VERSION ""

NS_ :

BS_:

BU_: Vector__XXX

BO_ 398 TxPDO_DeviceActual_14: 8 Vector__XXX
SG_ Device_dc_link_vol_14 : 0|16@1- (0.0625,0) [-2048|2047.9375] "V" Vector__XXX
SG_ Device_ambient_temp_14 : 16|16@1- (0.0625,0) [-2048|2047.9375] "°C" Vector__XXX
SG_ Device_dc_link_power_14 : 32|16@1- (0.016,0) [-524.288|524.272] "kW" Vector__XXX

BO_ 385 TxPDO_DeviceActual_1: 8 Vector__XXX
SG_ Device_dc_link_vol_1 : 0|16@1- (0.0625,0) [-2048|2047.9375] "V" Vector__XXX
SG_ Device_ambient_temp_1 : 16|16@1- (0.0625,0) [-2048|2047.9375] "°C" Vector__XXX
SG_ Device_dc_link_power_1 : 32|16@1- (0.016,0) [-524.288|524.272] "kW" Vector__XXX

BO_ 386 TxPDO_DeviceActual_2: 8 Vector__XXX
SG_ Device_dc_link_vol_2 : 0|16@1- (0.0625,0) [-2048|2047.9375] "V" Vector__XXX
SG_ Device_ambient_temp_2 : 16|16@1- (0.0625,0) [-2048|2047.9375] "°C" Vector__XXX
SG_ Device_dc_link_power_2 : 32|16@1- (0.016,0) [-524.288|524.272] "kW" Vector__XXX

BO_ 387 TxPDO_DeviceActual_3: 8 Vector__XXX
SG_ Device_dc_link_vol_3 : 0|16@1- (0.0625,0) [-2048|2047.9375] "V" Vector__XXX
SG_ Device_ambient_temp_3 : 16|16@1- (0.0625,0) [-2048|2047.9375] "°C" Vector__XXX
SG_ Device_dc_link_power_3 : 32|16@1- (0.016,0) [-524.288|524.272] "kW" Vector__XXX

BO_ 388 TxPDO_DeviceActual_4: 8 Vector__XXX
SG_ Device_dc_link_vol_4 : 0|16@1- (0.0625,0) [-2048|2047.9375] "V" Vector__XXX
SG_ Device_ambient_temp_4 : 16|16@1- (0.0625,0) [-2048|2047.9375] "°C" Vector__XXX
SG_ Device_dc_link_power_4 : 32|16@1- (0.016,0) [-524.288|524.272] "kW" Vector__XXX

BO_ 389 TxPDO_DeviceActual_5: 8 Vector__XXX
SG_ Device_dc_link_vol_5 : 0|16@1- (0.0625,0) [-2048|2047.9375] "V" Vector__XXX
SG_ Device_ambient_temp_5 : 16|16@1- (0.0625,0) [-2048|2047.9375] "°C" Vector__XXX
SG_ Device_dc_link_power_5 : 32|16@1- (0.016,0) [-524.288|524.272] "kW" Vector__XXX

BO_ 390 TxPDO_DeviceActual_6: 8 Vector__XXX
SG_ Device_dc_link_vol_6 : 0|16@1- (0.0625,0) [-2048|2047.9375] "V" Vector__XXX
SG_ Device_ambient_temp_6 : 16|16@1- (0.0625,0) [-2048|2047.9375] "°C" Vector__XXX
SG_ Device_dc_link_power_6 : 32|16@1- (0.016,0) [-524.288|524.272] "kW" Vector__XXX

BO_ 391 TxPDO_DeviceActual_7: 8 Vector__XXX
SG_ Device_dc_link_vol_7 : 0|16@1- (0.0625,0) [-2048|2047.9375] "V" Vector__XXX
SG_ Device_ambient_temp_7 : 16|16@1- (0.0625,0) [-2048|2047.9375] "°C" Vector__XXX
SG_ Device_dc_link_power_7 : 32|16@1- (0.016,0) [-524.288|524.272] "kW" Vector__XXX

BO_ 392 TxPDO_DeviceActual_8: 8 Vector__XXX
SG_ Device_dc_link_vol_8 : 0|16@1- (0.0625,0) [-2048|2047.9375] "V" Vector__XXX
SG_ Device_ambient_temp_8 : 16|16@1- (0.0625,0) [-2048|2047.9375] "°C" Vector__XXX
SG_ Device_dc_link_power_8 : 32|16@1- (0.016,0) [-524.288|524.272] "kW" Vector__XXX

BO_ 393 TxPDO_DeviceActual_9: 8 Vector__XXX
SG_ Device_dc_link_vol_9 : 0|16@1- (0.0625,0) [-2048|2047.9375] "V" Vector__XXX
SG_ Device_ambient_temp_9 : 16|16@1- (0.0625,0) [-2048|2047.9375] "°C" Vector__XXX
SG_ Device_dc_link_power_9 : 32|16@1- (0.016,0) [-524.288|524.272] "kW" Vector__XXX

BO_ 394 TxPDO_DeviceActual_10: 8 Vector__XXX
SG_ Device_dc_link_vol_10 : 0|16@1- (0.0625,0) [-2048|2047.9375] "V" Vector__XXX
SG_ Device_ambient_temp_10 : 16|16@1- (0.0625,0) [-2048|2047.9375] "°C" Vector__XXX
SG_ Device_dc_link_power_10 : 32|16@1- (0.016,0) [-524.288|524.272] "kW" Vector__XXX

BO_ 395 TxPDO_DeviceActual_11: 8 Vector__XXX
SG_ Device_dc_link_vol_11 : 0|16@1- (0.0625,0) [-2048|2047.9375] "V" Vector__XXX
SG_ Device_ambient_temp_11 : 16|16@1- (0.0625,0) [-2048|2047.9375] "°C" Vector__XXX
SG_ Device_dc_link_power_11 : 32|16@1- (0.016,0) [-524.288|524.272] "kW" Vector__XXX

BO_ 396 TxPDO_DeviceActual_12: 8 Vector__XXX
SG_ Device_dc_link_vol_12 : 0|16@1- (0.0625,0) [-2048|2047.9375] "V" Vector__XXX
SG_ Device_ambient_temp_12 : 16|16@1- (0.0625,0) [-2048|2047.9375] "°C" Vector__XXX
SG_ Device_dc_link_power_12 : 32|16@1- (0.016,0) [-524.288|524.272] "kW" Vector__XXX

BO_ 397 TxPDO_DeviceActual_13: 8 Vector__XXX
SG_ Device_dc_link_vol_13 : 0|16@1- (0.0625,0) [-2048|2047.9375] "V" Vector__XXX
SG_ Device_ambient_temp_13 : 16|16@1- (0.0625,0) [-2048|2047.9375] "°C" Vector__XXX
SG_ Device_dc_link_power_13 : 32|16@1- (0.016,0) [-524.288|524.272] "kW" Vector__XXX

BO_ 462 TxPDO_InverterAStatus_14: 8 Vector__XXX
SG_ Inverter_A_Statusword_14 : 0|7@1+ (1,0) [0|127] "" Vector__XXX
SG_ EVENTBUFFER_NEW_EVENT : 16|1@1+ (1,0) [0|1] "" Vector__XXX
SG_ EVENTBUFFER_OVERFLOW : 17|1@1+ (1,0) [0|1] "" Vector__XXX
SG_ POWERMODULE_TRIPZONE_OVERCURRE : 18|1@1+ (1,0) [0|1] "" Vector__XXX
SG_ POWERMODULE_CURRENT_OFFSET_INI : 19|1@1+ (1,0) [0|1] "" Vector__XXX
SG_ POWERMODULE_TEMPSENSOR_ERROR : 20|1@1+ (1,0) [0|1] "" Vector__XXX
SG_ POWERMODULE_TEMPERATURE_WARNIN : 21|1@1+ (1,0) [0|1] "" Vector__XXX
SG_ POWERMODULE_OVERTEMPERATURE : 22|1@1+ (1,0) [0|1] "" Vector__XXX
SG_ POWERMODULE_IXT_FAULT : 23|1@1+ (1,0) [0|1] "" Vector__XXX
SG_ POWERMODULE_SW_OVERCURRENT : 24|1@1+ (1,0) [0|1] "" Vector__XXX
SG_ POWERMODULE_PATTERNDATA_INCONS : 25|1@1+ (1,0) [0|1] "" Vector__XXX
SG_ DCBUS_TRIPZONE_OVERVOLTAGE : 26|1@1+ (1,0) [0|1] "" Vector__XXX
SG_ DCBUS_SW_OVERVOLTAGE : 27|1@1+ (1,0) [0|1] "" Vector__XXX
SG_ DCBUS_SW_UNDERVOLTAGE : 28|1@1+ (1,0) [0|1] "" Vector__XXX
SG_ NEIGHBOUR_FAULT : 29|1@1+ (1,0) [0|1] "" Vector__XXX
SG_ MOTOR_TEMPSENSOR_ERROR : 30|1@1+ (1,0) [0|1] "" Vector__XXX
SG_ MOTOR_TEMPERATURE_WARNING : 31|1@1+ (1,0) [0|1] "" Vector__XXX
SG_ MOTOR_OVERTEMPERATURE : 32|1@1+ (1,0) [0|1] "" Vector__XXX
SG_ MOTOR_STATOR_FREQ_TO_HIGH : 33|1@1+ (1,0) [0|1] "" Vector__XXX
SG_ SUPPLYVOLTAGE_ERROR : 34|1@1+ (1,0) [0|1] "" Vector__XXX
SG_ RPDO_TIMEOUT : 35|1@1+ (1,0) [0|1] "" Vector__XXX
SG_ NMT_NOT_OPERATIONAL : 36|1@1+ (1,0) [0|1] "" Vector__XXX
SG_ TASKOVERRUN : 37|1@1+ (1,0) [0|1] "" Vector__XXX
SG_ NETSYNC_ERROR : 38|1@1+ (1,0) [0|1] "" Vector__XXX
SG_ POSDEVICE_SIGNAL_TO_LOW : 39|1@1+ (1,0) [0|1] "" Vector__XXX
SG_ POSDEVICE_SIGNAL_TO_HIGH : 40|1@1+ (1,0) [0|1] "" Vector__XXX
SG_ RESOLVER_CALIBRATION_FAILED : 41|1@1+ (1,0) [0|1] "" Vector__XXX
SG_ SYSTEM_FAULT : 42|1@1+ (1,0) [0|1] "" Vector__XXX
SG_ INTERLOCK_OPEN : 43|1@1+ (1,0) [0|1] "" Vector__XXX
SG_ APPC_HAS_GATE_DRIVER_DISABLED : 44|1@1+ (1,0) [0|1] "" Vector__XXX
SG_ MOTOR_STALL_ERROR : 45|1@1+ (1,0) [0|1] "" Vector__XXX
SG_ AMBIENT_TEMPERATURE_WARNING : 46|1@1+ (1,0) [0|1] "" Vector__XXX
SG_ AMBIENT_OVERTEMPERATURE : 47|1@1+ (1,0) [0|1] "" Vector__XXX
SG_ AMBIENT_TEMPSENSOR_ERROR : 48|1@1+ (1,0) [0|1] "" Vector__XXX
SG_ POWERMODULE_CLAMPING_TIMEOUT : 49|1@1+ (1,0) [0|1] "" Vector__XXX
SG_ DCBUS_RIPPLE_TO_HIGH : 50|1@1+ (1,0) [0|1] "" Vector__XXX
SG_ MOTOR_I2XT_WARNING : 51|1@1+ (1,0) [0|1] "" Vector__XXX
SG_ MOTOR_I2XT_ERROR : 52|1@1+ (1,0) [0|1] "" Vector__XXX
SG_ MOTOR_FIELDWEAKENING_ERROR : 53|1@1+ (1,0) [0|1] "" Vector__XXX
SG_ INVALID_PARAMETER_COMBINATION : 54|1@1+ (1,0) [0|1] "" Vector__XXX
SG_ PLUG_COVER_SENSOR_SIGNAL_LOW : 55|1@1+ (1,0) [0|1] "" Vector__XXX
SG_ MOTOR_CONNECTION_TEST_FAILED : 56|1@1+ (1,0) [0|1] "" Vector__XXX
SG_ POWERMODULE_IXT_WARNING : 57|1@1+ (1,0) [0|1] "" Vector__XXX
SG_ ISOLATION_FAULT : 58|1@1+ (1,0) [0|1] "" Vector__XXX

BO_ 449 TxPDO_InverterAStatus_1: 8 Vector__XXX
SG_ Inverter_A_Statusword_1 : 0|7@1+ (1,0) [0|127] "" Vector__XXX
SG_ EVENTBUFFER_NEW_EVENT : 16|1@1+ (1,0) [0|1] "" Vector__XXX
SG_ EVENTBUFFER_OVERFLOW : 17|1@1+ (1,0) [0|1] "" Vector__XXX
SG_ POWERMODULE_TRIPZONE_OVERCURRE : 18|1@1+ (1,0) [0|1] "" Vector__XXX
SG_ POWERMODULE_CURRENT_OFFSET_INI : 19|1@1+ (1,0) [0|1] "" Vector__XXX
SG_ POWERMODULE_TEMPSENSOR_ERROR : 20|1@1+ (1,0) [0|1] "" Vector__XXX
SG_ POWERMODULE_TEMPERATURE_WARNIN : 21|1@1+ (1,0) [0|1] "" Vector__XXX
SG_ POWERMODULE_OVERTEMPERATURE : 22|1@1+ (1,0) [0|1] "" Vector__XXX
SG_ POWERMODULE_IXT_FAULT : 23|1@1+ (1,0) [0|1] "" Vector__XXX
SG_ POWERMODULE_SW_OVERCURRENT : 24|1@1+ (1,0) [0|1] "" Vector__XXX
SG_ POWERMODULE_PATTERNDATA_INCONS : 25|1@1+ (1,0) [0|1] "" Vector__XXX
SG_ DCBUS_TRIPZONE_OVERVOLTAGE : 26|1@1+ (1,0) [0|1] "" Vector__XXX
SG_ DCBUS_SW_OVERVOLTAGE : 27|1@1+ (1,0) [0|1] "" Vector__XXX
SG_ DCBUS_SW_UNDERVOLTAGE : 28|1@1+ (1,0) [0|1] "" Vector__XXX
SG_ NEIGHBOUR_FAULT : 29|1@1+ (1,0) [0|1] "" Vector__XXX
SG_ MOTOR_TEMPSENSOR_ERROR : 30|1@1+ (1,0) [0|1] "" Vector__XXX
SG_ MOTOR_TEMPERATURE_WARNING : 31|1@1+ (1,0) [0|1] "" Vector__XXX
SG_ MOTOR_OVERTEMPERATURE : 32|1@1+ (1,0) [0|1] "" Vector__XXX
SG_ MOTOR_STATOR_FREQ_TO_HIGH : 33|1@1+ (1,0) [0|1] "" Vector__XXX
SG_ SUPPLYVOLTAGE_ERROR : 34|1@1+ (1,0) [0|1] "" Vector__XXX
SG_ RPDO_TIMEOUT : 35|1@1+ (1,0) [0|1] "" Vector__XXX
SG_ NMT_NOT_OPERATIONAL : 36|1@1+ (1,0) [0|1] "" Vector__XXX
SG_ TASKOVERRUN : 37|1@1+ (1,0) [0|1] "" Vector__XXX
SG_ NETSYNC_ERROR : 38|1@1+ (1,0) [0|1] "" Vector__XXX
SG_ POSDEVICE_SIGNAL_TO_LOW : 39|1@1+ (1,0) [0|1] "" Vector__XXX
SG_ POSDEVICE_SIGNAL_TO_HIGH : 40|1@1+ (1,0) [0|1] "" Vector__XXX
SG_ RESOLVER_CALIBRATION_FAILED : 41|1@1+ (1,0) [0|1] "" Vector__XXX
SG_ SYSTEM_FAULT : 42|1@1+ (1,0) [0|1] "" Vector__XXX
SG_ INTERLOCK_OPEN : 43|1@1+ (1,0) [0|1] "" Vector__XXX
SG_ APPC_HAS_GATE_DRIVER_DISABLED : 44|1@1+ (1,0) [0|1] "" Vector__XXX
SG_ MOTOR_STALL_ERROR : 45|1@1+ (1,0) [0|1] "" Vector__XXX
SG_ AMBIENT_TEMPERATURE_WARNING : 46|1@1+ (1,0) [0|1] "" Vector__XXX
SG_ AMBIENT_OVERTEMPERATURE : 47|1@1+ (1,0) [0|1] "" Vector__XXX
SG_ AMBIENT_TEMPSENSOR_ERROR : 48|1@1+ (1,0) [0|1] "" Vector__XXX
SG_ POWERMODULE_CLAMPING_TIMEOUT : 49|1@1+ (1,0) [0|1] "" Vector__XXX
SG_ DCBUS_RIPPLE_TO_HIGH : 50|1@1+ (1,0) [0|1] "" Vector__XXX
SG_ MOTOR_I2XT_WARNING : 51|1@1+ (1,0) [0|1] "" Vector__XXX
SG_ MOTOR_I2XT_ERROR : 52|1@1+ (1,0) [0|1] "" Vector__XXX
SG_ MOTOR_FIELDWEAKENING_ERROR : 53|1@1+ (1,0) [0|1] "" Vector__XXX
SG_ INVALID_PARAMETER_COMBINATION : 54|1@1+ (1,0) [0|1] "" Vector__XXX
SG_ PLUG_COVER_SENSOR_SIGNAL_LOW : 55|1@1+ (1,0) [0|1] "" Vector__XXX
SG_ MOTOR_CONNECTION_TEST_FAILED : 56|1@1+ (1,0) [0|1] "" Vector__XXX
SG_ POWERMODULE_IXT_WARNING : 57|1@1+ (1,0) [0|1] "" Vector__XXX
SG_ ISOLATION_FAULT : 58|1@1+ (1,0) [0|1] "" Vector__XXX

BO_ 450 TxPDO_InverterAStatus_2: 8 Vector__XXX
SG_ Inverter_A_Statusword_2 : 0|7@1+ (1,0) [0|127] "" Vector__XXX
SG_ EVENTBUFFER_NEW_EVENT : 16|1@1+ (1,0) [0|1] "" Vector__XXX
SG_ EVENTBUFFER_OVERFLOW : 17|1@1+ (1,0) [0|1] "" Vector__XXX
SG_ POWERMODULE_TRIPZONE_OVERCURRE : 18|1@1+ (1,0) [0|1] "" Vector__XXX
SG_ POWERMODULE_CURRENT_OFFSET_INI : 19|1@1+ (1,0) [0|1] "" Vector__XXX
SG_ POWERMODULE_TEMPSENSOR_ERROR : 20|1@1+ (1,0) [0|1] "" Vector__XXX
SG_ POWERMODULE_TEMPERATURE_WARNIN : 21|1@1+ (1,0) [0|1] "" Vector__XXX
SG_ POWERMODULE_OVERTEMPERATURE : 22|1@1+ (1,0) [0|1] "" Vector__XXX
SG_ POWERMODULE_IXT_FAULT : 23|1@1+ (1,0) [0|1] "" Vector__XXX
SG_ POWERMODULE_SW_OVERCURRENT : 24|1@1+ (1,0) [0|1] "" Vector__XXX
SG_ POWERMODULE_PATTERNDATA_INCONS : 25|1@1+ (1,0) [0|1] "" Vector__XXX
SG_ DCBUS_TRIPZONE_OVERVOLTAGE : 26|1@1+ (1,0) [0|1] "" Vector__XXX
SG_ DCBUS_SW_OVERVOLTAGE : 27|1@1+ (1,0) [0|1] "" Vector__XXX
SG_ DCBUS_SW_UNDERVOLTAGE : 28|1@1+ (1,0) [0|1] "" Vector__XXX
SG_ NEIGHBOUR_FAULT : 29|1@1+ (1,0) [0|1] "" Vector__XXX
SG_ MOTOR_TEMPSENSOR_ERROR : 30|1@1+ (1,0) [0|1] "" Vector__XXX
SG_ MOTOR_TEMPERATURE_WARNING : 31|1@1+ (1,0) [0|1] "" Vector__XXX
SG_ MOTOR_OVERTEMPERATURE : 32|1@1+ (1,0) [0|1] "" Vector__XXX
SG_ MOTOR_STATOR_FREQ_TO_HIGH : 33|1@1+ (1,0) [0|1] "" Vector__XXX
SG_ SUPPLYVOLTAGE_ERROR : 34|1@1+ (1,0) [0|1] "" Vector__XXX
SG_ RPDO_TIMEOUT : 35|1@1+ (1,0) [0|1] "" Vector__XXX
SG_ NMT_NOT_OPERATIONAL : 36|1@1+ (1,0) [0|1] "" Vector__XXX
SG_ TASKOVERRUN : 37|1@1+ (1,0) [0|1] "" Vector__XXX
SG_ NETSYNC_ERROR : 38|1@1+ (1,0) [0|1] "" Vector__XXX
SG_ POSDEVICE_SIGNAL_TO_LOW : 39|1@1+ (1,0) [0|1] "" Vector__XXX
SG_ POSDEVICE_SIGNAL_TO_HIGH : 40|1@1+ (1,0) [0|1] "" Vector__XXX
SG_ RESOLVER_CALIBRATION_FAILED : 41|1@1+ (1,0) [0|1] "" Vector__XXX
SG_ SYSTEM_FAULT : 42|1@1+ (1,0) [0|1] "" Vector__XXX
SG_ INTERLOCK_OPEN : 43|1@1+ (1,0) [0|1] "" Vector__XXX
SG_ APPC_HAS_GATE_DRIVER_DISABLED : 44|1@1+ (1,0) [0|1] "" Vector__XXX
SG_ MOTOR_STALL_ERROR : 45|1@1+ (1,0) [0|1] "" Vector__XXX
SG_ AMBIENT_TEMPERATURE_WARNING : 46|1@1+ (1,0) [0|1] "" Vector__XXX
SG_ AMBIENT_OVERTEMPERATURE : 47|1@1+ (1,0) [0|1] "" Vector__XXX
SG_ AMBIENT_TEMPSENSOR_ERROR : 48|1@1+ (1,0) [0|1] "" Vector__XXX
SG_ POWERMODULE_CLAMPING_TIMEOUT : 49|1@1+ (1,0) [0|1] "" Vector__XXX
SG_ DCBUS_RIPPLE_TO_HIGH : 50|1@1+ (1,0) [0|1] "" Vector__XXX
SG_ MOTOR_I2XT_WARNING : 51|1@1+ (1,0) [0|1] "" Vector__XXX
SG_ MOTOR_I2XT_ERROR : 52|1@1+ (1,0) [0|1] "" Vector__XXX
SG_ MOTOR_FIELDWEAKENING_ERROR : 53|1@1+ (1,0) [0|1] "" Vector__XXX
SG_ INVALID_PARAMETER_COMBINATION : 54|1@1+ (1,0) [0|1] "" Vector__XXX
SG_ PLUG_COVER_SENSOR_SIGNAL_LOW : 55|1@1+ (1,0) [0|1] "" Vector__XXX
SG_ MOTOR_CONNECTION_TEST_FAILED : 56|1@1+ (1,0) [0|1] "" Vector__XXX
SG_ POWERMODULE_IXT_WARNING : 57|1@1+ (1,0) [0|1] "" Vector__XXX
SG_ ISOLATION_FAULT : 58|1@1+ (1,0) [0|1] "" Vector__XXX

BO_ 451 TxPDO_InverterAStatus_3: 8 Vector__XXX
SG_ Inverter_A_Statusword_3 : 0|7@1+ (1,0) [0|127] "" Vector__XXX
SG_ EVENTBUFFER_NEW_EVENT : 16|1@1+ (1,0) [0|1] "" Vector__XXX
SG_ EVENTBUFFER_OVERFLOW : 17|1@1+ (1,0) [0|1] "" Vector__XXX
SG_ POWERMODULE_TRIPZONE_OVERCURRE : 18|1@1+ (1,0) [0|1] "" Vector__XXX
SG_ POWERMODULE_CURRENT_OFFSET_INI : 19|1@1+ (1,0) [0|1] "" Vector__XXX
SG_ POWERMODULE_TEMPSENSOR_ERROR : 20|1@1+ (1,0) [0|1] "" Vector__XXX
SG_ POWERMODULE_TEMPERATURE_WARNIN : 21|1@1+ (1,0) [0|1] "" Vector__XXX
SG_ POWERMODULE_OVERTEMPERATURE : 22|1@1+ (1,0) [0|1] "" Vector__XXX
SG_ POWERMODULE_IXT_FAULT : 23|1@1+ (1,0) [0|1] "" Vector__XXX
SG_ POWERMODULE_SW_OVERCURRENT : 24|1@1+ (1,0) [0|1] "" Vector__XXX
SG_ POWERMODULE_PATTERNDATA_INCONS : 25|1@1+ (1,0) [0|1] "" Vector__XXX
SG_ DCBUS_TRIPZONE_OVERVOLTAGE : 26|1@1+ (1,0) [0|1] "" Vector__XXX
SG_ DCBUS_SW_OVERVOLTAGE : 27|1@1+ (1,0) [0|1] "" Vector__XXX
SG_ DCBUS_SW_UNDERVOLTAGE : 28|1@1+ (1,0) [0|1] "" Vector__XXX
SG_ NEIGHBOUR_FAULT : 29|1@1+ (1,0) [0|1] "" Vector__XXX
SG_ MOTOR_TEMPSENSOR_ERROR : 30|1@1+ (1,0) [0|1] "" Vector__XXX
SG_ MOTOR_TEMPERATURE_WARNING : 31|1@1+ (1,0) [0|1] "" Vector__XXX
SG_ MOTOR_OVERTEMPERATURE : 32|1@1+ (1,0) [0|1] "" Vector__XXX
SG_ MOTOR_STATOR_FREQ_TO_HIGH : 33|1@1+ (1,0) [0|1] "" Vector__XXX
SG_ SUPPLYVOLTAGE_ERROR : 34|1@1+ (1,0) [0|1] "" Vector__XXX
SG_ RPDO_TIMEOUT : 35|1@1+ (1,0) [0|1] "" Vector__XXX
SG_ NMT_NOT_OPERATIONAL : 36|1@1+ (1,0) [0|1] "" Vector__XXX
SG_ TASKOVERRUN : 37|1@1+ (1,0) [0|1] "" Vector__XXX
SG_ NETSYNC_ERROR : 38|1@1+ (1,0) [0|1] "" Vector__XXX
SG_ POSDEVICE_SIGNAL_TO_LOW : 39|1@1+ (1,0) [0|1] "" Vector__XXX
SG_ POSDEVICE_SIGNAL_TO_HIGH : 40|1@1+ (1,0) [0|1] "" Vector__XXX
SG_ RESOLVER_CALIBRATION_FAILED : 41|1@1+ (1,0) [0|1] "" Vector__XXX
SG_ SYSTEM_FAULT : 42|1@1+ (1,0) [0|1] "" Vector__XXX
SG_ INTERLOCK_OPEN : 43|1@1+ (1,0) [0|1] "" Vector__XXX
SG_ APPC_HAS_GATE_DRIVER_DISABLED : 44|1@1+ (1,0) [0|1] "" Vector__XXX
SG_ MOTOR_STALL_ERROR : 45|1@1+ (1,0) [0|1] "" Vector__XXX
SG_ AMBIENT_TEMPERATURE_WARNING : 46|1@1+ (1,0) [0|1] "" Vector__XXX
SG_ AMBIENT_OVERTEMPERATURE : 47|1@1+ (1,0) [0|1] "" Vector__XXX
SG_ AMBIENT_TEMPSENSOR_ERROR : 48|1@1+ (1,0) [0|1] "" Vector__XXX
SG_ POWERMODULE_CLAMPING_TIMEOUT : 49|1@1+ (1,0) [0|1] "" Vector__XXX
SG_ DCBUS_RIPPLE_TO_HIGH : 50|1@1+ (1,0) [0|1] "" Vector__XXX
SG_ MOTOR_I2XT_WARNING : 51|1@1+ (1,0) [0|1] "" Vector__XXX
SG_ MOTOR_I2XT_ERROR : 52|1@1+ (1,0) [0|1] "" Vector__XXX
SG_ MOTOR_FIELDWEAKENING_ERROR : 53|1@1+ (1,0) [0|1] "" Vector__XXX
SG_ INVALID_PARAMETER_COMBINATION : 54|1@1+ (1,0) [0|1] "" Vector__XXX
SG_ PLUG_COVER_SENSOR_SIGNAL_LOW : 55|1@1+ (1,0) [0|1] "" Vector__XXX
SG_ MOTOR_CONNECTION_TEST_FAILED : 56|1@1+ (1,0) [0|1] "" Vector__XXX
SG_ POWERMODULE_IXT_WARNING : 57|1@1+ (1,0) [0|1] "" Vector__XXX
SG_ ISOLATION_FAULT : 58|1@1+ (1,0) [0|1] "" Vector__XXX

BO_ 452 TxPDO_InverterAStatus_4: 8 Vector__XXX
SG_ Inverter_A_Statusword_4 : 0|7@1+ (1,0) [0|127] "" Vector__XXX
SG_ EVENTBUFFER_NEW_EVENT : 16|1@1+ (1,0) [0|1] "" Vector__XXX
SG_ EVENTBUFFER_OVERFLOW : 17|1@1+ (1,0) [0|1] "" Vector__XXX
SG_ POWERMODULE_TRIPZONE_OVERCURRE : 18|1@1+ (1,0) [0|1] "" Vector__XXX
SG_ POWERMODULE_CURRENT_OFFSET_INI : 19|1@1+ (1,0) [0|1] "" Vector__XXX
SG_ POWERMODULE_TEMPSENSOR_ERROR : 20|1@1+ (1,0) [0|1] "" Vector__XXX
SG_ POWERMODULE_TEMPERATURE_WARNIN : 21|1@1+ (1,0) [0|1] "" Vector__XXX
SG_ POWERMODULE_OVERTEMPERATURE : 22|1@1+ (1,0) [0|1] "" Vector__XXX
SG_ POWERMODULE_IXT_FAULT : 23|1@1+ (1,0) [0|1] "" Vector__XXX
SG_ POWERMODULE_SW_OVERCURRENT : 24|1@1+ (1,0) [0|1] "" Vector__XXX
SG_ POWERMODULE_PATTERNDATA_INCONS : 25|1@1+ (1,0) [0|1] "" Vector__XXX
SG_ DCBUS_TRIPZONE_OVERVOLTAGE : 26|1@1+ (1,0) [0|1] "" Vector__XXX
SG_ DCBUS_SW_OVERVOLTAGE : 27|1@1+ (1,0) [0|1] "" Vector__XXX
SG_ DCBUS_SW_UNDERVOLTAGE : 28|1@1+ (1,0) [0|1] "" Vector__XXX
SG_ NEIGHBOUR_FAULT : 29|1@1+ (1,0) [0|1] "" Vector__XXX
SG_ MOTOR_TEMPSENSOR_ERROR : 30|1@1+ (1,0) [0|1] "" Vector__XXX
SG_ MOTOR_TEMPERATURE_WARNING : 31|1@1+ (1,0) [0|1] "" Vector__XXX
SG_ MOTOR_OVERTEMPERATURE : 32|1@1+ (1,0) [0|1] "" Vector__XXX
SG_ MOTOR_STATOR_FREQ_TO_HIGH : 33|1@1+ (1,0) [0|1] "" Vector__XXX
SG_ SUPPLYVOLTAGE_ERROR : 34|1@1+ (1,0) [0|1] "" Vector__XXX
SG_ RPDO_TIMEOUT : 35|1@1+ (1,0) [0|1] "" Vector__XXX
SG_ NMT_NOT_OPERATIONAL : 36|1@1+ (1,0) [0|1] "" Vector__XXX
SG_ TASKOVERRUN : 37|1@1+ (1,0) [0|1] "" Vector__XXX
SG_ NETSYNC_ERROR : 38|1@1+ (1,0) [0|1] "" Vector__XXX
SG_ POSDEVICE_SIGNAL_TO_LOW : 39|1@1+ (1,0) [0|1] "" Vector__XXX
SG_ POSDEVICE_SIGNAL_TO_HIGH : 40|1@1+ (1,0) [0|1] "" Vector__XXX
SG_ RESOLVER_CALIBRATION_FAILED : 41|1@1+ (1,0) [0|1] "" Vector__XXX
SG_ SYSTEM_FAULT : 42|1@1+ (1,0) [0|1] "" Vector__XXX
SG_ INTERLOCK_OPEN : 43|1@1+ (1,0) [0|1] "" Vector__XXX
SG_ APPC_HAS_GATE_DRIVER_DISABLED : 44|1@1+ (1,0) [0|1] "" Vector__XXX
SG_ MOTOR_STALL_ERROR : 45|1@1+ (1,0) [0|1] "" Vector__XXX
SG_ AMBIENT_TEMPERATURE_WARNING : 46|1@1+ (1,0) [0|1] "" Vector__XXX
SG_ AMBIENT_OVERTEMPERATURE : 47|1@1+ (1,0) [0|1] "" Vector__XXX
SG_ AMBIENT_TEMPSENSOR_ERROR : 48|1@1+ (1,0) [0|1] "" Vector__XXX
SG_ POWERMODULE_CLAMPING_TIMEOUT : 49|1@1+ (1,0) [0|1] "" Vector__XXX
SG_ DCBUS_RIPPLE_TO_HIGH : 50|1@1+ (1,0) [0|1] "" Vector__XXX
SG_ MOTOR_I2XT_WARNING : 51|1@1+ (1,0) [0|1] "" Vector__XXX
SG_ MOTOR_I2XT_ERROR : 52|1@1+ (1,0) [0|1] "" Vector__XXX
SG_ MOTOR_FIELDWEAKENING_ERROR : 53|1@1+ (1,0) [0|1] "" Vector__XXX
SG_ INVALID_PARAMETER_COMBINATION : 54|1@1+ (1,0) [0|1] "" Vector__XXX
SG_ PLUG_COVER_SENSOR_SIGNAL_LOW : 55|1@1+ (1,0) [0|1] "" Vector__XXX
SG_ MOTOR_CONNECTION_TEST_FAILED : 56|1@1+ (1,0) [0|1] "" Vector__XXX
SG_ POWERMODULE_IXT_WARNING : 57|1@1+ (1,0) [0|1] "" Vector__XXX
SG_ ISOLATION_FAULT : 58|1@1+ (1,0) [0|1] "" Vector__XXX

BO_ 453 TxPDO_InverterAStatus_5: 8 Vector__XXX
SG_ Inverter_A_Statusword_5 : 0|7@1+ (1,0) [0|127] "" Vector__XXX
SG_ EVENTBUFFER_NEW_EVENT : 16|1@1+ (1,0) [0|1] "" Vector__XXX
SG_ EVENTBUFFER_OVERFLOW : 17|1@1+ (1,0) [0|1] "" Vector__XXX
SG_ POWERMODULE_TRIPZONE_OVERCURRE : 18|1@1+ (1,0) [0|1] "" Vector__XXX
SG_ POWERMODULE_CURRENT_OFFSET_INI : 19|1@1+ (1,0) [0|1] "" Vector__XXX
SG_ POWERMODULE_TEMPSENSOR_ERROR : 20|1@1+ (1,0) [0|1] "" Vector__XXX
SG_ POWERMODULE_TEMPERATURE_WARNIN : 21|1@1+ (1,0) [0|1] "" Vector__XXX
SG_ POWERMODULE_OVERTEMPERATURE : 22|1@1+ (1,0) [0|1] "" Vector__XXX
SG_ POWERMODULE_IXT_FAULT : 23|1@1+ (1,0) [0|1] "" Vector__XXX
SG_ POWERMODULE_SW_OVERCURRENT : 24|1@1+ (1,0) [0|1] "" Vector__XXX
SG_ POWERMODULE_PATTERNDATA_INCONS : 25|1@1+ (1,0) [0|1] "" Vector__XXX
SG_ DCBUS_TRIPZONE_OVERVOLTAGE : 26|1@1+ (1,0) [0|1] "" Vector__XXX
SG_ DCBUS_SW_OVERVOLTAGE : 27|1@1+ (1,0) [0|1] "" Vector__XXX
SG_ DCBUS_SW_UNDERVOLTAGE : 28|1@1+ (1,0) [0|1] "" Vector__XXX
SG_ NEIGHBOUR_FAULT : 29|1@1+ (1,0) [0|1] "" Vector__XXX
SG_ MOTOR_TEMPSENSOR_ERROR : 30|1@1+ (1,0) [0|1] "" Vector__XXX
SG_ MOTOR_TEMPERATURE_WARNING : 31|1@1+ (1,0) [0|1] "" Vector__XXX
SG_ MOTOR_OVERTEMPERATURE : 32|1@1+ (1,0) [0|1] "" Vector__XXX
SG_ MOTOR_STATOR_FREQ_TO_HIGH : 33|1@1+ (1,0) [0|1] "" Vector__XXX
SG_ SUPPLYVOLTAGE_ERROR : 34|1@1+ (1,0) [0|1] "" Vector__XXX
SG_ RPDO_TIMEOUT : 35|1@1+ (1,0) [0|1] "" Vector__XXX
SG_ NMT_NOT_OPERATIONAL : 36|1@1+ (1,0) [0|1] "" Vector__XXX
SG_ TASKOVERRUN : 37|1@1+ (1,0) [0|1] "" Vector__XXX
SG_ NETSYNC_ERROR : 38|1@1+ (1,0) [0|1] "" Vector__XXX
SG_ POSDEVICE_SIGNAL_TO_LOW : 39|1@1+ (1,0) [0|1] "" Vector__XXX
SG_ POSDEVICE_SIGNAL_TO_HIGH : 40|1@1+ (1,0) [0|1] "" Vector__XXX
SG_ RESOLVER_CALIBRATION_FAILED : 41|1@1+ (1,0) [0|1] "" Vector__XXX
SG_ SYSTEM_FAULT : 42|1@1+ (1,0) [0|1] "" Vector__XXX
SG_ INTERLOCK_OPEN : 43|1@1+ (1,0) [0|1] "" Vector__XXX
SG_ APPC_HAS_GATE_DRIVER_DISABLED : 44|1@1+ (1,0) [0|1] "" Vector__XXX
SG_ MOTOR_STALL_ERROR : 45|1@1+ (1,0) [0|1] "" Vector__XXX
SG_ AMBIENT_TEMPERATURE_WARNING : 46|1@1+ (1,0) [0|1] "" Vector__XXX
SG_ AMBIENT_OVERTEMPERATURE : 47|1@1+ (1,0) [0|1] "" Vector__XXX
SG_ AMBIENT_TEMPSENSOR_ERROR : 48|1@1+ (1,0) [0|1] "" Vector__XXX
SG_ POWERMODULE_CLAMPING_TIMEOUT : 49|1@1+ (1,0) [0|1] "" Vector__XXX
SG_ DCBUS_RIPPLE_TO_HIGH : 50|1@1+ (1,0) [0|1] "" Vector__XXX
SG_ MOTOR_I2XT_WARNING : 51|1@1+ (1,0) [0|1] "" Vector__XXX
SG_ MOTOR_I2XT_ERROR : 52|1@1+ (1,0) [0|1] "" Vector__XXX
SG_ MOTOR_FIELDWEAKENING_ERROR : 53|1@1+ (1,0) [0|1] "" Vector__XXX
SG_ INVALID_PARAMETER_COMBINATION : 54|1@1+ (1,0) [0|1] "" Vector__XXX
SG_ PLUG_COVER_SENSOR_SIGNAL_LOW : 55|1@1+ (1,0) [0|1] "" Vector__XXX
SG_ MOTOR_CONNECTION_TEST_FAILED : 56|1@1+ (1,0) [0|1] "" Vector__XXX
SG_ POWERMODULE_IXT_WARNING : 57|1@1+ (1,0) [0|1] "" Vector__XXX
SG_ ISOLATION_FAULT : 58|1@1+ (1,0) [0|1] "" Vector__XXX

BO_ 454 TxPDO_InverterAStatus_6: 8 Vector__XXX
SG_ Inverter_A_Statusword_6 : 0|7@1+ (1,0) [0|127] "" Vector__XXX
SG_ EVENTBUFFER_NEW_EVENT : 16|1@1+ (1,0) [0|1] "" Vector__XXX
SG_ EVENTBUFFER_OVERFLOW : 17|1@1+ (1,0) [0|1] "" Vector__XXX
SG_ POWERMODULE_TRIPZONE_OVERCURRE : 18|1@1+ (1,0) [0|1] "" Vector__XXX
SG_ POWERMODULE_CURRENT_OFFSET_INI : 19|1@1+ (1,0) [0|1] "" Vector__XXX
SG_ POWERMODULE_TEMPSENSOR_ERROR : 20|1@1+ (1,0) [0|1] "" Vector__XXX
SG_ POWERMODULE_TEMPERATURE_WARNIN : 21|1@1+ (1,0) [0|1] "" Vector__XXX
SG_ POWERMODULE_OVERTEMPERATURE : 22|1@1+ (1,0) [0|1] "" Vector__XXX
SG_ POWERMODULE_IXT_FAULT : 23|1@1+ (1,0) [0|1] "" Vector__XXX
SG_ POWERMODULE_SW_OVERCURRENT : 24|1@1+ (1,0) [0|1] "" Vector__XXX
SG_ POWERMODULE_PATTERNDATA_INCONS : 25|1@1+ (1,0) [0|1] "" Vector__XXX
SG_ DCBUS_TRIPZONE_OVERVOLTAGE : 26|1@1+ (1,0) [0|1] "" Vector__XXX
SG_ DCBUS_SW_OVERVOLTAGE : 27|1@1+ (1,0) [0|1] "" Vector__XXX
SG_ DCBUS_SW_UNDERVOLTAGE : 28|1@1+ (1,0) [0|1] "" Vector__XXX
SG_ NEIGHBOUR_FAULT : 29|1@1+ (1,0) [0|1] "" Vector__XXX
SG_ MOTOR_TEMPSENSOR_ERROR : 30|1@1+ (1,0) [0|1] "" Vector__XXX
SG_ MOTOR_TEMPERATURE_WARNING : 31|1@1+ (1,0) [0|1] "" Vector__XXX
SG_ MOTOR_OVERTEMPERATURE : 32|1@1+ (1,0) [0|1] "" Vector__XXX
SG_ MOTOR_STATOR_FREQ_TO_HIGH : 33|1@1+ (1,0) [0|1] "" Vector__XXX
SG_ SUPPLYVOLTAGE_ERROR : 34|1@1+ (1,0) [0|1] "" Vector__XXX
SG_ RPDO_TIMEOUT : 35|1@1+ (1,0) [0|1] "" Vector__XXX
SG_ NMT_NOT_OPERATIONAL : 36|1@1+ (1,0) [0|1] "" Vector__XXX
SG_ TASKOVERRUN : 37|1@1+ (1,0) [0|1] "" Vector__XXX
SG_ NETSYNC_ERROR : 38|1@1+ (1,0) [0|1] "" Vector__XXX
SG_ POSDEVICE_SIGNAL_TO_LOW : 39|1@1+ (1,0) [0|1] "" Vector__XXX
SG_ POSDEVICE_SIGNAL_TO_HIGH : 40|1@1+ (1,0) [0|1] "" Vector__XXX
SG_ RESOLVER_CALIBRATION_FAILED : 41|1@1+ (1,0) [0|1] "" Vector__XXX
SG_ SYSTEM_FAULT : 42|1@1+ (1,0) [0|1] "" Vector__XXX
SG_ INTERLOCK_OPEN : 43|1@1+ (1,0) [0|1] "" Vector__XXX
SG_ APPC_HAS_GATE_DRIVER_DISABLED : 44|1@1+ (1,0) [0|1] "" Vector__XXX
SG_ MOTOR_STALL_ERROR : 45|1@1+ (1,0) [0|1] "" Vector__XXX
SG_ AMBIENT_TEMPERATURE_WARNING : 46|1@1+ (1,0) [0|1] "" Vector__XXX
SG_ AMBIENT_OVERTEMPERATURE : 47|1@1+ (1,0) [0|1] "" Vector__XXX
SG_ AMBIENT_TEMPSENSOR_ERROR : 48|1@1+ (1,0) [0|1] "" Vector__XXX
SG_ POWERMODULE_CLAMPING_TIMEOUT : 49|1@1+ (1,0) [0|1] "" Vector__XXX
SG_ DCBUS_RIPPLE_TO_HIGH : 50|1@1+ (1,0) [0|1] "" Vector__XXX
SG_ MOTOR_I2XT_WARNING : 51|1@1+ (1,0) [0|1] "" Vector__XXX
SG_ MOTOR_I2XT_ERROR : 52|1@1+ (1,0) [0|1] "" Vector__XXX
SG_ MOTOR_FIELDWEAKENING_ERROR : 53|1@1+ (1,0) [0|1] "" Vector__XXX
SG_ INVALID_PARAMETER_COMBINATION : 54|1@1+ (1,0) [0|1] "" Vector__XXX
SG_ PLUG_COVER_SENSOR_SIGNAL_LOW : 55|1@1+ (1,0) [0|1] "" Vector__XXX
SG_ MOTOR_CONNECTION_TEST_FAILED : 56|1@1+ (1,0) [0|1] "" Vector__XXX
SG_ POWERMODULE_IXT_WARNING : 57|1@1+ (1,0) [0|1] "" Vector__XXX
SG_ ISOLATION_FAULT : 58|1@1+ (1,0) [0|1] "" Vector__XXX

BO_ 455 TxPDO_InverterAStatus_7: 8 Vector__XXX
SG_ Inverter_A_Statusword_7 : 0|7@1+ (1,0) [0|127] "" Vector__XXX
SG_ EVENTBUFFER_NEW_EVENT : 16|1@1+ (1,0) [0|1] "" Vector__XXX
SG_ EVENTBUFFER_OVERFLOW : 17|1@1+ (1,0) [0|1] "" Vector__XXX
SG_ POWERMODULE_TRIPZONE_OVERCURRE : 18|1@1+ (1,0) [0|1] "" Vector__XXX
SG_ POWERMODULE_CURRENT_OFFSET_INI : 19|1@1+ (1,0) [0|1] "" Vector__XXX
SG_ POWERMODULE_TEMPSENSOR_ERROR : 20|1@1+ (1,0) [0|1] "" Vector__XXX
SG_ POWERMODULE_TEMPERATURE_WARNIN : 21|1@1+ (1,0) [0|1] "" Vector__XXX
SG_ POWERMODULE_OVERTEMPERATURE : 22|1@1+ (1,0) [0|1] "" Vector__XXX
SG_ POWERMODULE_IXT_FAULT : 23|1@1+ (1,0) [0|1] "" Vector__XXX
SG_ POWERMODULE_SW_OVERCURRENT : 24|1@1+ (1,0) [0|1] "" Vector__XXX
SG_ POWERMODULE_PATTERNDATA_INCONS : 25|1@1+ (1,0) [0|1] "" Vector__XXX
SG_ DCBUS_TRIPZONE_OVERVOLTAGE : 26|1@1+ (1,0) [0|1] "" Vector__XXX
SG_ DCBUS_SW_OVERVOLTAGE : 27|1@1+ (1,0) [0|1] "" Vector__XXX
SG_ DCBUS_SW_UNDERVOLTAGE : 28|1@1+ (1,0) [0|1] "" Vector__XXX
SG_ NEIGHBOUR_FAULT : 29|1@1+ (1,0) [0|1] "" Vector__XXX
SG_ MOTOR_TEMPSENSOR_ERROR : 30|1@1+ (1,0) [0|1] "" Vector__XXX
SG_ MOTOR_TEMPERATURE_WARNING : 31|1@1+ (1,0) [0|1] "" Vector__XXX
SG_ MOTOR_OVERTEMPERATURE : 32|1@1+ (1,0) [0|1] "" Vector__XXX
SG_ MOTOR_STATOR_FREQ_TO_HIGH : 33|1@1+ (1,0) [0|1] "" Vector__XXX
SG_ SUPPLYVOLTAGE_ERROR : 34|1@1+ (1,0) [0|1] "" Vector__XXX
SG_ RPDO_TIMEOUT : 35|1@1+ (1,0) [0|1] "" Vector__XXX
SG_ NMT_NOT_OPERATIONAL : 36|1@1+ (1,0) [0|1] "" Vector__XXX
SG_ TASKOVERRUN : 37|1@1+ (1,0) [0|1] "" Vector__XXX
SG_ NETSYNC_ERROR : 38|1@1+ (1,0) [0|1] "" Vector__XXX
SG_ POSDEVICE_SIGNAL_TO_LOW : 39|1@1+ (1,0) [0|1] "" Vector__XXX
SG_ POSDEVICE_SIGNAL_TO_HIGH : 40|1@1+ (1,0) [0|1] "" Vector__XXX
SG_ RESOLVER_CALIBRATION_FAILED : 41|1@1+ (1,0) [0|1] "" Vector__XXX
SG_ SYSTEM_FAULT : 42|1@1+ (1,0) [0|1] "" Vector__XXX
SG_ INTERLOCK_OPEN : 43|1@1+ (1,0) [0|1] "" Vector__XXX
SG_ APPC_HAS_GATE_DRIVER_DISABLED : 44|1@1+ (1,0) [0|1] "" Vector__XXX
SG_ MOTOR_STALL_ERROR : 45|1@1+ (1,0) [0|1] "" Vector__XXX
SG_ AMBIENT_TEMPERATURE_WARNING : 46|1@1+ (1,0) [0|1] "" Vector__XXX
SG_ AMBIENT_OVERTEMPERATURE : 47|1@1+ (1,0) [0|1] "" Vector__XXX
SG_ AMBIENT_TEMPSENSOR_ERROR : 48|1@1+ (1,0) [0|1] "" Vector__XXX
SG_ POWERMODULE_CLAMPING_TIMEOUT : 49|1@1+ (1,0) [0|1] "" Vector__XXX
SG_ DCBUS_RIPPLE_TO_HIGH : 50|1@1+ (1,0) [0|1] "" Vector__XXX
SG_ MOTOR_I2XT_WARNING : 51|1@1+ (1,0) [0|1] "" Vector__XXX
SG_ MOTOR_I2XT_ERROR : 52|1@1+ (1,0) [0|1] "" Vector__XXX
SG_ MOTOR_FIELDWEAKENING_ERROR : 53|1@1+ (1,0) [0|1] "" Vector__XXX
SG_ INVALID_PARAMETER_COMBINATION : 54|1@1+ (1,0) [0|1] "" Vector__XXX
SG_ PLUG_COVER_SENSOR_SIGNAL_LOW : 55|1@1+ (1,0) [0|1] "" Vector__XXX
SG_ MOTOR_CONNECTION_TEST_FAILED : 56|1@1+ (1,0) [0|1] "" Vector__XXX
SG_ POWERMODULE_IXT_WARNING : 57|1@1+ (1,0) [0|1] "" Vector__XXX
SG_ ISOLATION_FAULT : 58|1@1+ (1,0) [0|1] "" Vector__XXX

BO_ 456 TxPDO_InverterAStatus_8: 8 Vector__XXX
SG_ Inverter_A_Statusword_8 : 0|7@1+ (1,0) [0|127] "" Vector__XXX
SG_ EVENTBUFFER_NEW_EVENT : 16|1@1+ (1,0) [0|1] "" Vector__XXX
SG_ EVENTBUFFER_OVERFLOW : 17|1@1+ (1,0) [0|1] "" Vector__XXX
SG_ POWERMODULE_TRIPZONE_OVERCURRE : 18|1@1+ (1,0) [0|1] "" Vector__XXX
SG_ POWERMODULE_CURRENT_OFFSET_INI : 19|1@1+ (1,0) [0|1] "" Vector__XXX
SG_ POWERMODULE_TEMPSENSOR_ERROR : 20|1@1+ (1,0) [0|1] "" Vector__XXX
SG_ POWERMODULE_TEMPERATURE_WARNIN : 21|1@1+ (1,0) [0|1] "" Vector__XXX
SG_ POWERMODULE_OVERTEMPERATURE : 22|1@1+ (1,0) [0|1] "" Vector__XXX
SG_ POWERMODULE_IXT_FAULT : 23|1@1+ (1,0) [0|1] "" Vector__XXX
SG_ POWERMODULE_SW_OVERCURRENT : 24|1@1+ (1,0) [0|1] "" Vector__XXX
SG_ POWERMODULE_PATTERNDATA_INCONS : 25|1@1+ (1,0) [0|1] "" Vector__XXX
SG_ DCBUS_TRIPZONE_OVERVOLTAGE : 26|1@1+ (1,0) [0|1] "" Vector__XXX
SG_ DCBUS_SW_OVERVOLTAGE : 27|1@1+ (1,0) [0|1] "" Vector__XXX
SG_ DCBUS_SW_UNDERVOLTAGE : 28|1@1+ (1,0) [0|1] "" Vector__XXX
SG_ NEIGHBOUR_FAULT : 29|1@1+ (1,0) [0|1] "" Vector__XXX
SG_ MOTOR_TEMPSENSOR_ERROR : 30|1@1+ (1,0) [0|1] "" Vector__XXX
SG_ MOTOR_TEMPERATURE_WARNING : 31|1@1+ (1,0) [0|1] "" Vector__XXX
SG_ MOTOR_OVERTEMPERATURE : 32|1@1+ (1,0) [0|1] "" Vector__XXX
SG_ MOTOR_STATOR_FREQ_TO_HIGH : 33|1@1+ (1,0) [0|1] "" Vector__XXX
SG_ SUPPLYVOLTAGE_ERROR : 34|1@1+ (1,0) [0|1] "" Vector__XXX
SG_ RPDO_TIMEOUT : 35|1@1+ (1,0) [0|1] "" Vector__XXX
SG_ NMT_NOT_OPERATIONAL : 36|1@1+ (1,0) [0|1] "" Vector__XXX
SG_ TASKOVERRUN : 37|1@1+ (1,0) [0|1] "" Vector__XXX
SG_ NETSYNC_ERROR : 38|1@1+ (1,0) [0|1] "" Vector__XXX
SG_ POSDEVICE_SIGNAL_TO_LOW : 39|1@1+ (1,0) [0|1] "" Vector__XXX
SG_ POSDEVICE_SIGNAL_TO_HIGH : 40|1@1+ (1,0) [0|1] "" Vector__XXX
SG_ RESOLVER_CALIBRATION_FAILED : 41|1@1+ (1,0) [0|1] "" Vector__XXX
SG_ SYSTEM_FAULT : 42|1@1+ (1,0) [0|1] "" Vector__XXX
SG_ INTERLOCK_OPEN : 43|1@1+ (1,0) [0|1] "" Vector__XXX
SG_ APPC_HAS_GATE_DRIVER_DISABLED : 44|1@1+ (1,0) [0|1] "" Vector__XXX
SG_ MOTOR_STALL_ERROR : 45|1@1+ (1,0) [0|1] "" Vector__XXX
SG_ AMBIENT_TEMPERATURE_WARNING : 46|1@1+ (1,0) [0|1] "" Vector__XXX
SG_ AMBIENT_OVERTEMPERATURE : 47|1@1+ (1,0) [0|1] "" Vector__XXX
SG_ AMBIENT_TEMPSENSOR_ERROR : 48|1@1+ (1,0) [0|1] "" Vector__XXX
SG_ POWERMODULE_CLAMPING_TIMEOUT : 49|1@1+ (1,0) [0|1] "" Vector__XXX
SG_ DCBUS_RIPPLE_TO_HIGH : 50|1@1+ (1,0) [0|1] "" Vector__XXX
SG_ MOTOR_I2XT_WARNING : 51|1@1+ (1,0) [0|1] "" Vector__XXX
SG_ MOTOR_I2XT_ERROR : 52|1@1+ (1,0) [0|1] "" Vector__XXX
SG_ MOTOR_FIELDWEAKENING_ERROR : 53|1@1+ (1,0) [0|1] "" Vector__XXX
SG_ INVALID_PARAMETER_COMBINATION : 54|1@1+ (1,0) [0|1] "" Vector__XXX
SG_ PLUG_COVER_SENSOR_SIGNAL_LOW : 55|1@1+ (1,0) [0|1] "" Vector__XXX
SG_ MOTOR_CONNECTION_TEST_FAILED : 56|1@1+ (1,0) [0|1] "" Vector__XXX
SG_ POWERMODULE_IXT_WARNING : 57|1@1+ (1,0) [0|1] "" Vector__XXX
SG_ ISOLATION_FAULT : 58|1@1+ (1,0) [0|1] "" Vector__XXX

BO_ 457 TxPDO_InverterAStatus_9: 8 Vector__XXX
SG_ Inverter_A_Statusword_9 : 0|7@1+ (1,0) [0|127] "" Vector__XXX
SG_ EVENTBUFFER_NEW_EVENT : 16|1@1+ (1,0) [0|1] "" Vector__XXX
SG_ EVENTBUFFER_OVERFLOW : 17|1@1+ (1,0) [0|1] "" Vector__XXX
SG_ POWERMODULE_TRIPZONE_OVERCURRE : 18|1@1+ (1,0) [0|1] "" Vector__XXX
SG_ POWERMODULE_CURRENT_OFFSET_INI : 19|1@1+ (1,0) [0|1] "" Vector__XXX
SG_ POWERMODULE_TEMPSENSOR_ERROR : 20|1@1+ (1,0) [0|1] "" Vector__XXX
SG_ POWERMODULE_TEMPERATURE_WARNIN : 21|1@1+ (1,0) [0|1] "" Vector__XXX
SG_ POWERMODULE_OVERTEMPERATURE : 22|1@1+ (1,0) [0|1] "" Vector__XXX
SG_ POWERMODULE_IXT_FAULT : 23|1@1+ (1,0) [0|1] "" Vector__XXX
SG_ POWERMODULE_SW_OVERCURRENT : 24|1@1+ (1,0) [0|1] "" Vector__XXX
SG_ POWERMODULE_PATTERNDATA_INCONS : 25|1@1+ (1,0) [0|1] "" Vector__XXX
SG_ DCBUS_TRIPZONE_OVERVOLTAGE : 26|1@1+ (1,0) [0|1] "" Vector__XXX
SG_ DCBUS_SW_OVERVOLTAGE : 27|1@1+ (1,0) [0|1] "" Vector__XXX
SG_ DCBUS_SW_UNDERVOLTAGE : 28|1@1+ (1,0) [0|1] "" Vector__XXX
SG_ NEIGHBOUR_FAULT : 29|1@1+ (1,0) [0|1] "" Vector__XXX
SG_ MOTOR_TEMPSENSOR_ERROR : 30|1@1+ (1,0) [0|1] "" Vector__XXX
SG_ MOTOR_TEMPERATURE_WARNING : 31|1@1+ (1,0) [0|1] "" Vector__XXX
SG_ MOTOR_OVERTEMPERATURE : 32|1@1+ (1,0) [0|1] "" Vector__XXX
SG_ MOTOR_STATOR_FREQ_TO_HIGH : 33|1@1+ (1,0) [0|1] "" Vector__XXX
SG_ SUPPLYVOLTAGE_ERROR : 34|1@1+ (1,0) [0|1] "" Vector__XXX
SG_ RPDO_TIMEOUT : 35|1@1+ (1,0) [0|1] "" Vector__XXX
SG_ NMT_NOT_OPERATIONAL : 36|1@1+ (1,0) [0|1] "" Vector__XXX
SG_ TASKOVERRUN : 37|1@1+ (1,0) [0|1] "" Vector__XXX
SG_ NETSYNC_ERROR : 38|1@1+ (1,0) [0|1] "" Vector__XXX
SG_ POSDEVICE_SIGNAL_TO_LOW : 39|1@1+ (1,0) [0|1] "" Vector__XXX
SG_ POSDEVICE_SIGNAL_TO_HIGH : 40|1@1+ (1,0) [0|1] "" Vector__XXX
SG_ RESOLVER_CALIBRATION_FAILED : 41|1@1+ (1,0) [0|1] "" Vector__XXX
SG_ SYSTEM_FAULT : 42|1@1+ (1,0) [0|1] "" Vector__XXX
SG_ INTERLOCK_OPEN : 43|1@1+ (1,0) [0|1] "" Vector__XXX
SG_ APPC_HAS_GATE_DRIVER_DISABLED : 44|1@1+ (1,0) [0|1] "" Vector__XXX
SG_ MOTOR_STALL_ERROR : 45|1@1+ (1,0) [0|1] "" Vector__XXX
SG_ AMBIENT_TEMPERATURE_WARNING : 46|1@1+ (1,0) [0|1] "" Vector__XXX
SG_ AMBIENT_OVERTEMPERATURE : 47|1@1+ (1,0) [0|1] "" Vector__XXX
SG_ AMBIENT_TEMPSENSOR_ERROR : 48|1@1+ (1,0) [0|1] "" Vector__XXX
SG_ POWERMODULE_CLAMPING_TIMEOUT : 49|1@1+ (1,0) [0|1] "" Vector__XXX
SG_ DCBUS_RIPPLE_TO_HIGH : 50|1@1+ (1,0) [0|1] "" Vector__XXX
SG_ MOTOR_I2XT_WARNING : 51|1@1+ (1,0) [0|1] "" Vector__XXX
SG_ MOTOR_I2XT_ERROR : 52|1@1+ (1,0) [0|1] "" Vector__XXX
SG_ MOTOR_FIELDWEAKENING_ERROR : 53|1@1+ (1,0) [0|1] "" Vector__XXX
SG_ INVALID_PARAMETER_COMBINATION : 54|1@1+ (1,0) [0|1] "" Vector__XXX
SG_ PLUG_COVER_SENSOR_SIGNAL_LOW : 55|1@1+ (1,0) [0|1] "" Vector__XXX
SG_ MOTOR_CONNECTION_TEST_FAILED : 56|1@1+ (1,0) [0|1] "" Vector__XXX
SG_ POWERMODULE_IXT_WARNING : 57|1@1+ (1,0) [0|1] "" Vector__XXX
SG_ ISOLATION_FAULT : 58|1@1+ (1,0) [0|1] "" Vector__XXX

BO_ 458 TxPDO_InverterAStatus_10: 8 Vector__XXX
SG_ Inverter_A_Statusword_10 : 0|7@1+ (1,0) [0|127] "" Vector__XXX
SG_ EVENTBUFFER_NEW_EVENT : 16|1@1+ (1,0) [0|1] "" Vector__XXX
SG_ EVENTBUFFER_OVERFLOW : 17|1@1+ (1,0) [0|1] "" Vector__XXX
SG_ POWERMODULE_TRIPZONE_OVERCURRE : 18|1@1+ (1,0) [0|1] "" Vector__XXX
SG_ POWERMODULE_CURRENT_OFFSET_INI : 19|1@1+ (1,0) [0|1] "" Vector__XXX
SG_ POWERMODULE_TEMPSENSOR_ERROR : 20|1@1+ (1,0) [0|1] "" Vector__XXX
SG_ POWERMODULE_TEMPERATURE_WARNIN : 21|1@1+ (1,0) [0|1] "" Vector__XXX
SG_ POWERMODULE_OVERTEMPERATURE : 22|1@1+ (1,0) [0|1] "" Vector__XXX
SG_ POWERMODULE_IXT_FAULT : 23|1@1+ (1,0) [0|1] "" Vector__XXX
SG_ POWERMODULE_SW_OVERCURRENT : 24|1@1+ (1,0) [0|1] "" Vector__XXX
SG_ POWERMODULE_PATTERNDATA_INCONS : 25|1@1+ (1,0) [0|1] "" Vector__XXX
SG_ DCBUS_TRIPZONE_OVERVOLTAGE : 26|1@1+ (1,0) [0|1] "" Vector__XXX
SG_ DCBUS_SW_OVERVOLTAGE : 27|1@1+ (1,0) [0|1] "" Vector__XXX
SG_ DCBUS_SW_UNDERVOLTAGE : 28|1@1+ (1,0) [0|1] "" Vector__XXX
SG_ NEIGHBOUR_FAULT : 29|1@1+ (1,0) [0|1] "" Vector__XXX
SG_ MOTOR_TEMPSENSOR_ERROR : 30|1@1+ (1,0) [0|1] "" Vector__XXX
SG_ MOTOR_TEMPERATURE_WARNING : 31|1@1+ (1,0) [0|1] "" Vector__XXX
SG_ MOTOR_OVERTEMPERATURE : 32|1@1+ (1,0) [0|1] "" Vector__XXX
SG_ MOTOR_STATOR_FREQ_TO_HIGH : 33|1@1+ (1,0) [0|1] "" Vector__XXX
SG_ SUPPLYVOLTAGE_ERROR : 34|1@1+ (1,0) [0|1] "" Vector__XXX
SG_ RPDO_TIMEOUT : 35|1@1+ (1,0) [0|1] "" Vector__XXX
SG_ NMT_NOT_OPERATIONAL : 36|1@1+ (1,0) [0|1] "" Vector__XXX
SG_ TASKOVERRUN : 37|1@1+ (1,0) [0|1] "" Vector__XXX
SG_ NETSYNC_ERROR : 38|1@1+ (1,0) [0|1] "" Vector__XXX
SG_ POSDEVICE_SIGNAL_TO_LOW : 39|1@1+ (1,0) [0|1] "" Vector__XXX
SG_ POSDEVICE_SIGNAL_TO_HIGH : 40|1@1+ (1,0) [0|1] "" Vector__XXX
SG_ RESOLVER_CALIBRATION_FAILED : 41|1@1+ (1,0) [0|1] "" Vector__XXX
SG_ SYSTEM_FAULT : 42|1@1+ (1,0) [0|1] "" Vector__XXX
SG_ INTERLOCK_OPEN : 43|1@1+ (1,0) [0|1] "" Vector__XXX
SG_ APPC_HAS_GATE_DRIVER_DISABLED : 44|1@1+ (1,0) [0|1] "" Vector__XXX
SG_ MOTOR_STALL_ERROR : 45|1@1+ (1,0) [0|1] "" Vector__XXX
SG_ AMBIENT_TEMPERATURE_WARNING : 46|1@1+ (1,0) [0|1] "" Vector__XXX
SG_ AMBIENT_OVERTEMPERATURE : 47|1@1+ (1,0) [0|1] "" Vector__XXX
SG_ AMBIENT_TEMPSENSOR_ERROR : 48|1@1+ (1,0) [0|1] "" Vector__XXX
SG_ POWERMODULE_CLAMPING_TIMEOUT : 49|1@1+ (1,0) [0|1] "" Vector__XXX
SG_ DCBUS_RIPPLE_TO_HIGH : 50|1@1+ (1,0) [0|1] "" Vector__XXX
SG_ MOTOR_I2XT_WARNING : 51|1@1+ (1,0) [0|1] "" Vector__XXX
SG_ MOTOR_I2XT_ERROR : 52|1@1+ (1,0) [0|1] "" Vector__XXX
SG_ MOTOR_FIELDWEAKENING_ERROR : 53|1@1+ (1,0) [0|1] "" Vector__XXX
SG_ INVALID_PARAMETER_COMBINATION : 54|1@1+ (1,0) [0|1] "" Vector__XXX
SG_ PLUG_COVER_SENSOR_SIGNAL_LOW : 55|1@1+ (1,0) [0|1] "" Vector__XXX
SG_ MOTOR_CONNECTION_TEST_FAILED : 56|1@1+ (1,0) [0|1] "" Vector__XXX
SG_ POWERMODULE_IXT_WARNING : 57|1@1+ (1,0) [0|1] "" Vector__XXX
SG_ ISOLATION_FAULT : 58|1@1+ (1,0) [0|1] "" Vector__XXX

BO_ 459 TxPDO_InverterAStatus_11: 8 Vector__XXX
SG_ Inverter_A_Statusword_11 : 0|7@1+ (1,0) [0|127] "" Vector__XXX
SG_ EVENTBUFFER_NEW_EVENT : 16|1@1+ (1,0) [0|1] "" Vector__XXX
SG_ EVENTBUFFER_OVERFLOW : 17|1@1+ (1,0) [0|1] "" Vector__XXX
SG_ POWERMODULE_TRIPZONE_OVERCURRE : 18|1@1+ (1,0) [0|1] "" Vector__XXX
SG_ POWERMODULE_CURRENT_OFFSET_INI : 19|1@1+ (1,0) [0|1] "" Vector__XXX
SG_ POWERMODULE_TEMPSENSOR_ERROR : 20|1@1+ (1,0) [0|1] "" Vector__XXX
SG_ POWERMODULE_TEMPERATURE_WARNIN : 21|1@1+ (1,0) [0|1] "" Vector__XXX
SG_ POWERMODULE_OVERTEMPERATURE : 22|1@1+ (1,0) [0|1] "" Vector__XXX
SG_ POWERMODULE_IXT_FAULT : 23|1@1+ (1,0) [0|1] "" Vector__XXX
SG_ POWERMODULE_SW_OVERCURRENT : 24|1@1+ (1,0) [0|1] "" Vector__XXX
SG_ POWERMODULE_PATTERNDATA_INCONS : 25|1@1+ (1,0) [0|1] "" Vector__XXX
SG_ DCBUS_TRIPZONE_OVERVOLTAGE : 26|1@1+ (1,0) [0|1] "" Vector__XXX
SG_ DCBUS_SW_OVERVOLTAGE : 27|1@1+ (1,0) [0|1] "" Vector__XXX
SG_ DCBUS_SW_UNDERVOLTAGE : 28|1@1+ (1,0) [0|1] "" Vector__XXX
SG_ NEIGHBOUR_FAULT : 29|1@1+ (1,0) [0|1] "" Vector__XXX
SG_ MOTOR_TEMPSENSOR_ERROR : 30|1@1+ (1,0) [0|1] "" Vector__XXX
SG_ MOTOR_TEMPERATURE_WARNING : 31|1@1+ (1,0) [0|1] "" Vector__XXX
SG_ MOTOR_OVERTEMPERATURE : 32|1@1+ (1,0) [0|1] "" Vector__XXX
SG_ MOTOR_STATOR_FREQ_TO_HIGH : 33|1@1+ (1,0) [0|1] "" Vector__XXX
SG_ SUPPLYVOLTAGE_ERROR : 34|1@1+ (1,0) [0|1] "" Vector__XXX
SG_ RPDO_TIMEOUT : 35|1@1+ (1,0) [0|1] "" Vector__XXX
SG_ NMT_NOT_OPERATIONAL : 36|1@1+ (1,0) [0|1] "" Vector__XXX
SG_ TASKOVERRUN : 37|1@1+ (1,0) [0|1] "" Vector__XXX
SG_ NETSYNC_ERROR : 38|1@1+ (1,0) [0|1] "" Vector__XXX
SG_ POSDEVICE_SIGNAL_TO_LOW : 39|1@1+ (1,0) [0|1] "" Vector__XXX
SG_ POSDEVICE_SIGNAL_TO_HIGH : 40|1@1+ (1,0) [0|1] "" Vector__XXX
SG_ RESOLVER_CALIBRATION_FAILED : 41|1@1+ (1,0) [0|1] "" Vector__XXX
SG_ SYSTEM_FAULT : 42|1@1+ (1,0) [0|1] "" Vector__XXX
SG_ INTERLOCK_OPEN : 43|1@1+ (1,0) [0|1] "" Vector__XXX
SG_ APPC_HAS_GATE_DRIVER_DISABLED : 44|1@1+ (1,0) [0|1] "" Vector__XXX
SG_ MOTOR_STALL_ERROR : 45|1@1+ (1,0) [0|1] "" Vector__XXX
SG_ AMBIENT_TEMPERATURE_WARNING : 46|1@1+ (1,0) [0|1] "" Vector__XXX
SG_ AMBIENT_OVERTEMPERATURE : 47|1@1+ (1,0) [0|1] "" Vector__XXX
SG_ AMBIENT_TEMPSENSOR_ERROR : 48|1@1+ (1,0) [0|1] "" Vector__XXX
SG_ POWERMODULE_CLAMPING_TIMEOUT : 49|1@1+ (1,0) [0|1] "" Vector__XXX
SG_ DCBUS_RIPPLE_TO_HIGH : 50|1@1+ (1,0) [0|1] "" Vector__XXX
SG_ MOTOR_I2XT_WARNING : 51|1@1+ (1,0) [0|1] "" Vector__XXX
SG_ MOTOR_I2XT_ERROR : 52|1@1+ (1,0) [0|1] "" Vector__XXX
SG_ MOTOR_FIELDWEAKENING_ERROR : 53|1@1+ (1,0) [0|1] "" Vector__XXX
SG_ INVALID_PARAMETER_COMBINATION : 54|1@1+ (1,0) [0|1] "" Vector__XXX
SG_ PLUG_COVER_SENSOR_SIGNAL_LOW : 55|1@1+ (1,0) [0|1] "" Vector__XXX
SG_ MOTOR_CONNECTION_TEST_FAILED : 56|1@1+ (1,0) [0|1] "" Vector__XXX
SG_ POWERMODULE_IXT_WARNING : 57|1@1+ (1,0) [0|1] "" Vector__XXX
SG_ ISOLATION_FAULT : 58|1@1+ (1,0) [0|1] "" Vector__XXX

BO_ 460 TxPDO_InverterAStatus_12: 8 Vector__XXX
SG_ Inverter_A_Statusword_12 : 0|7@1+ (1,0) [0|127] "" Vector__XXX
SG_ EVENTBUFFER_NEW_EVENT : 16|1@1+ (1,0) [0|1] "" Vector__XXX
SG_ EVENTBUFFER_OVERFLOW : 17|1@1+ (1,0) [0|1] "" Vector__XXX
SG_ POWERMODULE_TRIPZONE_OVERCURRE : 18|1@1+ (1,0) [0|1] "" Vector__XXX
SG_ POWERMODULE_CURRENT_OFFSET_INI : 19|1@1+ (1,0) [0|1] "" Vector__XXX
SG_ POWERMODULE_TEMPSENSOR_ERROR : 20|1@1+ (1,0) [0|1] "" Vector__XXX
SG_ POWERMODULE_TEMPERATURE_WARNIN : 21|1@1+ (1,0) [0|1] "" Vector__XXX
SG_ POWERMODULE_OVERTEMPERATURE : 22|1@1+ (1,0) [0|1] "" Vector__XXX
SG_ POWERMODULE_IXT_FAULT : 23|1@1+ (1,0) [0|1] "" Vector__XXX
SG_ POWERMODULE_SW_OVERCURRENT : 24|1@1+ (1,0) [0|1] "" Vector__XXX
SG_ POWERMODULE_PATTERNDATA_INCONS : 25|1@1+ (1,0) [0|1] "" Vector__XXX
SG_ DCBUS_TRIPZONE_OVERVOLTAGE : 26|1@1+ (1,0) [0|1] "" Vector__XXX
SG_ DCBUS_SW_OVERVOLTAGE : 27|1@1+ (1,0) [0|1] "" Vector__XXX
SG_ DCBUS_SW_UNDERVOLTAGE : 28|1@1+ (1,0) [0|1] "" Vector__XXX
SG_ NEIGHBOUR_FAULT : 29|1@1+ (1,0) [0|1] "" Vector__XXX
SG_ MOTOR_TEMPSENSOR_ERROR : 30|1@1+ (1,0) [0|1] "" Vector__XXX
SG_ MOTOR_TEMPERATURE_WARNING : 31|1@1+ (1,0) [0|1] "" Vector__XXX
SG_ MOTOR_OVERTEMPERATURE : 32|1@1+ (1,0) [0|1] "" Vector__XXX
SG_ MOTOR_STATOR_FREQ_TO_HIGH : 33|1@1+ (1,0) [0|1] "" Vector__XXX
SG_ SUPPLYVOLTAGE_ERROR : 34|1@1+ (1,0) [0|1] "" Vector__XXX
SG_ RPDO_TIMEOUT : 35|1@1+ (1,0) [0|1] "" Vector__XXX
SG_ NMT_NOT_OPERATIONAL : 36|1@1+ (1,0) [0|1] "" Vector__XXX
SG_ TASKOVERRUN : 37|1@1+ (1,0) [0|1] "" Vector__XXX
SG_ NETSYNC_ERROR : 38|1@1+ (1,0) [0|1] "" Vector__XXX
SG_ POSDEVICE_SIGNAL_TO_LOW : 39|1@1+ (1,0) [0|1] "" Vector__XXX
SG_ POSDEVICE_SIGNAL_TO_HIGH : 40|1@1+ (1,0) [0|1] "" Vector__XXX
SG_ RESOLVER_CALIBRATION_FAILED : 41|1@1+ (1,0) [0|1] "" Vector__XXX
SG_ SYSTEM_FAULT : 42|1@1+ (1,0) [0|1] "" Vector__XXX
SG_ INTERLOCK_OPEN : 43|1@1+ (1,0) [0|1] "" Vector__XXX
SG_ APPC_HAS_GATE_DRIVER_DISABLED : 44|1@1+ (1,0) [0|1] "" Vector__XXX
SG_ MOTOR_STALL_ERROR : 45|1@1+ (1,0) [0|1] "" Vector__XXX
SG_ AMBIENT_TEMPERATURE_WARNING : 46|1@1+ (1,0) [0|1] "" Vector__XXX
SG_ AMBIENT_OVERTEMPERATURE : 47|1@1+ (1,0) [0|1] "" Vector__XXX
SG_ AMBIENT_TEMPSENSOR_ERROR : 48|1@1+ (1,0) [0|1] "" Vector__XXX
SG_ POWERMODULE_CLAMPING_TIMEOUT : 49|1@1+ (1,0) [0|1] "" Vector__XXX
SG_ DCBUS_RIPPLE_TO_HIGH : 50|1@1+ (1,0) [0|1] "" Vector__XXX
SG_ MOTOR_I2XT_WARNING : 51|1@1+ (1,0) [0|1] "" Vector__XXX
SG_ MOTOR_I2XT_ERROR : 52|1@1+ (1,0) [0|1] "" Vector__XXX
SG_ MOTOR_FIELDWEAKENING_ERROR : 53|1@1+ (1,0) [0|1] "" Vector__XXX
SG_ INVALID_PARAMETER_COMBINATION : 54|1@1+ (1,0) [0|1] "" Vector__XXX
SG_ PLUG_COVER_SENSOR_SIGNAL_LOW : 55|1@1+ (1,0) [0|1] "" Vector__XXX
SG_ MOTOR_CONNECTION_TEST_FAILED : 56|1@1+ (1,0) [0|1] "" Vector__XXX
SG_ POWERMODULE_IXT_WARNING : 57|1@1+ (1,0) [0|1] "" Vector__XXX
SG_ ISOLATION_FAULT : 58|1@1+ (1,0) [0|1] "" Vector__XXX

BO_ 461 TxPDO_InverterAStatus_13: 8 Vector__XXX
SG_ Inverter_A_Statusword_13 : 0|7@1+ (1,0) [0|127] "" Vector__XXX
SG_ EVENTBUFFER_NEW_EVENT : 16|1@1+ (1,0) [0|1] "" Vector__XXX
SG_ EVENTBUFFER_OVERFLOW : 17|1@1+ (1,0) [0|1] "" Vector__XXX
SG_ POWERMODULE_TRIPZONE_OVERCURRE : 18|1@1+ (1,0) [0|1] "" Vector__XXX
SG_ POWERMODULE_CURRENT_OFFSET_INI : 19|1@1+ (1,0) [0|1] "" Vector__XXX
SG_ POWERMODULE_TEMPSENSOR_ERROR : 20|1@1+ (1,0) [0|1] "" Vector__XXX
SG_ POWERMODULE_TEMPERATURE_WARNIN : 21|1@1+ (1,0) [0|1] "" Vector__XXX
SG_ POWERMODULE_OVERTEMPERATURE : 22|1@1+ (1,0) [0|1] "" Vector__XXX
SG_ POWERMODULE_IXT_FAULT : 23|1@1+ (1,0) [0|1] "" Vector__XXX
SG_ POWERMODULE_SW_OVERCURRENT : 24|1@1+ (1,0) [0|1] "" Vector__XXX
SG_ POWERMODULE_PATTERNDATA_INCONS : 25|1@1+ (1,0) [0|1] "" Vector__XXX
SG_ DCBUS_TRIPZONE_OVERVOLTAGE : 26|1@1+ (1,0) [0|1] "" Vector__XXX
SG_ DCBUS_SW_OVERVOLTAGE : 27|1@1+ (1,0) [0|1] "" Vector__XXX
SG_ DCBUS_SW_UNDERVOLTAGE : 28|1@1+ (1,0) [0|1] "" Vector__XXX
SG_ NEIGHBOUR_FAULT : 29|1@1+ (1,0) [0|1] "" Vector__XXX
SG_ MOTOR_TEMPSENSOR_ERROR : 30|1@1+ (1,0) [0|1] "" Vector__XXX
SG_ MOTOR_TEMPERATURE_WARNING : 31|1@1+ (1,0) [0|1] "" Vector__XXX
SG_ MOTOR_OVERTEMPERATURE : 32|1@1+ (1,0) [0|1] "" Vector__XXX
SG_ MOTOR_STATOR_FREQ_TO_HIGH : 33|1@1+ (1,0) [0|1] "" Vector__XXX
SG_ SUPPLYVOLTAGE_ERROR : 34|1@1+ (1,0) [0|1] "" Vector__XXX
SG_ RPDO_TIMEOUT : 35|1@1+ (1,0) [0|1] "" Vector__XXX
SG_ NMT_NOT_OPERATIONAL : 36|1@1+ (1,0) [0|1] "" Vector__XXX
SG_ TASKOVERRUN : 37|1@1+ (1,0) [0|1] "" Vector__XXX
SG_ NETSYNC_ERROR : 38|1@1+ (1,0) [0|1] "" Vector__XXX
SG_ POSDEVICE_SIGNAL_TO_LOW : 39|1@1+ (1,0) [0|1] "" Vector__XXX
SG_ POSDEVICE_SIGNAL_TO_HIGH : 40|1@1+ (1,0) [0|1] "" Vector__XXX
SG_ RESOLVER_CALIBRATION_FAILED : 41|1@1+ (1,0) [0|1] "" Vector__XXX
SG_ SYSTEM_FAULT : 42|1@1+ (1,0) [0|1] "" Vector__XXX
SG_ INTERLOCK_OPEN : 43|1@1+ (1,0) [0|1] "" Vector__XXX
SG_ APPC_HAS_GATE_DRIVER_DISABLED : 44|1@1+ (1,0) [0|1] "" Vector__XXX
SG_ MOTOR_STALL_ERROR : 45|1@1+ (1,0) [0|1] "" Vector__XXX
SG_ AMBIENT_TEMPERATURE_WARNING : 46|1@1+ (1,0) [0|1] "" Vector__XXX
SG_ AMBIENT_OVERTEMPERATURE : 47|1@1+ (1,0) [0|1] "" Vector__XXX
SG_ AMBIENT_TEMPSENSOR_ERROR : 48|1@1+ (1,0) [0|1] "" Vector__XXX
SG_ POWERMODULE_CLAMPING_TIMEOUT : 49|1@1+ (1,0) [0|1] "" Vector__XXX
SG_ DCBUS_RIPPLE_TO_HIGH : 50|1@1+ (1,0) [0|1] "" Vector__XXX
SG_ MOTOR_I2XT_WARNING : 51|1@1+ (1,0) [0|1] "" Vector__XXX
SG_ MOTOR_I2XT_ERROR : 52|1@1+ (1,0) [0|1] "" Vector__XXX
SG_ MOTOR_FIELDWEAKENING_ERROR : 53|1@1+ (1,0) [0|1] "" Vector__XXX
SG_ INVALID_PARAMETER_COMBINATION : 54|1@1+ (1,0) [0|1] "" Vector__XXX
SG_ PLUG_COVER_SENSOR_SIGNAL_LOW : 55|1@1+ (1,0) [0|1] "" Vector__XXX
SG_ MOTOR_CONNECTION_TEST_FAILED : 56|1@1+ (1,0) [0|1] "" Vector__XXX
SG_ POWERMODULE_IXT_WARNING : 57|1@1+ (1,0) [0|1] "" Vector__XXX
SG_ ISOLATION_FAULT : 58|1@1+ (1,0) [0|1] "" Vector__XXX

BO_ 590 TxPDO_MotorAActual1_14: 8 Vector__XXX
SG_ Motor_A_act_velocity_14 : 0|32@1- (6.103515625E-005,0) [-131072|131071.999938965] "rpm" Vector__XXX
SG_ Motor_A_act_torque_14 : 32|16@1- (0.1,0) [-3276.8|3276.7] "%" Vector__XXX
SG_ Motor_A_act_current_14 : 48|16@1- (0.015625,0) [-512|511.984375] "A" Vector__XXX

BO_ 577 TxPDO_MotorAActual1_1: 8 Vector__XXX
SG_ Motor_A_act_velocity_1 : 0|32@1- (6.103515625E-005,0) [-131072|131071.999938965] "rpm" Vector__XXX
SG_ Motor_A_act_torque_1 : 32|16@1- (0.1,0) [-3276.8|3276.7] "%" Vector__XXX
SG_ Motor_A_act_current_1 : 48|16@1- (0.015625,0) [-512|511.984375] "A" Vector__XXX

BO_ 578 TxPDO_MotorAActual1_2: 8 Vector__XXX
SG_ Motor_A_act_velocity_2 : 0|32@1- (6.103515625E-005,0) [-131072|131071.999938965] "rpm" Vector__XXX
SG_ Motor_A_act_torque_2 : 32|16@1- (0.1,0) [-3276.8|3276.7] "%" Vector__XXX
SG_ Motor_A_act_current_2 : 48|16@1- (0.015625,0) [-512|511.984375] "A" Vector__XXX

BO_ 579 TxPDO_MotorAActual1_3: 8 Vector__XXX
SG_ Motor_A_act_velocity_3 : 0|32@1- (6.103515625E-005,0) [-131072|131071.999938965] "rpm" Vector__XXX
SG_ Motor_A_act_torque_3 : 32|16@1- (0.1,0) [-3276.8|3276.7] "%" Vector__XXX
SG_ Motor_A_act_current_3 : 48|16@1- (0.015625,0) [-512|511.984375] "A" Vector__XXX

BO_ 580 TxPDO_MotorAActual1_4: 8 Vector__XXX
SG_ Motor_A_act_velocity_4 : 0|32@1- (6.103515625E-005,0) [-131072|131071.999938965] "rpm" Vector__XXX
SG_ Motor_A_act_torque_4 : 32|16@1- (0.1,0) [-3276.8|3276.7] "%" Vector__XXX
SG_ Motor_A_act_current_4 : 48|16@1- (0.015625,0) [-512|511.984375] "A" Vector__XXX

BO_ 581 TxPDO_MotorAActual1_5: 8 Vector__XXX
SG_ Motor_A_act_velocity_5 : 0|32@1- (6.103515625E-005,0) [-131072|131071.999938965] "rpm" Vector__XXX
SG_ Motor_A_act_torque_5 : 32|16@1- (0.1,0) [-3276.8|3276.7] "%" Vector__XXX
SG_ Motor_A_act_current_5 : 48|16@1- (0.015625,0) [-512|511.984375] "A" Vector__XXX

BO_ 582 TxPDO_MotorAActual1_6: 8 Vector__XXX
SG_ Motor_A_act_velocity_6 : 0|32@1- (6.103515625E-005,0) [-131072|131071.999938965] "rpm" Vector__XXX
SG_ Motor_A_act_torque_6 : 32|16@1- (0.1,0) [-3276.8|3276.7] "%" Vector__XXX
SG_ Motor_A_act_current_6 : 48|16@1- (0.015625,0) [-512|511.984375] "A" Vector__XXX

BO_ 583 TxPDO_MotorAActual1_7: 8 Vector__XXX
SG_ Motor_A_act_velocity_7 : 0|32@1- (6.103515625E-005,0) [-131072|131071.999938965] "rpm" Vector__XXX
SG_ Motor_A_act_torque_7 : 32|16@1- (0.1,0) [-3276.8|3276.7] "%" Vector__XXX
SG_ Motor_A_act_current_7 : 48|16@1- (0.015625,0) [-512|511.984375] "A" Vector__XXX

BO_ 584 TxPDO_MotorAActual1_8: 8 Vector__XXX
SG_ Motor_A_act_velocity_8 : 0|32@1- (6.103515625E-005,0) [-131072|131071.999938965] "rpm" Vector__XXX
SG_ Motor_A_act_torque_8 : 32|16@1- (0.1,0) [-3276.8|3276.7] "%" Vector__XXX
SG_ Motor_A_act_current_8 : 48|16@1- (0.015625,0) [-512|511.984375] "A" Vector__XXX

BO_ 585 TxPDO_MotorAActual1_9: 8 Vector__XXX
SG_ Motor_A_act_velocity_9 : 0|32@1- (6.103515625E-005,0) [-131072|131071.999938965] "rpm" Vector__XXX
SG_ Motor_A_act_torque_9 : 32|16@1- (0.1,0) [-3276.8|3276.7] "%" Vector__XXX
SG_ Motor_A_act_current_9 : 48|16@1- (0.015625,0) [-512|511.984375] "A" Vector__XXX

BO_ 586 TxPDO_MotorAActual1_10: 8 Vector__XXX
SG_ Motor_A_act_velocity_10 : 0|32@1- (6.103515625E-005,0) [-131072|131071.999938965] "rpm" Vector__XXX
SG_ Motor_A_act_torque_10 : 32|16@1- (0.1,0) [-3276.8|3276.7] "%" Vector__XXX
SG_ Motor_A_act_current_10 : 48|16@1- (0.015625,0) [-512|511.984375] "A" Vector__XXX

BO_ 587 TxPDO_MotorAActual1_11: 8 Vector__XXX
SG_ Motor_A_act_velocity_11 : 0|32@1- (6.103515625E-005,0) [-131072|131071.999938965] "rpm" Vector__XXX
SG_ Motor_A_act_torque_11 : 32|16@1- (0.1,0) [-3276.8|3276.7] "%" Vector__XXX
SG_ Motor_A_act_current_11 : 48|16@1- (0.015625,0) [-512|511.984375] "A" Vector__XXX

BO_ 588 TxPDO_MotorAActual1_12: 8 Vector__XXX
SG_ Motor_A_act_velocity_12 : 0|32@1- (6.103515625E-005,0) [-131072|131071.999938965] "rpm" Vector__XXX
SG_ Motor_A_act_torque_12 : 32|16@1- (0.1,0) [-3276.8|3276.7] "%" Vector__XXX
SG_ Motor_A_act_current_12 : 48|16@1- (0.015625,0) [-512|511.984375] "A" Vector__XXX

BO_ 589 TxPDO_MotorAActual1_13: 8 Vector__XXX
SG_ Motor_A_act_velocity_13 : 0|32@1- (6.103515625E-005,0) [-131072|131071.999938965] "rpm" Vector__XXX
SG_ Motor_A_act_torque_13 : 32|16@1- (0.1,0) [-3276.8|3276.7] "%" Vector__XXX
SG_ Motor_A_act_current_13 : 48|16@1- (0.015625,0) [-512|511.984375] "A" Vector__XXX

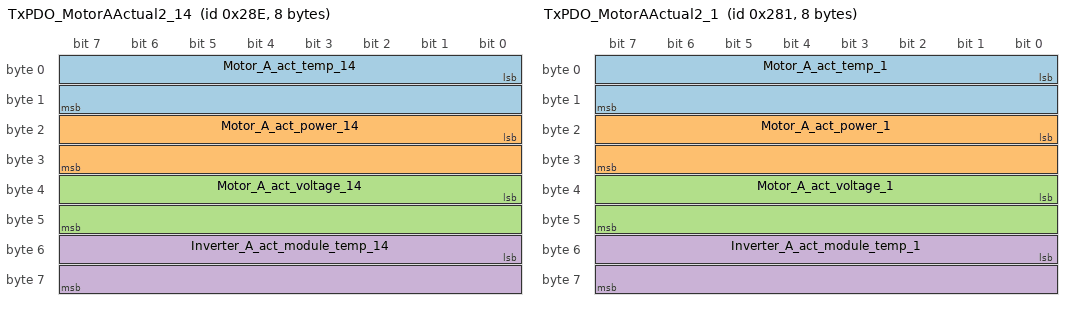
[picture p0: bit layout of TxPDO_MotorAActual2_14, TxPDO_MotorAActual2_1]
BO_ 654 TxPDO_MotorAActual2_14: 8 Vector__XXX
SG_ Motor_A_act_temp_14 : 0|16@1- (0.0625,0) [-2048|2047.9375] "°C" Vector__XXX
SG_ Motor_A_act_power_14 : 16|16@1- (0.016,0) [-524.288|524.272] "kW" Vector__XXX
SG_ Motor_A_act_voltage_14 : 32|16@1- (0.0625,0) [-2048|2047.9375] "V" Vector__XXX
SG_ Inverter_A_act_module_temp_14 : 48|16@1- (0.0625,0) [-2048|2047.9375] "°C" Vector__XXX

BO_ 641 TxPDO_MotorAActual2_1: 8 Vector__XXX
SG_ Motor_A_act_temp_1 : 0|16@1- (0.0625,0) [-2048|2047.9375] "°C" Vector__XXX
SG_ Motor_A_act_power_1 : 16|16@1- (0.016,0) [-524.288|524.272] "kW" Vector__XXX
SG_ Motor_A_act_voltage_1 : 32|16@1- (0.0625,0) [-2048|2047.9375] "V" Vector__XXX
SG_ Inverter_A_act_module_temp_1 : 48|16@1- (0.0625,0) [-2048|2047.9375] "°C" Vector__XXX

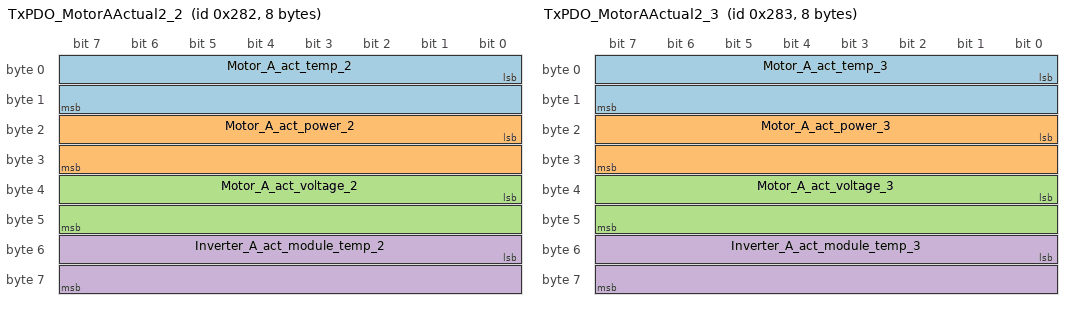
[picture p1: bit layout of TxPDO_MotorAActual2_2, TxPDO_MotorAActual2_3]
BO_ 642 TxPDO_MotorAActual2_2: 8 Vector__XXX
SG_ Motor_A_act_temp_2 : 0|16@1- (0.0625,0) [-2048|2047.9375] "°C" Vector__XXX
SG_ Motor_A_act_power_2 : 16|16@1- (0.016,0) [-524.288|524.272] "kW" Vector__XXX
SG_ Motor_A_act_voltage_2 : 32|16@1- (0.0625,0) [-2048|2047.9375] "V" Vector__XXX
SG_ Inverter_A_act_module_temp_2 : 48|16@1- (0.0625,0) [-2048|2047.9375] "°C" Vector__XXX

BO_ 643 TxPDO_MotorAActual2_3: 8 Vector__XXX
SG_ Motor_A_act_temp_3 : 0|16@1- (0.0625,0) [-2048|2047.9375] "°C" Vector__XXX
SG_ Motor_A_act_power_3 : 16|16@1- (0.016,0) [-524.288|524.272] "kW" Vector__XXX
SG_ Motor_A_act_voltage_3 : 32|16@1- (0.0625,0) [-2048|2047.9375] "V" Vector__XXX
SG_ Inverter_A_act_module_temp_3 : 48|16@1- (0.0625,0) [-2048|2047.9375] "°C" Vector__XXX

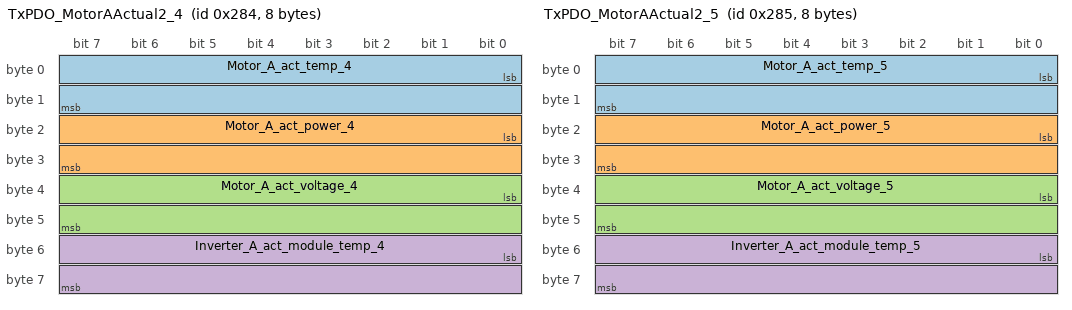
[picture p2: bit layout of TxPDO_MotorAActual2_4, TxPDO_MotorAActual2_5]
BO_ 644 TxPDO_MotorAActual2_4: 8 Vector__XXX
SG_ Motor_A_act_temp_4 : 0|16@1- (0.0625,0) [-2048|2047.9375] "°C" Vector__XXX
SG_ Motor_A_act_power_4 : 16|16@1- (0.016,0) [-524.288|524.272] "kW" Vector__XXX
SG_ Motor_A_act_voltage_4 : 32|16@1- (0.0625,0) [-2048|2047.9375] "V" Vector__XXX
SG_ Inverter_A_act_module_temp_4 : 48|16@1- (0.0625,0) [-2048|2047.9375] "°C" Vector__XXX

BO_ 645 TxPDO_MotorAActual2_5: 8 Vector__XXX
SG_ Motor_A_act_temp_5 : 0|16@1- (0.0625,0) [-2048|2047.9375] "°C" Vector__XXX
SG_ Motor_A_act_power_5 : 16|16@1- (0.016,0) [-524.288|524.272] "kW" Vector__XXX
SG_ Motor_A_act_voltage_5 : 32|16@1- (0.0625,0) [-2048|2047.9375] "V" Vector__XXX
SG_ Inverter_A_act_module_temp_5 : 48|16@1- (0.0625,0) [-2048|2047.9375] "°C" Vector__XXX

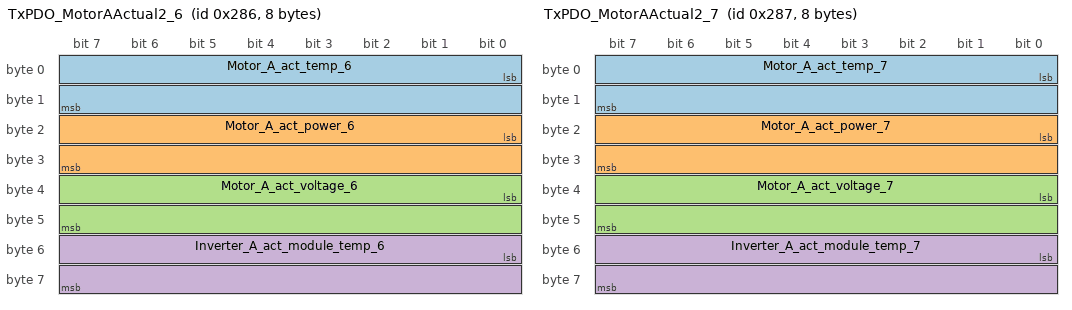
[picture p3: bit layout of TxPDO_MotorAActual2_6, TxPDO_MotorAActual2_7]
BO_ 646 TxPDO_MotorAActual2_6: 8 Vector__XXX
SG_ Motor_A_act_temp_6 : 0|16@1- (0.0625,0) [-2048|2047.9375] "°C" Vector__XXX
SG_ Motor_A_act_power_6 : 16|16@1- (0.016,0) [-524.288|524.272] "kW" Vector__XXX
SG_ Motor_A_act_voltage_6 : 32|16@1- (0.0625,0) [-2048|2047.9375] "V" Vector__XXX
SG_ Inverter_A_act_module_temp_6 : 48|16@1- (0.0625,0) [-2048|2047.9375] "°C" Vector__XXX

BO_ 647 TxPDO_MotorAActual2_7: 8 Vector__XXX
SG_ Motor_A_act_temp_7 : 0|16@1- (0.0625,0) [-2048|2047.9375] "°C" Vector__XXX
SG_ Motor_A_act_power_7 : 16|16@1- (0.016,0) [-524.288|524.272] "kW" Vector__XXX
SG_ Motor_A_act_voltage_7 : 32|16@1- (0.0625,0) [-2048|2047.9375] "V" Vector__XXX
SG_ Inverter_A_act_module_temp_7 : 48|16@1- (0.0625,0) [-2048|2047.9375] "°C" Vector__XXX

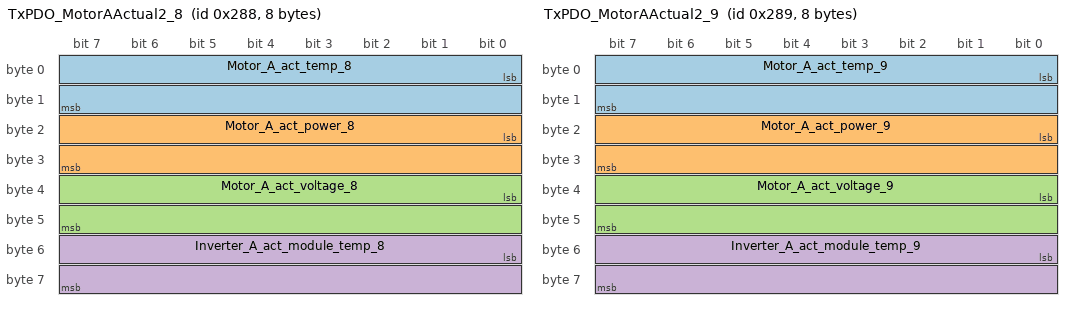
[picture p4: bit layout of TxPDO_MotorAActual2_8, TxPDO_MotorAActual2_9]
BO_ 648 TxPDO_MotorAActual2_8: 8 Vector__XXX
SG_ Motor_A_act_temp_8 : 0|16@1- (0.0625,0) [-2048|2047.9375] "°C" Vector__XXX
SG_ Motor_A_act_power_8 : 16|16@1- (0.016,0) [-524.288|524.272] "kW" Vector__XXX
SG_ Motor_A_act_voltage_8 : 32|16@1- (0.0625,0) [-2048|2047.9375] "V" Vector__XXX
SG_ Inverter_A_act_module_temp_8 : 48|16@1- (0.0625,0) [-2048|2047.9375] "°C" Vector__XXX

BO_ 649 TxPDO_MotorAActual2_9: 8 Vector__XXX
SG_ Motor_A_act_temp_9 : 0|16@1- (0.0625,0) [-2048|2047.9375] "°C" Vector__XXX
SG_ Motor_A_act_power_9 : 16|16@1- (0.016,0) [-524.288|524.272] "kW" Vector__XXX
SG_ Motor_A_act_voltage_9 : 32|16@1- (0.0625,0) [-2048|2047.9375] "V" Vector__XXX
SG_ Inverter_A_act_module_temp_9 : 48|16@1- (0.0625,0) [-2048|2047.9375] "°C" Vector__XXX

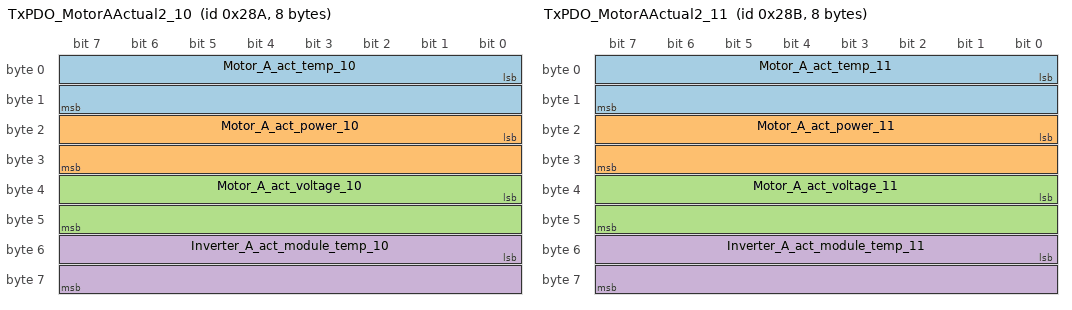
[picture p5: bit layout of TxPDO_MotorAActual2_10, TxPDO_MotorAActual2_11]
BO_ 650 TxPDO_MotorAActual2_10: 8 Vector__XXX
SG_ Motor_A_act_temp_10 : 0|16@1- (0.0625,0) [-2048|2047.9375] "°C" Vector__XXX
SG_ Motor_A_act_power_10 : 16|16@1- (0.016,0) [-524.288|524.272] "kW" Vector__XXX
SG_ Motor_A_act_voltage_10 : 32|16@1- (0.0625,0) [-2048|2047.9375] "V" Vector__XXX
SG_ Inverter_A_act_module_temp_10 : 48|16@1- (0.0625,0) [-2048|2047.9375] "°C" Vector__XXX

BO_ 651 TxPDO_MotorAActual2_11: 8 Vector__XXX
SG_ Motor_A_act_temp_11 : 0|16@1- (0.0625,0) [-2048|2047.9375] "°C" Vector__XXX
SG_ Motor_A_act_power_11 : 16|16@1- (0.016,0) [-524.288|524.272] "kW" Vector__XXX
SG_ Motor_A_act_voltage_11 : 32|16@1- (0.0625,0) [-2048|2047.9375] "V" Vector__XXX
SG_ Inverter_A_act_module_temp_11 : 48|16@1- (0.0625,0) [-2048|2047.9375] "°C" Vector__XXX

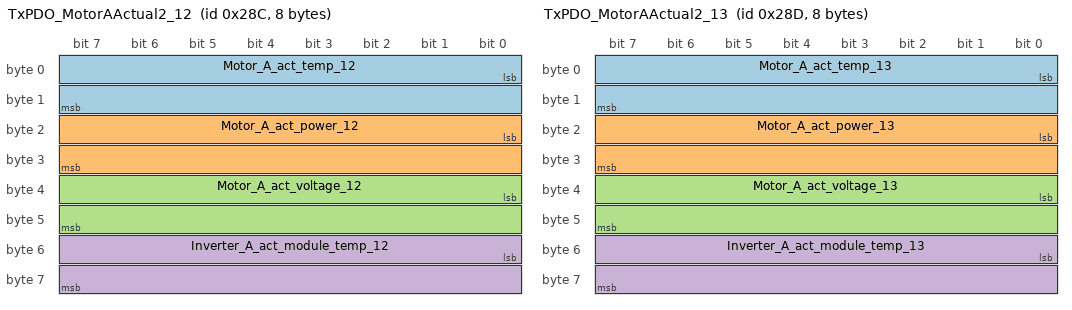
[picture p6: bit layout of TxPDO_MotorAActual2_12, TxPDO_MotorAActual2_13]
BO_ 652 TxPDO_MotorAActual2_12: 8 Vector__XXX
SG_ Motor_A_act_temp_12 : 0|16@1- (0.0625,0) [-2048|2047.9375] "°C" Vector__XXX
SG_ Motor_A_act_power_12 : 16|16@1- (0.016,0) [-524.288|524.272] "kW" Vector__XXX
SG_ Motor_A_act_voltage_12 : 32|16@1- (0.0625,0) [-2048|2047.9375] "V" Vector__XXX
SG_ Inverter_A_act_module_temp_12 : 48|16@1- (0.0625,0) [-2048|2047.9375] "°C" Vector__XXX

BO_ 653 TxPDO_MotorAActual2_13: 8 Vector__XXX
SG_ Motor_A_act_temp_13 : 0|16@1- (0.0625,0) [-2048|2047.9375] "°C" Vector__XXX
SG_ Motor_A_act_power_13 : 16|16@1- (0.016,0) [-524.288|524.272] "kW" Vector__XXX
SG_ Motor_A_act_voltage_13 : 32|16@1- (0.0625,0) [-2048|2047.9375] "V" Vector__XXX
SG_ Inverter_A_act_module_temp_13 : 48|16@1- (0.0625,0) [-2048|2047.9375] "°C" Vector__XXX

BO_ 718 TxPDO_InverterBStatus_14: 8 Vector__XXX
SG_ Inverter_B_Statusword_14 : 0|7@1+ (1,0) [0|127] "" Vector__XXX
SG_ EVENTBUFFER_NEW_EVENT : 16|1@1+ (1,0) [0|1] "" Vector__XXX
SG_ EVENTBUFFER_OVERFLOW : 17|1@1+ (1,0) [0|1] "" Vector__XXX
SG_ POWERMODULE_TRIPZONE_OVERCURRE : 18|1@1+ (1,0) [0|1] "" Vector__XXX
SG_ POWERMODULE_CURRENT_OFFSET_INI : 19|1@1+ (1,0) [0|1] "" Vector__XXX
SG_ POWERMODULE_TEMPSENSOR_ERROR : 20|1@1+ (1,0) [0|1] "" Vector__XXX
SG_ POWERMODULE_TEMPERATURE_WARNIN : 21|1@1+ (1,0) [0|1] "" Vector__XXX
SG_ POWERMODULE_OVERTEMPERATURE : 22|1@1+ (1,0) [0|1] "" Vector__XXX
SG_ POWERMODULE_IXT_FAULT : 23|1@1+ (1,0) [0|1] "" Vector__XXX
SG_ POWERMODULE_SW_OVERCURRENT : 24|1@1+ (1,0) [0|1] "" Vector__XXX
SG_ POWERMODULE_PATTERNDATA_INCONS : 25|1@1+ (1,0) [0|1] "" Vector__XXX
SG_ DCBUS_TRIPZONE_OVERVOLTAGE : 26|1@1+ (1,0) [0|1] "" Vector__XXX
SG_ DCBUS_SW_OVERVOLTAGE : 27|1@1+ (1,0) [0|1] "" Vector__XXX
SG_ DCBUS_SW_UNDERVOLTAGE : 28|1@1+ (1,0) [0|1] "" Vector__XXX
SG_ NEIGHBOUR_FAULT : 29|1@1+ (1,0) [0|1] "" Vector__XXX
SG_ MOTOR_TEMPSENSOR_ERROR : 30|1@1+ (1,0) [0|1] "" Vector__XXX
SG_ MOTOR_TEMPERATURE_WARNING : 31|1@1+ (1,0) [0|1] "" Vector__XXX
SG_ MOTOR_OVERTEMPERATURE : 32|1@1+ (1,0) [0|1] "" Vector__XXX
SG_ MOTOR_STATOR_FREQ_TO_HIGH : 33|1@1+ (1,0) [0|1] "" Vector__XXX
SG_ SUPPLYVOLTAGE_ERROR : 34|1@1+ (1,0) [0|1] "" Vector__XXX
SG_ RPDO_TIMEOUT : 35|1@1+ (1,0) [0|1] "" Vector__XXX
SG_ NMT_NOT_OPERATIONAL : 36|1@1+ (1,0) [0|1] "" Vector__XXX
SG_ TASKOVERRUN : 37|1@1+ (1,0) [0|1] "" Vector__XXX
SG_ NETSYNC_ERROR : 38|1@1+ (1,0) [0|1] "" Vector__XXX
SG_ POSDEVICE_SIGNAL_TO_LOW : 39|1@1+ (1,0) [0|1] "" Vector__XXX
SG_ POSDEVICE_SIGNAL_TO_HIGH : 40|1@1+ (1,0) [0|1] "" Vector__XXX
SG_ RESOLVER_CALIBRATION_FAILED : 41|1@1+ (1,0) [0|1] "" Vector__XXX
SG_ SYSTEM_FAULT : 42|1@1+ (1,0) [0|1] "" Vector__XXX
SG_ INTERLOCK_OPEN : 43|1@1+ (1,0) [0|1] "" Vector__XXX
SG_ APPC_HAS_GATE_DRIVER_DISABLED : 44|1@1+ (1,0) [0|1] "" Vector__XXX
SG_ MOTOR_STALL_ERROR : 45|1@1+ (1,0) [0|1] "" Vector__XXX
SG_ AMBIENT_TEMPERATURE_WARNING : 46|1@1+ (1,0) [0|1] "" Vector__XXX
SG_ AMBIENT_OVERTEMPERATURE : 47|1@1+ (1,0) [0|1] "" Vector__XXX
SG_ AMBIENT_TEMPSENSOR_ERROR : 48|1@1+ (1,0) [0|1] "" Vector__XXX
SG_ POWERMODULE_CLAMPING_TIMEOUT : 49|1@1+ (1,0) [0|1] "" Vector__XXX
SG_ DCBUS_RIPPLE_TO_HIGH : 50|1@1+ (1,0) [0|1] "" Vector__XXX
SG_ MOTOR_I2XT_WARNING : 51|1@1+ (1,0) [0|1] "" Vector__XXX
SG_ MOTOR_I2XT_ERROR : 52|1@1+ (1,0) [0|1] "" Vector__XXX
SG_ MOTOR_FIELDWEAKENING_ERROR : 53|1@1+ (1,0) [0|1] "" Vector__XXX
SG_ INVALID_PARAMETER_COMBINATION : 54|1@1+ (1,0) [0|1] "" Vector__XXX
SG_ PLUG_COVER_SENSOR_SIGNAL_LOW : 55|1@1+ (1,0) [0|1] "" Vector__XXX
SG_ MOTOR_CONNECTION_TEST_FAILED : 56|1@1+ (1,0) [0|1] "" Vector__XXX
SG_ POWERMODULE_IXT_WARNING : 57|1@1+ (1,0) [0|1] "" Vector__XXX
SG_ ISOLATION_FAULT : 58|1@1+ (1,0) [0|1] "" Vector__XXX

BO_ 705 TxPDO_InverterBStatus_1: 8 Vector__XXX
SG_ Inverter_B_Statusword_1 : 0|7@1+ (1,0) [0|127] "" Vector__XXX
SG_ EVENTBUFFER_NEW_EVENT : 16|1@1+ (1,0) [0|1] "" Vector__XXX
SG_ EVENTBUFFER_OVERFLOW : 17|1@1+ (1,0) [0|1] "" Vector__XXX
SG_ POWERMODULE_TRIPZONE_OVERCURRE : 18|1@1+ (1,0) [0|1] "" Vector__XXX
SG_ POWERMODULE_CURRENT_OFFSET_INI : 19|1@1+ (1,0) [0|1] "" Vector__XXX
SG_ POWERMODULE_TEMPSENSOR_ERROR : 20|1@1+ (1,0) [0|1] "" Vector__XXX
SG_ POWERMODULE_TEMPERATURE_WARNIN : 21|1@1+ (1,0) [0|1] "" Vector__XXX
SG_ POWERMODULE_OVERTEMPERATURE : 22|1@1+ (1,0) [0|1] "" Vector__XXX
SG_ POWERMODULE_IXT_FAULT : 23|1@1+ (1,0) [0|1] "" Vector__XXX
SG_ POWERMODULE_SW_OVERCURRENT : 24|1@1+ (1,0) [0|1] "" Vector__XXX
SG_ POWERMODULE_PATTERNDATA_INCONS : 25|1@1+ (1,0) [0|1] "" Vector__XXX
SG_ DCBUS_TRIPZONE_OVERVOLTAGE : 26|1@1+ (1,0) [0|1] "" Vector__XXX
SG_ DCBUS_SW_OVERVOLTAGE : 27|1@1+ (1,0) [0|1] "" Vector__XXX
SG_ DCBUS_SW_UNDERVOLTAGE : 28|1@1+ (1,0) [0|1] "" Vector__XXX
SG_ NEIGHBOUR_FAULT : 29|1@1+ (1,0) [0|1] "" Vector__XXX
SG_ MOTOR_TEMPSENSOR_ERROR : 30|1@1+ (1,0) [0|1] "" Vector__XXX
SG_ MOTOR_TEMPERATURE_WARNING : 31|1@1+ (1,0) [0|1] "" Vector__XXX
SG_ MOTOR_OVERTEMPERATURE : 32|1@1+ (1,0) [0|1] "" Vector__XXX
SG_ MOTOR_STATOR_FREQ_TO_HIGH : 33|1@1+ (1,0) [0|1] "" Vector__XXX
SG_ SUPPLYVOLTAGE_ERROR : 34|1@1+ (1,0) [0|1] "" Vector__XXX
SG_ RPDO_TIMEOUT : 35|1@1+ (1,0) [0|1] "" Vector__XXX
SG_ NMT_NOT_OPERATIONAL : 36|1@1+ (1,0) [0|1] "" Vector__XXX
SG_ TASKOVERRUN : 37|1@1+ (1,0) [0|1] "" Vector__XXX
SG_ NETSYNC_ERROR : 38|1@1+ (1,0) [0|1] "" Vector__XXX
SG_ POSDEVICE_SIGNAL_TO_LOW : 39|1@1+ (1,0) [0|1] "" Vector__XXX
SG_ POSDEVICE_SIGNAL_TO_HIGH : 40|1@1+ (1,0) [0|1] "" Vector__XXX
SG_ RESOLVER_CALIBRATION_FAILED : 41|1@1+ (1,0) [0|1] "" Vector__XXX
SG_ SYSTEM_FAULT : 42|1@1+ (1,0) [0|1] "" Vector__XXX
SG_ INTERLOCK_OPEN : 43|1@1+ (1,0) [0|1] "" Vector__XXX
SG_ APPC_HAS_GATE_DRIVER_DISABLED : 44|1@1+ (1,0) [0|1] "" Vector__XXX
SG_ MOTOR_STALL_ERROR : 45|1@1+ (1,0) [0|1] "" Vector__XXX
SG_ AMBIENT_TEMPERATURE_WARNING : 46|1@1+ (1,0) [0|1] "" Vector__XXX
SG_ AMBIENT_OVERTEMPERATURE : 47|1@1+ (1,0) [0|1] "" Vector__XXX
SG_ AMBIENT_TEMPSENSOR_ERROR : 48|1@1+ (1,0) [0|1] "" Vector__XXX
SG_ POWERMODULE_CLAMPING_TIMEOUT : 49|1@1+ (1,0) [0|1] "" Vector__XXX
SG_ DCBUS_RIPPLE_TO_HIGH : 50|1@1+ (1,0) [0|1] "" Vector__XXX
SG_ MOTOR_I2XT_WARNING : 51|1@1+ (1,0) [0|1] "" Vector__XXX
SG_ MOTOR_I2XT_ERROR : 52|1@1+ (1,0) [0|1] "" Vector__XXX
SG_ MOTOR_FIELDWEAKENING_ERROR : 53|1@1+ (1,0) [0|1] "" Vector__XXX
SG_ INVALID_PARAMETER_COMBINATION : 54|1@1+ (1,0) [0|1] "" Vector__XXX
SG_ PLUG_COVER_SENSOR_SIGNAL_LOW : 55|1@1+ (1,0) [0|1] "" Vector__XXX
SG_ MOTOR_CONNECTION_TEST_FAILED : 56|1@1+ (1,0) [0|1] "" Vector__XXX
SG_ POWERMODULE_IXT_WARNING : 57|1@1+ (1,0) [0|1] "" Vector__XXX
SG_ ISOLATION_FAULT : 58|1@1+ (1,0) [0|1] "" Vector__XXX

BO_ 706 TxPDO_InverterBStatus_2: 8 Vector__XXX
SG_ Inverter_B_Statusword_2 : 0|7@1+ (1,0) [0|127] "" Vector__XXX
SG_ EVENTBUFFER_NEW_EVENT : 16|1@1+ (1,0) [0|1] "" Vector__XXX
SG_ EVENTBUFFER_OVERFLOW : 17|1@1+ (1,0) [0|1] "" Vector__XXX
SG_ POWERMODULE_TRIPZONE_OVERCURRE : 18|1@1+ (1,0) [0|1] "" Vector__XXX
SG_ POWERMODULE_CURRENT_OFFSET_INI : 19|1@1+ (1,0) [0|1] "" Vector__XXX
SG_ POWERMODULE_TEMPSENSOR_ERROR : 20|1@1+ (1,0) [0|1] "" Vector__XXX
SG_ POWERMODULE_TEMPERATURE_WARNIN : 21|1@1+ (1,0) [0|1] "" Vector__XXX
SG_ POWERMODULE_OVERTEMPERATURE : 22|1@1+ (1,0) [0|1] "" Vector__XXX
SG_ POWERMODULE_IXT_FAULT : 23|1@1+ (1,0) [0|1] "" Vector__XXX
SG_ POWERMODULE_SW_OVERCURRENT : 24|1@1+ (1,0) [0|1] "" Vector__XXX
SG_ POWERMODULE_PATTERNDATA_INCONS : 25|1@1+ (1,0) [0|1] "" Vector__XXX
SG_ DCBUS_TRIPZONE_OVERVOLTAGE : 26|1@1+ (1,0) [0|1] "" Vector__XXX
SG_ DCBUS_SW_OVERVOLTAGE : 27|1@1+ (1,0) [0|1] "" Vector__XXX
SG_ DCBUS_SW_UNDERVOLTAGE : 28|1@1+ (1,0) [0|1] "" Vector__XXX
SG_ NEIGHBOUR_FAULT : 29|1@1+ (1,0) [0|1] "" Vector__XXX
SG_ MOTOR_TEMPSENSOR_ERROR : 30|1@1+ (1,0) [0|1] "" Vector__XXX
SG_ MOTOR_TEMPERATURE_WARNING : 31|1@1+ (1,0) [0|1] "" Vector__XXX
SG_ MOTOR_OVERTEMPERATURE : 32|1@1+ (1,0) [0|1] "" Vector__XXX
SG_ MOTOR_STATOR_FREQ_TO_HIGH : 33|1@1+ (1,0) [0|1] "" Vector__XXX
SG_ SUPPLYVOLTAGE_ERROR : 34|1@1+ (1,0) [0|1] "" Vector__XXX
SG_ RPDO_TIMEOUT : 35|1@1+ (1,0) [0|1] "" Vector__XXX
SG_ NMT_NOT_OPERATIONAL : 36|1@1+ (1,0) [0|1] "" Vector__XXX
SG_ TASKOVERRUN : 37|1@1+ (1,0) [0|1] "" Vector__XXX
SG_ NETSYNC_ERROR : 38|1@1+ (1,0) [0|1] "" Vector__XXX
SG_ POSDEVICE_SIGNAL_TO_LOW : 39|1@1+ (1,0) [0|1] "" Vector__XXX
SG_ POSDEVICE_SIGNAL_TO_HIGH : 40|1@1+ (1,0) [0|1] "" Vector__XXX
SG_ RESOLVER_CALIBRATION_FAILED : 41|1@1+ (1,0) [0|1] "" Vector__XXX
SG_ SYSTEM_FAULT : 42|1@1+ (1,0) [0|1] "" Vector__XXX
SG_ INTERLOCK_OPEN : 43|1@1+ (1,0) [0|1] "" Vector__XXX
SG_ APPC_HAS_GATE_DRIVER_DISABLED : 44|1@1+ (1,0) [0|1] "" Vector__XXX
SG_ MOTOR_STALL_ERROR : 45|1@1+ (1,0) [0|1] "" Vector__XXX
SG_ AMBIENT_TEMPERATURE_WARNING : 46|1@1+ (1,0) [0|1] "" Vector__XXX
SG_ AMBIENT_OVERTEMPERATURE : 47|1@1+ (1,0) [0|1] "" Vector__XXX
SG_ AMBIENT_TEMPSENSOR_ERROR : 48|1@1+ (1,0) [0|1] "" Vector__XXX
SG_ POWERMODULE_CLAMPING_TIMEOUT : 49|1@1+ (1,0) [0|1] "" Vector__XXX
SG_ DCBUS_RIPPLE_TO_HIGH : 50|1@1+ (1,0) [0|1] "" Vector__XXX
SG_ MOTOR_I2XT_WARNING : 51|1@1+ (1,0) [0|1] "" Vector__XXX
SG_ MOTOR_I2XT_ERROR : 52|1@1+ (1,0) [0|1] "" Vector__XXX
SG_ MOTOR_FIELDWEAKENING_ERROR : 53|1@1+ (1,0) [0|1] "" Vector__XXX
SG_ INVALID_PARAMETER_COMBINATION : 54|1@1+ (1,0) [0|1] "" Vector__XXX
SG_ PLUG_COVER_SENSOR_SIGNAL_LOW : 55|1@1+ (1,0) [0|1] "" Vector__XXX
SG_ MOTOR_CONNECTION_TEST_FAILED : 56|1@1+ (1,0) [0|1] "" Vector__XXX
SG_ POWERMODULE_IXT_WARNING : 57|1@1+ (1,0) [0|1] "" Vector__XXX
SG_ ISOLATION_FAULT : 58|1@1+ (1,0) [0|1] "" Vector__XXX

BO_ 707 TxPDO_InverterBStatus_3: 8 Vector__XXX
SG_ Inverter_B_Statusword_3 : 0|7@1+ (1,0) [0|127] "" Vector__XXX
SG_ EVENTBUFFER_NEW_EVENT : 16|1@1+ (1,0) [0|1] "" Vector__XXX
SG_ EVENTBUFFER_OVERFLOW : 17|1@1+ (1,0) [0|1] "" Vector__XXX
SG_ POWERMODULE_TRIPZONE_OVERCURRE : 18|1@1+ (1,0) [0|1] "" Vector__XXX
SG_ POWERMODULE_CURRENT_OFFSET_INI : 19|1@1+ (1,0) [0|1] "" Vector__XXX
SG_ POWERMODULE_TEMPSENSOR_ERROR : 20|1@1+ (1,0) [0|1] "" Vector__XXX
SG_ POWERMODULE_TEMPERATURE_WARNIN : 21|1@1+ (1,0) [0|1] "" Vector__XXX
SG_ POWERMODULE_OVERTEMPERATURE : 22|1@1+ (1,0) [0|1] "" Vector__XXX
SG_ POWERMODULE_IXT_FAULT : 23|1@1+ (1,0) [0|1] "" Vector__XXX
SG_ POWERMODULE_SW_OVERCURRENT : 24|1@1+ (1,0) [0|1] "" Vector__XXX
SG_ POWERMODULE_PATTERNDATA_INCONS : 25|1@1+ (1,0) [0|1] "" Vector__XXX
SG_ DCBUS_TRIPZONE_OVERVOLTAGE : 26|1@1+ (1,0) [0|1] "" Vector__XXX
SG_ DCBUS_SW_OVERVOLTAGE : 27|1@1+ (1,0) [0|1] "" Vector__XXX
SG_ DCBUS_SW_UNDERVOLTAGE : 28|1@1+ (1,0) [0|1] "" Vector__XXX
SG_ NEIGHBOUR_FAULT : 29|1@1+ (1,0) [0|1] "" Vector__XXX
SG_ MOTOR_TEMPSENSOR_ERROR : 30|1@1+ (1,0) [0|1] "" Vector__XXX
SG_ MOTOR_TEMPERATURE_WARNING : 31|1@1+ (1,0) [0|1] "" Vector__XXX
SG_ MOTOR_OVERTEMPERATURE : 32|1@1+ (1,0) [0|1] "" Vector__XXX
SG_ MOTOR_STATOR_FREQ_TO_HIGH : 33|1@1+ (1,0) [0|1] "" Vector__XXX
SG_ SUPPLYVOLTAGE_ERROR : 34|1@1+ (1,0) [0|1] "" Vector__XXX
SG_ RPDO_TIMEOUT : 35|1@1+ (1,0) [0|1] "" Vector__XXX
SG_ NMT_NOT_OPERATIONAL : 36|1@1+ (1,0) [0|1] "" Vector__XXX
SG_ TASKOVERRUN : 37|1@1+ (1,0) [0|1] "" Vector__XXX
SG_ NETSYNC_ERROR : 38|1@1+ (1,0) [0|1] "" Vector__XXX
SG_ POSDEVICE_SIGNAL_TO_LOW : 39|1@1+ (1,0) [0|1] "" Vector__XXX
SG_ POSDEVICE_SIGNAL_TO_HIGH : 40|1@1+ (1,0) [0|1] "" Vector__XXX
SG_ RESOLVER_CALIBRATION_FAILED : 41|1@1+ (1,0) [0|1] "" Vector__XXX
SG_ SYSTEM_FAULT : 42|1@1+ (1,0) [0|1] "" Vector__XXX
SG_ INTERLOCK_OPEN : 43|1@1+ (1,0) [0|1] "" Vector__XXX
SG_ APPC_HAS_GATE_DRIVER_DISABLED : 44|1@1+ (1,0) [0|1] "" Vector__XXX
SG_ MOTOR_STALL_ERROR : 45|1@1+ (1,0) [0|1] "" Vector__XXX
SG_ AMBIENT_TEMPERATURE_WARNING : 46|1@1+ (1,0) [0|1] "" Vector__XXX
SG_ AMBIENT_OVERTEMPERATURE : 47|1@1+ (1,0) [0|1] "" Vector__XXX
SG_ AMBIENT_TEMPSENSOR_ERROR : 48|1@1+ (1,0) [0|1] "" Vector__XXX
SG_ POWERMODULE_CLAMPING_TIMEOUT : 49|1@1+ (1,0) [0|1] "" Vector__XXX
SG_ DCBUS_RIPPLE_TO_HIGH : 50|1@1+ (1,0) [0|1] "" Vector__XXX
SG_ MOTOR_I2XT_WARNING : 51|1@1+ (1,0) [0|1] "" Vector__XXX
SG_ MOTOR_I2XT_ERROR : 52|1@1+ (1,0) [0|1] "" Vector__XXX
SG_ MOTOR_FIELDWEAKENING_ERROR : 53|1@1+ (1,0) [0|1] "" Vector__XXX
SG_ INVALID_PARAMETER_COMBINATION : 54|1@1+ (1,0) [0|1] "" Vector__XXX
SG_ PLUG_COVER_SENSOR_SIGNAL_LOW : 55|1@1+ (1,0) [0|1] "" Vector__XXX
SG_ MOTOR_CONNECTION_TEST_FAILED : 56|1@1+ (1,0) [0|1] "" Vector__XXX
SG_ POWERMODULE_IXT_WARNING : 57|1@1+ (1,0) [0|1] "" Vector__XXX
SG_ ISOLATION_FAULT : 58|1@1+ (1,0) [0|1] "" Vector__XXX

BO_ 708 TxPDO_InverterBStatus_4: 8 Vector__XXX
SG_ Inverter_B_Statusword_4 : 0|7@1+ (1,0) [0|127] "" Vector__XXX
SG_ EVENTBUFFER_NEW_EVENT : 16|1@1+ (1,0) [0|1] "" Vector__XXX
SG_ EVENTBUFFER_OVERFLOW : 17|1@1+ (1,0) [0|1] "" Vector__XXX
SG_ POWERMODULE_TRIPZONE_OVERCURRE : 18|1@1+ (1,0) [0|1] "" Vector__XXX
SG_ POWERMODULE_CURRENT_OFFSET_INI : 19|1@1+ (1,0) [0|1] "" Vector__XXX
SG_ POWERMODULE_TEMPSENSOR_ERROR : 20|1@1+ (1,0) [0|1] "" Vector__XXX
SG_ POWERMODULE_TEMPERATURE_WARNIN : 21|1@1+ (1,0) [0|1] "" Vector__XXX
SG_ POWERMODULE_OVERTEMPERATURE : 22|1@1+ (1,0) [0|1] "" Vector__XXX
SG_ POWERMODULE_IXT_FAULT : 23|1@1+ (1,0) [0|1] "" Vector__XXX
SG_ POWERMODULE_SW_OVERCURRENT : 24|1@1+ (1,0) [0|1] "" Vector__XXX
SG_ POWERMODULE_PATTERNDATA_INCONS : 25|1@1+ (1,0) [0|1] "" Vector__XXX
SG_ DCBUS_TRIPZONE_OVERVOLTAGE : 26|1@1+ (1,0) [0|1] "" Vector__XXX
SG_ DCBUS_SW_OVERVOLTAGE : 27|1@1+ (1,0) [0|1] "" Vector__XXX
SG_ DCBUS_SW_UNDERVOLTAGE : 28|1@1+ (1,0) [0|1] "" Vector__XXX
SG_ NEIGHBOUR_FAULT : 29|1@1+ (1,0) [0|1] "" Vector__XXX
SG_ MOTOR_TEMPSENSOR_ERROR : 30|1@1+ (1,0) [0|1] "" Vector__XXX
SG_ MOTOR_TEMPERATURE_WARNING : 31|1@1+ (1,0) [0|1] "" Vector__XXX
SG_ MOTOR_OVERTEMPERATURE : 32|1@1+ (1,0) [0|1] "" Vector__XXX
SG_ MOTOR_STATOR_FREQ_TO_HIGH : 33|1@1+ (1,0) [0|1] "" Vector__XXX
SG_ SUPPLYVOLTAGE_ERROR : 34|1@1+ (1,0) [0|1] "" Vector__XXX
SG_ RPDO_TIMEOUT : 35|1@1+ (1,0) [0|1] "" Vector__XXX
SG_ NMT_NOT_OPERATIONAL : 36|1@1+ (1,0) [0|1] "" Vector__XXX
SG_ TASKOVERRUN : 37|1@1+ (1,0) [0|1] "" Vector__XXX
SG_ NETSYNC_ERROR : 38|1@1+ (1,0) [0|1] "" Vector__XXX
SG_ POSDEVICE_SIGNAL_TO_LOW : 39|1@1+ (1,0) [0|1] "" Vector__XXX
SG_ POSDEVICE_SIGNAL_TO_HIGH : 40|1@1+ (1,0) [0|1] "" Vector__XXX
SG_ RESOLVER_CALIBRATION_FAILED : 41|1@1+ (1,0) [0|1] "" Vector__XXX
SG_ SYSTEM_FAULT : 42|1@1+ (1,0) [0|1] "" Vector__XXX
SG_ INTERLOCK_OPEN : 43|1@1+ (1,0) [0|1] "" Vector__XXX
SG_ APPC_HAS_GATE_DRIVER_DISABLED : 44|1@1+ (1,0) [0|1] "" Vector__XXX
SG_ MOTOR_STALL_ERROR : 45|1@1+ (1,0) [0|1] "" Vector__XXX
SG_ AMBIENT_TEMPERATURE_WARNING : 46|1@1+ (1,0) [0|1] "" Vector__XXX
SG_ AMBIENT_OVERTEMPERATURE : 47|1@1+ (1,0) [0|1] "" Vector__XXX
SG_ AMBIENT_TEMPSENSOR_ERROR : 48|1@1+ (1,0) [0|1] "" Vector__XXX
SG_ POWERMODULE_CLAMPING_TIMEOUT : 49|1@1+ (1,0) [0|1] "" Vector__XXX
SG_ DCBUS_RIPPLE_TO_HIGH : 50|1@1+ (1,0) [0|1] "" Vector__XXX
SG_ MOTOR_I2XT_WARNING : 51|1@1+ (1,0) [0|1] "" Vector__XXX
SG_ MOTOR_I2XT_ERROR : 52|1@1+ (1,0) [0|1] "" Vector__XXX
SG_ MOTOR_FIELDWEAKENING_ERROR : 53|1@1+ (1,0) [0|1] "" Vector__XXX
SG_ INVALID_PARAMETER_COMBINATION : 54|1@1+ (1,0) [0|1] "" Vector__XXX
SG_ PLUG_COVER_SENSOR_SIGNAL_LOW : 55|1@1+ (1,0) [0|1] "" Vector__XXX
SG_ MOTOR_CONNECTION_TEST_FAILED : 56|1@1+ (1,0) [0|1] "" Vector__XXX
SG_ POWERMODULE_IXT_WARNING : 57|1@1+ (1,0) [0|1] "" Vector__XXX
SG_ ISOLATION_FAULT : 58|1@1+ (1,0) [0|1] "" Vector__XXX

BO_ 709 TxPDO_InverterBStatus_5: 8 Vector__XXX
SG_ Inverter_B_Statusword_5 : 0|7@1+ (1,0) [0|127] "" Vector__XXX
SG_ EVENTBUFFER_NEW_EVENT : 16|1@1+ (1,0) [0|1] "" Vector__XXX
SG_ EVENTBUFFER_OVERFLOW : 17|1@1+ (1,0) [0|1] "" Vector__XXX
SG_ POWERMODULE_TRIPZONE_OVERCURRE : 18|1@1+ (1,0) [0|1] "" Vector__XXX
SG_ POWERMODULE_CURRENT_OFFSET_INI : 19|1@1+ (1,0) [0|1] "" Vector__XXX
SG_ POWERMODULE_TEMPSENSOR_ERROR : 20|1@1+ (1,0) [0|1] "" Vector__XXX
SG_ POWERMODULE_TEMPERATURE_WARNIN : 21|1@1+ (1,0) [0|1] "" Vector__XXX
SG_ POWERMODULE_OVERTEMPERATURE : 22|1@1+ (1,0) [0|1] "" Vector__XXX
SG_ POWERMODULE_IXT_FAULT : 23|1@1+ (1,0) [0|1] "" Vector__XXX
SG_ POWERMODULE_SW_OVERCURRENT : 24|1@1+ (1,0) [0|1] "" Vector__XXX
SG_ POWERMODULE_PATTERNDATA_INCONS : 25|1@1+ (1,0) [0|1] "" Vector__XXX
SG_ DCBUS_TRIPZONE_OVERVOLTAGE : 26|1@1+ (1,0) [0|1] "" Vector__XXX
SG_ DCBUS_SW_OVERVOLTAGE : 27|1@1+ (1,0) [0|1] "" Vector__XXX
SG_ DCBUS_SW_UNDERVOLTAGE : 28|1@1+ (1,0) [0|1] "" Vector__XXX
SG_ NEIGHBOUR_FAULT : 29|1@1+ (1,0) [0|1] "" Vector__XXX
SG_ MOTOR_TEMPSENSOR_ERROR : 30|1@1+ (1,0) [0|1] "" Vector__XXX
SG_ MOTOR_TEMPERATURE_WARNING : 31|1@1+ (1,0) [0|1] "" Vector__XXX
SG_ MOTOR_OVERTEMPERATURE : 32|1@1+ (1,0) [0|1] "" Vector__XXX
SG_ MOTOR_STATOR_FREQ_TO_HIGH : 33|1@1+ (1,0) [0|1] "" Vector__XXX
SG_ SUPPLYVOLTAGE_ERROR : 34|1@1+ (1,0) [0|1] "" Vector__XXX
SG_ RPDO_TIMEOUT : 35|1@1+ (1,0) [0|1] "" Vector__XXX
SG_ NMT_NOT_OPERATIONAL : 36|1@1+ (1,0) [0|1] "" Vector__XXX
SG_ TASKOVERRUN : 37|1@1+ (1,0) [0|1] "" Vector__XXX
SG_ NETSYNC_ERROR : 38|1@1+ (1,0) [0|1] "" Vector__XXX
SG_ POSDEVICE_SIGNAL_TO_LOW : 39|1@1+ (1,0) [0|1] "" Vector__XXX
SG_ POSDEVICE_SIGNAL_TO_HIGH : 40|1@1+ (1,0) [0|1] "" Vector__XXX
SG_ RESOLVER_CALIBRATION_FAILED : 41|1@1+ (1,0) [0|1] "" Vector__XXX
SG_ SYSTEM_FAULT : 42|1@1+ (1,0) [0|1] "" Vector__XXX
SG_ INTERLOCK_OPEN : 43|1@1+ (1,0) [0|1] "" Vector__XXX
SG_ APPC_HAS_GATE_DRIVER_DISABLED : 44|1@1+ (1,0) [0|1] "" Vector__XXX
SG_ MOTOR_STALL_ERROR : 45|1@1+ (1,0) [0|1] "" Vector__XXX
SG_ AMBIENT_TEMPERATURE_WARNING : 46|1@1+ (1,0) [0|1] "" Vector__XXX
SG_ AMBIENT_OVERTEMPERATURE : 47|1@1+ (1,0) [0|1] "" Vector__XXX
SG_ AMBIENT_TEMPSENSOR_ERROR : 48|1@1+ (1,0) [0|1] "" Vector__XXX
SG_ POWERMODULE_CLAMPING_TIMEOUT : 49|1@1+ (1,0) [0|1] "" Vector__XXX
SG_ DCBUS_RIPPLE_TO_HIGH : 50|1@1+ (1,0) [0|1] "" Vector__XXX
SG_ MOTOR_I2XT_WARNING : 51|1@1+ (1,0) [0|1] "" Vector__XXX
SG_ MOTOR_I2XT_ERROR : 52|1@1+ (1,0) [0|1] "" Vector__XXX
SG_ MOTOR_FIELDWEAKENING_ERROR : 53|1@1+ (1,0) [0|1] "" Vector__XXX
SG_ INVALID_PARAMETER_COMBINATION : 54|1@1+ (1,0) [0|1] "" Vector__XXX
SG_ PLUG_COVER_SENSOR_SIGNAL_LOW : 55|1@1+ (1,0) [0|1] "" Vector__XXX
SG_ MOTOR_CONNECTION_TEST_FAILED : 56|1@1+ (1,0) [0|1] "" Vector__XXX
SG_ POWERMODULE_IXT_WARNING : 57|1@1+ (1,0) [0|1] "" Vector__XXX
SG_ ISOLATION_FAULT : 58|1@1+ (1,0) [0|1] "" Vector__XXX

BO_ 710 TxPDO_InverterBStatus_6: 8 Vector__XXX
SG_ Inverter_B_Statusword_6 : 0|7@1+ (1,0) [0|127] "" Vector__XXX
SG_ EVENTBUFFER_NEW_EVENT : 16|1@1+ (1,0) [0|1] "" Vector__XXX
SG_ EVENTBUFFER_OVERFLOW : 17|1@1+ (1,0) [0|1] "" Vector__XXX
SG_ POWERMODULE_TRIPZONE_OVERCURRE : 18|1@1+ (1,0) [0|1] "" Vector__XXX
SG_ POWERMODULE_CURRENT_OFFSET_INI : 19|1@1+ (1,0) [0|1] "" Vector__XXX
SG_ POWERMODULE_TEMPSENSOR_ERROR : 20|1@1+ (1,0) [0|1] "" Vector__XXX
SG_ POWERMODULE_TEMPERATURE_WARNIN : 21|1@1+ (1,0) [0|1] "" Vector__XXX
SG_ POWERMODULE_OVERTEMPERATURE : 22|1@1+ (1,0) [0|1] "" Vector__XXX
SG_ POWERMODULE_IXT_FAULT : 23|1@1+ (1,0) [0|1] "" Vector__XXX
SG_ POWERMODULE_SW_OVERCURRENT : 24|1@1+ (1,0) [0|1] "" Vector__XXX
SG_ POWERMODULE_PATTERNDATA_INCONS : 25|1@1+ (1,0) [0|1] "" Vector__XXX
SG_ DCBUS_TRIPZONE_OVERVOLTAGE : 26|1@1+ (1,0) [0|1] "" Vector__XXX
SG_ DCBUS_SW_OVERVOLTAGE : 27|1@1+ (1,0) [0|1] "" Vector__XXX
SG_ DCBUS_SW_UNDERVOLTAGE : 28|1@1+ (1,0) [0|1] "" Vector__XXX
SG_ NEIGHBOUR_FAULT : 29|1@1+ (1,0) [0|1] "" Vector__XXX
SG_ MOTOR_TEMPSENSOR_ERROR : 30|1@1+ (1,0) [0|1] "" Vector__XXX
SG_ MOTOR_TEMPERATURE_WARNING : 31|1@1+ (1,0) [0|1] "" Vector__XXX
SG_ MOTOR_OVERTEMPERATURE : 32|1@1+ (1,0) [0|1] "" Vector__XXX
SG_ MOTOR_STATOR_FREQ_TO_HIGH : 33|1@1+ (1,0) [0|1] "" Vector__XXX
SG_ SUPPLYVOLTAGE_ERROR : 34|1@1+ (1,0) [0|1] "" Vector__XXX
SG_ RPDO_TIMEOUT : 35|1@1+ (1,0) [0|1] "" Vector__XXX
SG_ NMT_NOT_OPERATIONAL : 36|1@1+ (1,0) [0|1] "" Vector__XXX
SG_ TASKOVERRUN : 37|1@1+ (1,0) [0|1] "" Vector__XXX
SG_ NETSYNC_ERROR : 38|1@1+ (1,0) [0|1] "" Vector__XXX
SG_ POSDEVICE_SIGNAL_TO_LOW : 39|1@1+ (1,0) [0|1] "" Vector__XXX
SG_ POSDEVICE_SIGNAL_TO_HIGH : 40|1@1+ (1,0) [0|1] "" Vector__XXX
SG_ RESOLVER_CALIBRATION_FAILED : 41|1@1+ (1,0) [0|1] "" Vector__XXX
SG_ SYSTEM_FAULT : 42|1@1+ (1,0) [0|1] "" Vector__XXX
SG_ INTERLOCK_OPEN : 43|1@1+ (1,0) [0|1] "" Vector__XXX
SG_ APPC_HAS_GATE_DRIVER_DISABLED : 44|1@1+ (1,0) [0|1] "" Vector__XXX
SG_ MOTOR_STALL_ERROR : 45|1@1+ (1,0) [0|1] "" Vector__XXX
SG_ AMBIENT_TEMPERATURE_WARNING : 46|1@1+ (1,0) [0|1] "" Vector__XXX
SG_ AMBIENT_OVERTEMPERATURE : 47|1@1+ (1,0) [0|1] "" Vector__XXX
SG_ AMBIENT_TEMPSENSOR_ERROR : 48|1@1+ (1,0) [0|1] "" Vector__XXX
SG_ POWERMODULE_CLAMPING_TIMEOUT : 49|1@1+ (1,0) [0|1] "" Vector__XXX
SG_ DCBUS_RIPPLE_TO_HIGH : 50|1@1+ (1,0) [0|1] "" Vector__XXX
SG_ MOTOR_I2XT_WARNING : 51|1@1+ (1,0) [0|1] "" Vector__XXX
SG_ MOTOR_I2XT_ERROR : 52|1@1+ (1,0) [0|1] "" Vector__XXX
SG_ MOTOR_FIELDWEAKENING_ERROR : 53|1@1+ (1,0) [0|1] "" Vector__XXX
SG_ INVALID_PARAMETER_COMBINATION : 54|1@1+ (1,0) [0|1] "" Vector__XXX
SG_ PLUG_COVER_SENSOR_SIGNAL_LOW : 55|1@1+ (1,0) [0|1] "" Vector__XXX
SG_ MOTOR_CONNECTION_TEST_FAILED : 56|1@1+ (1,0) [0|1] "" Vector__XXX
SG_ POWERMODULE_IXT_WARNING : 57|1@1+ (1,0) [0|1] "" Vector__XXX
SG_ ISOLATION_FAULT : 58|1@1+ (1,0) [0|1] "" Vector__XXX

BO_ 711 TxPDO_InverterBStatus_7: 8 Vector__XXX
SG_ Inverter_B_Statusword_7 : 0|7@1+ (1,0) [0|127] "" Vector__XXX
SG_ EVENTBUFFER_NEW_EVENT : 16|1@1+ (1,0) [0|1] "" Vector__XXX
SG_ EVENTBUFFER_OVERFLOW : 17|1@1+ (1,0) [0|1] "" Vector__XXX
SG_ POWERMODULE_TRIPZONE_OVERCURRE : 18|1@1+ (1,0) [0|1] "" Vector__XXX
SG_ POWERMODULE_CURRENT_OFFSET_INI : 19|1@1+ (1,0) [0|1] "" Vector__XXX
SG_ POWERMODULE_TEMPSENSOR_ERROR : 20|1@1+ (1,0) [0|1] "" Vector__XXX
SG_ POWERMODULE_TEMPERATURE_WARNIN : 21|1@1+ (1,0) [0|1] "" Vector__XXX
SG_ POWERMODULE_OVERTEMPERATURE : 22|1@1+ (1,0) [0|1] "" Vector__XXX
SG_ POWERMODULE_IXT_FAULT : 23|1@1+ (1,0) [0|1] "" Vector__XXX
SG_ POWERMODULE_SW_OVERCURRENT : 24|1@1+ (1,0) [0|1] "" Vector__XXX
SG_ POWERMODULE_PATTERNDATA_INCONS : 25|1@1+ (1,0) [0|1] "" Vector__XXX
SG_ DCBUS_TRIPZONE_OVERVOLTAGE : 26|1@1+ (1,0) [0|1] "" Vector__XXX
SG_ DCBUS_SW_OVERVOLTAGE : 27|1@1+ (1,0) [0|1] "" Vector__XXX
SG_ DCBUS_SW_UNDERVOLTAGE : 28|1@1+ (1,0) [0|1] "" Vector__XXX
SG_ NEIGHBOUR_FAULT : 29|1@1+ (1,0) [0|1] "" Vector__XXX
SG_ MOTOR_TEMPSENSOR_ERROR : 30|1@1+ (1,0) [0|1] "" Vector__XXX
SG_ MOTOR_TEMPERATURE_WARNING : 31|1@1+ (1,0) [0|1] "" Vector__XXX
SG_ MOTOR_OVERTEMPERATURE : 32|1@1+ (1,0) [0|1] "" Vector__XXX
SG_ MOTOR_STATOR_FREQ_TO_HIGH : 33|1@1+ (1,0) [0|1] "" Vector__XXX
SG_ SUPPLYVOLTAGE_ERROR : 34|1@1+ (1,0) [0|1] "" Vector__XXX
SG_ RPDO_TIMEOUT : 35|1@1+ (1,0) [0|1] "" Vector__XXX
SG_ NMT_NOT_OPERATIONAL : 36|1@1+ (1,0) [0|1] "" Vector__XXX
SG_ TASKOVERRUN : 37|1@1+ (1,0) [0|1] "" Vector__XXX
SG_ NETSYNC_ERROR : 38|1@1+ (1,0) [0|1] "" Vector__XXX
SG_ POSDEVICE_SIGNAL_TO_LOW : 39|1@1+ (1,0) [0|1] "" Vector__XXX
SG_ POSDEVICE_SIGNAL_TO_HIGH : 40|1@1+ (1,0) [0|1] "" Vector__XXX
SG_ RESOLVER_CALIBRATION_FAILED : 41|1@1+ (1,0) [0|1] "" Vector__XXX
SG_ SYSTEM_FAULT : 42|1@1+ (1,0) [0|1] "" Vector__XXX
SG_ INTERLOCK_OPEN : 43|1@1+ (1,0) [0|1] "" Vector__XXX
SG_ APPC_HAS_GATE_DRIVER_DISABLED : 44|1@1+ (1,0) [0|1] "" Vector__XXX
SG_ MOTOR_STALL_ERROR : 45|1@1+ (1,0) [0|1] "" Vector__XXX
SG_ AMBIENT_TEMPERATURE_WARNING : 46|1@1+ (1,0) [0|1] "" Vector__XXX
SG_ AMBIENT_OVERTEMPERATURE : 47|1@1+ (1,0) [0|1] "" Vector__XXX
SG_ AMBIENT_TEMPSENSOR_ERROR : 48|1@1+ (1,0) [0|1] "" Vector__XXX
SG_ POWERMODULE_CLAMPING_TIMEOUT : 49|1@1+ (1,0) [0|1] "" Vector__XXX
SG_ DCBUS_RIPPLE_TO_HIGH : 50|1@1+ (1,0) [0|1] "" Vector__XXX
SG_ MOTOR_I2XT_WARNING : 51|1@1+ (1,0) [0|1] "" Vector__XXX
SG_ MOTOR_I2XT_ERROR : 52|1@1+ (1,0) [0|1] "" Vector__XXX
SG_ MOTOR_FIELDWEAKENING_ERROR : 53|1@1+ (1,0) [0|1] "" Vector__XXX
SG_ INVALID_PARAMETER_COMBINATION : 54|1@1+ (1,0) [0|1] "" Vector__XXX
SG_ PLUG_COVER_SENSOR_SIGNAL_LOW : 55|1@1+ (1,0) [0|1] "" Vector__XXX
SG_ MOTOR_CONNECTION_TEST_FAILED : 56|1@1+ (1,0) [0|1] "" Vector__XXX
SG_ POWERMODULE_IXT_WARNING : 57|1@1+ (1,0) [0|1] "" Vector__XXX
SG_ ISOLATION_FAULT : 58|1@1+ (1,0) [0|1] "" Vector__XXX

BO_ 712 TxPDO_InverterBStatus_8: 8 Vector__XXX
SG_ Inverter_B_Statusword_8 : 0|7@1+ (1,0) [0|127] "" Vector__XXX
SG_ EVENTBUFFER_NEW_EVENT : 16|1@1+ (1,0) [0|1] "" Vector__XXX
SG_ EVENTBUFFER_OVERFLOW : 17|1@1+ (1,0) [0|1] "" Vector__XXX
SG_ POWERMODULE_TRIPZONE_OVERCURRE : 18|1@1+ (1,0) [0|1] "" Vector__XXX
SG_ POWERMODULE_CURRENT_OFFSET_INI : 19|1@1+ (1,0) [0|1] "" Vector__XXX
SG_ POWERMODULE_TEMPSENSOR_ERROR : 20|1@1+ (1,0) [0|1] "" Vector__XXX
SG_ POWERMODULE_TEMPERATURE_WARNIN : 21|1@1+ (1,0) [0|1] "" Vector__XXX
SG_ POWERMODULE_OVERTEMPERATURE : 22|1@1+ (1,0) [0|1] "" Vector__XXX
SG_ POWERMODULE_IXT_FAULT : 23|1@1+ (1,0) [0|1] "" Vector__XXX
SG_ POWERMODULE_SW_OVERCURRENT : 24|1@1+ (1,0) [0|1] "" Vector__XXX
SG_ POWERMODULE_PATTERNDATA_INCONS : 25|1@1+ (1,0) [0|1] "" Vector__XXX
SG_ DCBUS_TRIPZONE_OVERVOLTAGE : 26|1@1+ (1,0) [0|1] "" Vector__XXX
SG_ DCBUS_SW_OVERVOLTAGE : 27|1@1+ (1,0) [0|1] "" Vector__XXX
SG_ DCBUS_SW_UNDERVOLTAGE : 28|1@1+ (1,0) [0|1] "" Vector__XXX
SG_ NEIGHBOUR_FAULT : 29|1@1+ (1,0) [0|1] "" Vector__XXX
SG_ MOTOR_TEMPSENSOR_ERROR : 30|1@1+ (1,0) [0|1] "" Vector__XXX
SG_ MOTOR_TEMPERATURE_WARNING : 31|1@1+ (1,0) [0|1] "" Vector__XXX
SG_ MOTOR_OVERTEMPERATURE : 32|1@1+ (1,0) [0|1] "" Vector__XXX
SG_ MOTOR_STATOR_FREQ_TO_HIGH : 33|1@1+ (1,0) [0|1] "" Vector__XXX
SG_ SUPPLYVOLTAGE_ERROR : 34|1@1+ (1,0) [0|1] "" Vector__XXX
SG_ RPDO_TIMEOUT : 35|1@1+ (1,0) [0|1] "" Vector__XXX
SG_ NMT_NOT_OPERATIONAL : 36|1@1+ (1,0) [0|1] "" Vector__XXX
SG_ TASKOVERRUN : 37|1@1+ (1,0) [0|1] "" Vector__XXX
SG_ NETSYNC_ERROR : 38|1@1+ (1,0) [0|1] "" Vector__XXX
SG_ POSDEVICE_SIGNAL_TO_LOW : 39|1@1+ (1,0) [0|1] "" Vector__XXX
SG_ POSDEVICE_SIGNAL_TO_HIGH : 40|1@1+ (1,0) [0|1] "" Vector__XXX
SG_ RESOLVER_CALIBRATION_FAILED : 41|1@1+ (1,0) [0|1] "" Vector__XXX
SG_ SYSTEM_FAULT : 42|1@1+ (1,0) [0|1] "" Vector__XXX
SG_ INTERLOCK_OPEN : 43|1@1+ (1,0) [0|1] "" Vector__XXX
SG_ APPC_HAS_GATE_DRIVER_DISABLED : 44|1@1+ (1,0) [0|1] "" Vector__XXX
SG_ MOTOR_STALL_ERROR : 45|1@1+ (1,0) [0|1] "" Vector__XXX
SG_ AMBIENT_TEMPERATURE_WARNING : 46|1@1+ (1,0) [0|1] "" Vector__XXX
SG_ AMBIENT_OVERTEMPERATURE : 47|1@1+ (1,0) [0|1] "" Vector__XXX
SG_ AMBIENT_TEMPSENSOR_ERROR : 48|1@1+ (1,0) [0|1] "" Vector__XXX
SG_ POWERMODULE_CLAMPING_TIMEOUT : 49|1@1+ (1,0) [0|1] "" Vector__XXX
SG_ DCBUS_RIPPLE_TO_HIGH : 50|1@1+ (1,0) [0|1] "" Vector__XXX
SG_ MOTOR_I2XT_WARNING : 51|1@1+ (1,0) [0|1] "" Vector__XXX
SG_ MOTOR_I2XT_ERROR : 52|1@1+ (1,0) [0|1] "" Vector__XXX
SG_ MOTOR_FIELDWEAKENING_ERROR : 53|1@1+ (1,0) [0|1] "" Vector__XXX
SG_ INVALID_PARAMETER_COMBINATION : 54|1@1+ (1,0) [0|1] "" Vector__XXX
SG_ PLUG_COVER_SENSOR_SIGNAL_LOW : 55|1@1+ (1,0) [0|1] "" Vector__XXX
SG_ MOTOR_CONNECTION_TEST_FAILED : 56|1@1+ (1,0) [0|1] "" Vector__XXX
SG_ POWERMODULE_IXT_WARNING : 57|1@1+ (1,0) [0|1] "" Vector__XXX
SG_ ISOLATION_FAULT : 58|1@1+ (1,0) [0|1] "" Vector__XXX

BO_ 713 TxPDO_InverterBStatus_9: 8 Vector__XXX
SG_ Inverter_B_Statusword_9 : 0|7@1+ (1,0) [0|127] "" Vector__XXX
SG_ EVENTBUFFER_NEW_EVENT : 16|1@1+ (1,0) [0|1] "" Vector__XXX
SG_ EVENTBUFFER_OVERFLOW : 17|1@1+ (1,0) [0|1] "" Vector__XXX
SG_ POWERMODULE_TRIPZONE_OVERCURRE : 18|1@1+ (1,0) [0|1] "" Vector__XXX
SG_ POWERMODULE_CURRENT_OFFSET_INI : 19|1@1+ (1,0) [0|1] "" Vector__XXX
SG_ POWERMODULE_TEMPSENSOR_ERROR : 20|1@1+ (1,0) [0|1] "" Vector__XXX
SG_ POWERMODULE_TEMPERATURE_WARNIN : 21|1@1+ (1,0) [0|1] "" Vector__XXX
SG_ POWERMODULE_OVERTEMPERATURE : 22|1@1+ (1,0) [0|1] "" Vector__XXX
SG_ POWERMODULE_IXT_FAULT : 23|1@1+ (1,0) [0|1] "" Vector__XXX
SG_ POWERMODULE_SW_OVERCURRENT : 24|1@1+ (1,0) [0|1] "" Vector__XXX
SG_ POWERMODULE_PATTERNDATA_INCONS : 25|1@1+ (1,0) [0|1] "" Vector__XXX
SG_ DCBUS_TRIPZONE_OVERVOLTAGE : 26|1@1+ (1,0) [0|1] "" Vector__XXX
SG_ DCBUS_SW_OVERVOLTAGE : 27|1@1+ (1,0) [0|1] "" Vector__XXX
SG_ DCBUS_SW_UNDERVOLTAGE : 28|1@1+ (1,0) [0|1] "" Vector__XXX
SG_ NEIGHBOUR_FAULT : 29|1@1+ (1,0) [0|1] "" Vector__XXX
SG_ MOTOR_TEMPSENSOR_ERROR : 30|1@1+ (1,0) [0|1] "" Vector__XXX
SG_ MOTOR_TEMPERATURE_WARNING : 31|1@1+ (1,0) [0|1] "" Vector__XXX
SG_ MOTOR_OVERTEMPERATURE : 32|1@1+ (1,0) [0|1] "" Vector__XXX
SG_ MOTOR_STATOR_FREQ_TO_HIGH : 33|1@1+ (1,0) [0|1] "" Vector__XXX
SG_ SUPPLYVOLTAGE_ERROR : 34|1@1+ (1,0) [0|1] "" Vector__XXX
SG_ RPDO_TIMEOUT : 35|1@1+ (1,0) [0|1] "" Vector__XXX
SG_ NMT_NOT_OPERATIONAL : 36|1@1+ (1,0) [0|1] "" Vector__XXX
SG_ TASKOVERRUN : 37|1@1+ (1,0) [0|1] "" Vector__XXX
SG_ NETSYNC_ERROR : 38|1@1+ (1,0) [0|1] "" Vector__XXX
SG_ POSDEVICE_SIGNAL_TO_LOW : 39|1@1+ (1,0) [0|1] "" Vector__XXX
SG_ POSDEVICE_SIGNAL_TO_HIGH : 40|1@1+ (1,0) [0|1] "" Vector__XXX
SG_ RESOLVER_CALIBRATION_FAILED : 41|1@1+ (1,0) [0|1] "" Vector__XXX
SG_ SYSTEM_FAULT : 42|1@1+ (1,0) [0|1] "" Vector__XXX
SG_ INTERLOCK_OPEN : 43|1@1+ (1,0) [0|1] "" Vector__XXX
SG_ APPC_HAS_GATE_DRIVER_DISABLED : 44|1@1+ (1,0) [0|1] "" Vector__XXX
SG_ MOTOR_STALL_ERROR : 45|1@1+ (1,0) [0|1] "" Vector__XXX
SG_ AMBIENT_TEMPERATURE_WARNING : 46|1@1+ (1,0) [0|1] "" Vector__XXX
SG_ AMBIENT_OVERTEMPERATURE : 47|1@1+ (1,0) [0|1] "" Vector__XXX
SG_ AMBIENT_TEMPSENSOR_ERROR : 48|1@1+ (1,0) [0|1] "" Vector__XXX
SG_ POWERMODULE_CLAMPING_TIMEOUT : 49|1@1+ (1,0) [0|1] "" Vector__XXX
SG_ DCBUS_RIPPLE_TO_HIGH : 50|1@1+ (1,0) [0|1] "" Vector__XXX
SG_ MOTOR_I2XT_WARNING : 51|1@1+ (1,0) [0|1] "" Vector__XXX
SG_ MOTOR_I2XT_ERROR : 52|1@1+ (1,0) [0|1] "" Vector__XXX
SG_ MOTOR_FIELDWEAKENING_ERROR : 53|1@1+ (1,0) [0|1] "" Vector__XXX
SG_ INVALID_PARAMETER_COMBINATION : 54|1@1+ (1,0) [0|1] "" Vector__XXX
SG_ PLUG_COVER_SENSOR_SIGNAL_LOW : 55|1@1+ (1,0) [0|1] "" Vector__XXX
SG_ MOTOR_CONNECTION_TEST_FAILED : 56|1@1+ (1,0) [0|1] "" Vector__XXX
SG_ POWERMODULE_IXT_WARNING : 57|1@1+ (1,0) [0|1] "" Vector__XXX
SG_ ISOLATION_FAULT : 58|1@1+ (1,0) [0|1] "" Vector__XXX

BO_ 714 TxPDO_InverterBStatus_10: 8 Vector__XXX
SG_ Inverter_B_Statusword_10 : 0|7@1+ (1,0) [0|127] "" Vector__XXX
SG_ EVENTBUFFER_NEW_EVENT : 16|1@1+ (1,0) [0|1] "" Vector__XXX
SG_ EVENTBUFFER_OVERFLOW : 17|1@1+ (1,0) [0|1] "" Vector__XXX
SG_ POWERMODULE_TRIPZONE_OVERCURRE : 18|1@1+ (1,0) [0|1] "" Vector__XXX
SG_ POWERMODULE_CURRENT_OFFSET_INI : 19|1@1+ (1,0) [0|1] "" Vector__XXX
SG_ POWERMODULE_TEMPSENSOR_ERROR : 20|1@1+ (1,0) [0|1] "" Vector__XXX
SG_ POWERMODULE_TEMPERATURE_WARNIN : 21|1@1+ (1,0) [0|1] "" Vector__XXX
SG_ POWERMODULE_OVERTEMPERATURE : 22|1@1+ (1,0) [0|1] "" Vector__XXX
SG_ POWERMODULE_IXT_FAULT : 23|1@1+ (1,0) [0|1] "" Vector__XXX
SG_ POWERMODULE_SW_OVERCURRENT : 24|1@1+ (1,0) [0|1] "" Vector__XXX
SG_ POWERMODULE_PATTERNDATA_INCONS : 25|1@1+ (1,0) [0|1] "" Vector__XXX
SG_ DCBUS_TRIPZONE_OVERVOLTAGE : 26|1@1+ (1,0) [0|1] "" Vector__XXX
SG_ DCBUS_SW_OVERVOLTAGE : 27|1@1+ (1,0) [0|1] "" Vector__XXX
SG_ DCBUS_SW_UNDERVOLTAGE : 28|1@1+ (1,0) [0|1] "" Vector__XXX
SG_ NEIGHBOUR_FAULT : 29|1@1+ (1,0) [0|1] "" Vector__XXX
SG_ MOTOR_TEMPSENSOR_ERROR : 30|1@1+ (1,0) [0|1] "" Vector__XXX
SG_ MOTOR_TEMPERATURE_WARNING : 31|1@1+ (1,0) [0|1] "" Vector__XXX
SG_ MOTOR_OVERTEMPERATURE : 32|1@1+ (1,0) [0|1] "" Vector__XXX
SG_ MOTOR_STATOR_FREQ_TO_HIGH : 33|1@1+ (1,0) [0|1] "" Vector__XXX
SG_ SUPPLYVOLTAGE_ERROR : 34|1@1+ (1,0) [0|1] "" Vector__XXX
SG_ RPDO_TIMEOUT : 35|1@1+ (1,0) [0|1] "" Vector__XXX
SG_ NMT_NOT_OPERATIONAL : 36|1@1+ (1,0) [0|1] "" Vector__XXX
SG_ TASKOVERRUN : 37|1@1+ (1,0) [0|1] "" Vector__XXX
SG_ NETSYNC_ERROR : 38|1@1+ (1,0) [0|1] "" Vector__XXX
SG_ POSDEVICE_SIGNAL_TO_LOW : 39|1@1+ (1,0) [0|1] "" Vector__XXX
SG_ POSDEVICE_SIGNAL_TO_HIGH : 40|1@1+ (1,0) [0|1] "" Vector__XXX
SG_ RESOLVER_CALIBRATION_FAILED : 41|1@1+ (1,0) [0|1] "" Vector__XXX
SG_ SYSTEM_FAULT : 42|1@1+ (1,0) [0|1] "" Vector__XXX
SG_ INTERLOCK_OPEN : 43|1@1+ (1,0) [0|1] "" Vector__XXX
SG_ APPC_HAS_GATE_DRIVER_DISABLED : 44|1@1+ (1,0) [0|1] "" Vector__XXX
SG_ MOTOR_STALL_ERROR : 45|1@1+ (1,0) [0|1] "" Vector__XXX
SG_ AMBIENT_TEMPERATURE_WARNING : 46|1@1+ (1,0) [0|1] "" Vector__XXX
SG_ AMBIENT_OVERTEMPERATURE : 47|1@1+ (1,0) [0|1] "" Vector__XXX
SG_ AMBIENT_TEMPSENSOR_ERROR : 48|1@1+ (1,0) [0|1] "" Vector__XXX
SG_ POWERMODULE_CLAMPING_TIMEOUT : 49|1@1+ (1,0) [0|1] "" Vector__XXX
SG_ DCBUS_RIPPLE_TO_HIGH : 50|1@1+ (1,0) [0|1] "" Vector__XXX
SG_ MOTOR_I2XT_WARNING : 51|1@1+ (1,0) [0|1] "" Vector__XXX
SG_ MOTOR_I2XT_ERROR : 52|1@1+ (1,0) [0|1] "" Vector__XXX
SG_ MOTOR_FIELDWEAKENING_ERROR : 53|1@1+ (1,0) [0|1] "" Vector__XXX
SG_ INVALID_PARAMETER_COMBINATION : 54|1@1+ (1,0) [0|1] "" Vector__XXX
SG_ PLUG_COVER_SENSOR_SIGNAL_LOW : 55|1@1+ (1,0) [0|1] "" Vector__XXX
SG_ MOTOR_CONNECTION_TEST_FAILED : 56|1@1+ (1,0) [0|1] "" Vector__XXX
SG_ POWERMODULE_IXT_WARNING : 57|1@1+ (1,0) [0|1] "" Vector__XXX
SG_ ISOLATION_FAULT : 58|1@1+ (1,0) [0|1] "" Vector__XXX

BO_ 715 TxPDO_InverterBStatus_11: 8 Vector__XXX
SG_ Inverter_B_Statusword_11 : 0|7@1+ (1,0) [0|127] "" Vector__XXX
SG_ EVENTBUFFER_NEW_EVENT : 16|1@1+ (1,0) [0|1] "" Vector__XXX
SG_ EVENTBUFFER_OVERFLOW : 17|1@1+ (1,0) [0|1] "" Vector__XXX
SG_ POWERMODULE_TRIPZONE_OVERCURRE : 18|1@1+ (1,0) [0|1] "" Vector__XXX
SG_ POWERMODULE_CURRENT_OFFSET_INI : 19|1@1+ (1,0) [0|1] "" Vector__XXX
SG_ POWERMODULE_TEMPSENSOR_ERROR : 20|1@1+ (1,0) [0|1] "" Vector__XXX
SG_ POWERMODULE_TEMPERATURE_WARNIN : 21|1@1+ (1,0) [0|1] "" Vector__XXX
SG_ POWERMODULE_OVERTEMPERATURE : 22|1@1+ (1,0) [0|1] "" Vector__XXX
SG_ POWERMODULE_IXT_FAULT : 23|1@1+ (1,0) [0|1] "" Vector__XXX
SG_ POWERMODULE_SW_OVERCURRENT : 24|1@1+ (1,0) [0|1] "" Vector__XXX
SG_ POWERMODULE_PATTERNDATA_INCONS : 25|1@1+ (1,0) [0|1] "" Vector__XXX
SG_ DCBUS_TRIPZONE_OVERVOLTAGE : 26|1@1+ (1,0) [0|1] "" Vector__XXX
SG_ DCBUS_SW_OVERVOLTAGE : 27|1@1+ (1,0) [0|1] "" Vector__XXX
SG_ DCBUS_SW_UNDERVOLTAGE : 28|1@1+ (1,0) [0|1] "" Vector__XXX
SG_ NEIGHBOUR_FAULT : 29|1@1+ (1,0) [0|1] "" Vector__XXX
SG_ MOTOR_TEMPSENSOR_ERROR : 30|1@1+ (1,0) [0|1] "" Vector__XXX
SG_ MOTOR_TEMPERATURE_WARNING : 31|1@1+ (1,0) [0|1] "" Vector__XXX
SG_ MOTOR_OVERTEMPERATURE : 32|1@1+ (1,0) [0|1] "" Vector__XXX
SG_ MOTOR_STATOR_FREQ_TO_HIGH : 33|1@1+ (1,0) [0|1] "" Vector__XXX
SG_ SUPPLYVOLTAGE_ERROR : 34|1@1+ (1,0) [0|1] "" Vector__XXX
SG_ RPDO_TIMEOUT : 35|1@1+ (1,0) [0|1] "" Vector__XXX
SG_ NMT_NOT_OPERATIONAL : 36|1@1+ (1,0) [0|1] "" Vector__XXX
SG_ TASKOVERRUN : 37|1@1+ (1,0) [0|1] "" Vector__XXX
SG_ NETSYNC_ERROR : 38|1@1+ (1,0) [0|1] "" Vector__XXX
SG_ POSDEVICE_SIGNAL_TO_LOW : 39|1@1+ (1,0) [0|1] "" Vector__XXX
SG_ POSDEVICE_SIGNAL_TO_HIGH : 40|1@1+ (1,0) [0|1] "" Vector__XXX
SG_ RESOLVER_CALIBRATION_FAILED : 41|1@1+ (1,0) [0|1] "" Vector__XXX
SG_ SYSTEM_FAULT : 42|1@1+ (1,0) [0|1] "" Vector__XXX
SG_ INTERLOCK_OPEN : 43|1@1+ (1,0) [0|1] "" Vector__XXX
SG_ APPC_HAS_GATE_DRIVER_DISABLED : 44|1@1+ (1,0) [0|1] "" Vector__XXX
SG_ MOTOR_STALL_ERROR : 45|1@1+ (1,0) [0|1] "" Vector__XXX
SG_ AMBIENT_TEMPERATURE_WARNING : 46|1@1+ (1,0) [0|1] "" Vector__XXX
SG_ AMBIENT_OVERTEMPERATURE : 47|1@1+ (1,0) [0|1] "" Vector__XXX
SG_ AMBIENT_TEMPSENSOR_ERROR : 48|1@1+ (1,0) [0|1] "" Vector__XXX
SG_ POWERMODULE_CLAMPING_TIMEOUT : 49|1@1+ (1,0) [0|1] "" Vector__XXX
SG_ DCBUS_RIPPLE_TO_HIGH : 50|1@1+ (1,0) [0|1] "" Vector__XXX
SG_ MOTOR_I2XT_WARNING : 51|1@1+ (1,0) [0|1] "" Vector__XXX
SG_ MOTOR_I2XT_ERROR : 52|1@1+ (1,0) [0|1] "" Vector__XXX
SG_ MOTOR_FIELDWEAKENING_ERROR : 53|1@1+ (1,0) [0|1] "" Vector__XXX
SG_ INVALID_PARAMETER_COMBINATION : 54|1@1+ (1,0) [0|1] "" Vector__XXX
SG_ PLUG_COVER_SENSOR_SIGNAL_LOW : 55|1@1+ (1,0) [0|1] "" Vector__XXX
SG_ MOTOR_CONNECTION_TEST_FAILED : 56|1@1+ (1,0) [0|1] "" Vector__XXX
SG_ POWERMODULE_IXT_WARNING : 57|1@1+ (1,0) [0|1] "" Vector__XXX
SG_ ISOLATION_FAULT : 58|1@1+ (1,0) [0|1] "" Vector__XXX

BO_ 716 TxPDO_InverterBStatus_12: 8 Vector__XXX
SG_ Inverter_B_Statusword_12 : 0|7@1+ (1,0) [0|127] "" Vector__XXX
SG_ EVENTBUFFER_NEW_EVENT : 16|1@1+ (1,0) [0|1] "" Vector__XXX
SG_ EVENTBUFFER_OVERFLOW : 17|1@1+ (1,0) [0|1] "" Vector__XXX
SG_ POWERMODULE_TRIPZONE_OVERCURRE : 18|1@1+ (1,0) [0|1] "" Vector__XXX
SG_ POWERMODULE_CURRENT_OFFSET_INI : 19|1@1+ (1,0) [0|1] "" Vector__XXX
SG_ POWERMODULE_TEMPSENSOR_ERROR : 20|1@1+ (1,0) [0|1] "" Vector__XXX
SG_ POWERMODULE_TEMPERATURE_WARNIN : 21|1@1+ (1,0) [0|1] "" Vector__XXX
SG_ POWERMODULE_OVERTEMPERATURE : 22|1@1+ (1,0) [0|1] "" Vector__XXX
SG_ POWERMODULE_IXT_FAULT : 23|1@1+ (1,0) [0|1] "" Vector__XXX
SG_ POWERMODULE_SW_OVERCURRENT : 24|1@1+ (1,0) [0|1] "" Vector__XXX
SG_ POWERMODULE_PATTERNDATA_INCONS : 25|1@1+ (1,0) [0|1] "" Vector__XXX
SG_ DCBUS_TRIPZONE_OVERVOLTAGE : 26|1@1+ (1,0) [0|1] "" Vector__XXX
SG_ DCBUS_SW_OVERVOLTAGE : 27|1@1+ (1,0) [0|1] "" Vector__XXX
SG_ DCBUS_SW_UNDERVOLTAGE : 28|1@1+ (1,0) [0|1] "" Vector__XXX
SG_ NEIGHBOUR_FAULT : 29|1@1+ (1,0) [0|1] "" Vector__XXX
SG_ MOTOR_TEMPSENSOR_ERROR : 30|1@1+ (1,0) [0|1] "" Vector__XXX
SG_ MOTOR_TEMPERATURE_WARNING : 31|1@1+ (1,0) [0|1] "" Vector__XXX
SG_ MOTOR_OVERTEMPERATURE : 32|1@1+ (1,0) [0|1] "" Vector__XXX
SG_ MOTOR_STATOR_FREQ_TO_HIGH : 33|1@1+ (1,0) [0|1] "" Vector__XXX
SG_ SUPPLYVOLTAGE_ERROR : 34|1@1+ (1,0) [0|1] "" Vector__XXX
SG_ RPDO_TIMEOUT : 35|1@1+ (1,0) [0|1] "" Vector__XXX
SG_ NMT_NOT_OPERATIONAL : 36|1@1+ (1,0) [0|1] "" Vector__XXX
SG_ TASKOVERRUN : 37|1@1+ (1,0) [0|1] "" Vector__XXX
SG_ NETSYNC_ERROR : 38|1@1+ (1,0) [0|1] "" Vector__XXX
SG_ POSDEVICE_SIGNAL_TO_LOW : 39|1@1+ (1,0) [0|1] "" Vector__XXX
SG_ POSDEVICE_SIGNAL_TO_HIGH : 40|1@1+ (1,0) [0|1] "" Vector__XXX
SG_ RESOLVER_CALIBRATION_FAILED : 41|1@1+ (1,0) [0|1] "" Vector__XXX
SG_ SYSTEM_FAULT : 42|1@1+ (1,0) [0|1] "" Vector__XXX
SG_ INTERLOCK_OPEN : 43|1@1+ (1,0) [0|1] "" Vector__XXX
SG_ APPC_HAS_GATE_DRIVER_DISABLED : 44|1@1+ (1,0) [0|1] "" Vector__XXX
SG_ MOTOR_STALL_ERROR : 45|1@1+ (1,0) [0|1] "" Vector__XXX
SG_ AMBIENT_TEMPERATURE_WARNING : 46|1@1+ (1,0) [0|1] "" Vector__XXX
SG_ AMBIENT_OVERTEMPERATURE : 47|1@1+ (1,0) [0|1] "" Vector__XXX
SG_ AMBIENT_TEMPSENSOR_ERROR : 48|1@1+ (1,0) [0|1] "" Vector__XXX
SG_ POWERMODULE_CLAMPING_TIMEOUT : 49|1@1+ (1,0) [0|1] "" Vector__XXX
SG_ DCBUS_RIPPLE_TO_HIGH : 50|1@1+ (1,0) [0|1] "" Vector__XXX
SG_ MOTOR_I2XT_WARNING : 51|1@1+ (1,0) [0|1] "" Vector__XXX
SG_ MOTOR_I2XT_ERROR : 52|1@1+ (1,0) [0|1] "" Vector__XXX
SG_ MOTOR_FIELDWEAKENING_ERROR : 53|1@1+ (1,0) [0|1] "" Vector__XXX
SG_ INVALID_PARAMETER_COMBINATION : 54|1@1+ (1,0) [0|1] "" Vector__XXX
SG_ PLUG_COVER_SENSOR_SIGNAL_LOW : 55|1@1+ (1,0) [0|1] "" Vector__XXX
SG_ MOTOR_CONNECTION_TEST_FAILED : 56|1@1+ (1,0) [0|1] "" Vector__XXX
SG_ POWERMODULE_IXT_WARNING : 57|1@1+ (1,0) [0|1] "" Vector__XXX
SG_ ISOLATION_FAULT : 58|1@1+ (1,0) [0|1] "" Vector__XXX

BO_ 717 TxPDO_InverterBStatus_13: 8 Vector__XXX
SG_ Inverter_B_Statusword_13 : 0|7@1+ (1,0) [0|127] "" Vector__XXX
SG_ EVENTBUFFER_NEW_EVENT : 16|1@1+ (1,0) [0|1] "" Vector__XXX
SG_ EVENTBUFFER_OVERFLOW : 17|1@1+ (1,0) [0|1] "" Vector__XXX
SG_ POWERMODULE_TRIPZONE_OVERCURRE : 18|1@1+ (1,0) [0|1] "" Vector__XXX
SG_ POWERMODULE_CURRENT_OFFSET_INI : 19|1@1+ (1,0) [0|1] "" Vector__XXX
SG_ POWERMODULE_TEMPSENSOR_ERROR : 20|1@1+ (1,0) [0|1] "" Vector__XXX
SG_ POWERMODULE_TEMPERATURE_WARNIN : 21|1@1+ (1,0) [0|1] "" Vector__XXX
SG_ POWERMODULE_OVERTEMPERATURE : 22|1@1+ (1,0) [0|1] "" Vector__XXX
SG_ POWERMODULE_IXT_FAULT : 23|1@1+ (1,0) [0|1] "" Vector__XXX
SG_ POWERMODULE_SW_OVERCURRENT : 24|1@1+ (1,0) [0|1] "" Vector__XXX
SG_ POWERMODULE_PATTERNDATA_INCONS : 25|1@1+ (1,0) [0|1] "" Vector__XXX
SG_ DCBUS_TRIPZONE_OVERVOLTAGE : 26|1@1+ (1,0) [0|1] "" Vector__XXX
SG_ DCBUS_SW_OVERVOLTAGE : 27|1@1+ (1,0) [0|1] "" Vector__XXX
SG_ DCBUS_SW_UNDERVOLTAGE : 28|1@1+ (1,0) [0|1] "" Vector__XXX
SG_ NEIGHBOUR_FAULT : 29|1@1+ (1,0) [0|1] "" Vector__XXX
SG_ MOTOR_TEMPSENSOR_ERROR : 30|1@1+ (1,0) [0|1] "" Vector__XXX
SG_ MOTOR_TEMPERATURE_WARNING : 31|1@1+ (1,0) [0|1] "" Vector__XXX
SG_ MOTOR_OVERTEMPERATURE : 32|1@1+ (1,0) [0|1] "" Vector__XXX
SG_ MOTOR_STATOR_FREQ_TO_HIGH : 33|1@1+ (1,0) [0|1] "" Vector__XXX
SG_ SUPPLYVOLTAGE_ERROR : 34|1@1+ (1,0) [0|1] "" Vector__XXX
SG_ RPDO_TIMEOUT : 35|1@1+ (1,0) [0|1] "" Vector__XXX
SG_ NMT_NOT_OPERATIONAL : 36|1@1+ (1,0) [0|1] "" Vector__XXX
SG_ TASKOVERRUN : 37|1@1+ (1,0) [0|1] "" Vector__XXX
SG_ NETSYNC_ERROR : 38|1@1+ (1,0) [0|1] "" Vector__XXX
SG_ POSDEVICE_SIGNAL_TO_LOW : 39|1@1+ (1,0) [0|1] "" Vector__XXX
SG_ POSDEVICE_SIGNAL_TO_HIGH : 40|1@1+ (1,0) [0|1] "" Vector__XXX
SG_ RESOLVER_CALIBRATION_FAILED : 41|1@1+ (1,0) [0|1] "" Vector__XXX
SG_ SYSTEM_FAULT : 42|1@1+ (1,0) [0|1] "" Vector__XXX
SG_ INTERLOCK_OPEN : 43|1@1+ (1,0) [0|1] "" Vector__XXX
SG_ APPC_HAS_GATE_DRIVER_DISABLED : 44|1@1+ (1,0) [0|1] "" Vector__XXX
SG_ MOTOR_STALL_ERROR : 45|1@1+ (1,0) [0|1] "" Vector__XXX
SG_ AMBIENT_TEMPERATURE_WARNING : 46|1@1+ (1,0) [0|1] "" Vector__XXX
SG_ AMBIENT_OVERTEMPERATURE : 47|1@1+ (1,0) [0|1] "" Vector__XXX
SG_ AMBIENT_TEMPSENSOR_ERROR : 48|1@1+ (1,0) [0|1] "" Vector__XXX
SG_ POWERMODULE_CLAMPING_TIMEOUT : 49|1@1+ (1,0) [0|1] "" Vector__XXX
SG_ DCBUS_RIPPLE_TO_HIGH : 50|1@1+ (1,0) [0|1] "" Vector__XXX
SG_ MOTOR_I2XT_WARNING : 51|1@1+ (1,0) [0|1] "" Vector__XXX
SG_ MOTOR_I2XT_ERROR : 52|1@1+ (1,0) [0|1] "" Vector__XXX
SG_ MOTOR_FIELDWEAKENING_ERROR : 53|1@1+ (1,0) [0|1] "" Vector__XXX
SG_ INVALID_PARAMETER_COMBINATION : 54|1@1+ (1,0) [0|1] "" Vector__XXX
SG_ PLUG_COVER_SENSOR_SIGNAL_LOW : 55|1@1+ (1,0) [0|1] "" Vector__XXX
SG_ MOTOR_CONNECTION_TEST_FAILED : 56|1@1+ (1,0) [0|1] "" Vector__XXX
SG_ POWERMODULE_IXT_WARNING : 57|1@1+ (1,0) [0|1] "" Vector__XXX
SG_ ISOLATION_FAULT : 58|1@1+ (1,0) [0|1] "" Vector__XXX

BO_ 846 TxPDO_MotorBActual1_14: 8 Vector__XXX
SG_ Motor_B_act_velocity_14 : 0|32@1- (6.103515625E-005,0) [-131072|131071.999938965] "rpm" Vector__XXX
SG_ Motor_B_act_torque_14 : 32|16@1- (0.1,0) [-3276.8|3276.7] "%" Vector__XXX
SG_ Motor_B_act_current_14 : 48|16@1- (0.015625,0) [-512|511.984375] "A" Vector__XXX

BO_ 833 TxPDO_MotorBActual1_1: 8 Vector__XXX
SG_ Motor_B_act_velocity_1 : 0|32@1- (6.103515625E-005,0) [-131072|131071.999938965] "rpm" Vector__XXX
SG_ Motor_B_act_torque_1 : 32|16@1- (0.1,0) [-3276.8|3276.7] "%" Vector__XXX
SG_ Motor_B_act_current_1 : 48|16@1- (0.015625,0) [-512|511.984375] "A" Vector__XXX

BO_ 834 TxPDO_MotorBActual1_2: 8 Vector__XXX
SG_ Motor_B_act_velocity_2 : 0|32@1- (6.103515625E-005,0) [-131072|131071.999938965] "rpm" Vector__XXX
SG_ Motor_B_act_torque_2 : 32|16@1- (0.1,0) [-3276.8|3276.7] "%" Vector__XXX
SG_ Motor_B_act_current_2 : 48|16@1- (0.015625,0) [-512|511.984375] "A" Vector__XXX

BO_ 835 TxPDO_MotorBActual1_3: 8 Vector__XXX
SG_ Motor_B_act_velocity_3 : 0|32@1- (6.103515625E-005,0) [-131072|131071.999938965] "rpm" Vector__XXX
SG_ Motor_B_act_torque_3 : 32|16@1- (0.1,0) [-3276.8|3276.7] "%" Vector__XXX
SG_ Motor_B_act_current_3 : 48|16@1- (0.015625,0) [-512|511.984375] "A" Vector__XXX

BO_ 836 TxPDO_MotorBActual1_4: 8 Vector__XXX
SG_ Motor_B_act_velocity_4 : 0|32@1- (6.103515625E-005,0) [-131072|131071.999938965] "rpm" Vector__XXX
SG_ Motor_B_act_torque_4 : 32|16@1- (0.1,0) [-3276.8|3276.7] "%" Vector__XXX
SG_ Motor_B_act_current_4 : 48|16@1- (0.015625,0) [-512|511.984375] "A" Vector__XXX

BO_ 837 TxPDO_MotorBActual1_5: 8 Vector__XXX
SG_ Motor_B_act_velocity_5 : 0|32@1- (6.103515625E-005,0) [-131072|131071.999938965] "rpm" Vector__XXX
SG_ Motor_B_act_torque_5 : 32|16@1- (0.1,0) [-3276.8|3276.7] "%" Vector__XXX
SG_ Motor_B_act_current_5 : 48|16@1- (0.015625,0) [-512|511.984375] "A" Vector__XXX

BO_ 838 TxPDO_MotorBActual1_6: 8 Vector__XXX
SG_ Motor_B_act_velocity_6 : 0|32@1- (6.103515625E-005,0) [-131072|131071.999938965] "rpm" Vector__XXX
SG_ Motor_B_act_torque_6 : 32|16@1- (0.1,0) [-3276.8|3276.7] "%" Vector__XXX
SG_ Motor_B_act_current_6 : 48|16@1- (0.015625,0) [-512|511.984375] "A" Vector__XXX

BO_ 839 TxPDO_MotorBActual1_7: 8 Vector__XXX
SG_ Motor_B_act_velocity_7 : 0|32@1- (6.103515625E-005,0) [-131072|131071.999938965] "rpm" Vector__XXX
SG_ Motor_B_act_torque_7 : 32|16@1- (0.1,0) [-3276.8|3276.7] "%" Vector__XXX
SG_ Motor_B_act_current_7 : 48|16@1- (0.015625,0) [-512|511.984375] "A" Vector__XXX

BO_ 840 TxPDO_MotorBActual1_8: 8 Vector__XXX
SG_ Motor_B_act_velocity_8 : 0|32@1- (6.103515625E-005,0) [-131072|131071.999938965] "rpm" Vector__XXX
SG_ Motor_B_act_torque_8 : 32|16@1- (0.1,0) [-3276.8|3276.7] "%" Vector__XXX
SG_ Motor_B_act_current_8 : 48|16@1- (0.015625,0) [-512|511.984375] "A" Vector__XXX

BO_ 841 TxPDO_MotorBActual1_9: 8 Vector__XXX
SG_ Motor_B_act_velocity_9 : 0|32@1- (6.103515625E-005,0) [-131072|131071.999938965] "rpm" Vector__XXX
SG_ Motor_B_act_torque_9 : 32|16@1- (0.1,0) [-3276.8|3276.7] "%" Vector__XXX
SG_ Motor_B_act_current_9 : 48|16@1- (0.015625,0) [-512|511.984375] "A" Vector__XXX

BO_ 842 TxPDO_MotorBActual1_10: 8 Vector__XXX
SG_ Motor_B_act_velocity_10 : 0|32@1- (6.103515625E-005,0) [-131072|131071.999938965] "rpm" Vector__XXX
SG_ Motor_B_act_torque_10 : 32|16@1- (0.1,0) [-3276.8|3276.7] "%" Vector__XXX
SG_ Motor_B_act_current_10 : 48|16@1- (0.015625,0) [-512|511.984375] "A" Vector__XXX

BO_ 843 TxPDO_MotorBActual1_11: 8 Vector__XXX
SG_ Motor_B_act_velocity_11 : 0|32@1- (6.103515625E-005,0) [-131072|131071.999938965] "rpm" Vector__XXX
SG_ Motor_B_act_torque_11 : 32|16@1- (0.1,0) [-3276.8|3276.7] "%" Vector__XXX
SG_ Motor_B_act_current_11 : 48|16@1- (0.015625,0) [-512|511.984375] "A" Vector__XXX

BO_ 844 TxPDO_MotorBActual1_12: 8 Vector__XXX
SG_ Motor_B_act_velocity_12 : 0|32@1- (6.103515625E-005,0) [-131072|131071.999938965] "rpm" Vector__XXX
SG_ Motor_B_act_torque_12 : 32|16@1- (0.1,0) [-3276.8|3276.7] "%" Vector__XXX
SG_ Motor_B_act_current_12 : 48|16@1- (0.015625,0) [-512|511.984375] "A" Vector__XXX

BO_ 845 TxPDO_MotorBActual1_13: 8 Vector__XXX
SG_ Motor_B_act_velocity_13 : 0|32@1- (6.103515625E-005,0) [-131072|131071.999938965] "rpm" Vector__XXX
SG_ Motor_B_act_torque_13 : 32|16@1- (0.1,0) [-3276.8|3276.7] "%" Vector__XXX
SG_ Motor_B_act_current_13 : 48|16@1- (0.015625,0) [-512|511.984375] "A" Vector__XXX

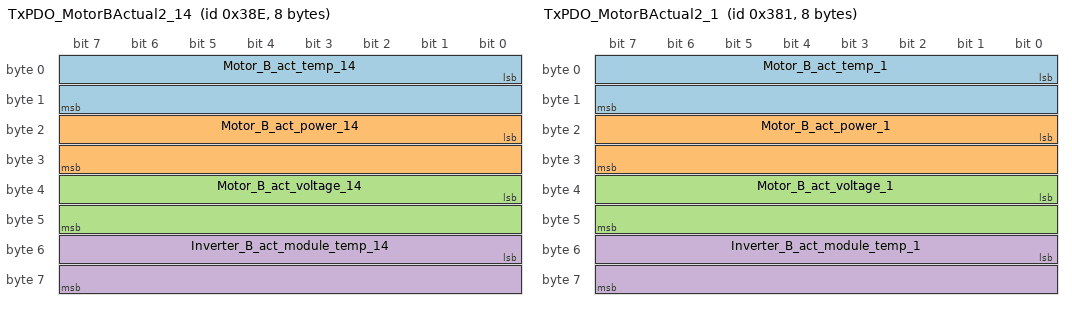
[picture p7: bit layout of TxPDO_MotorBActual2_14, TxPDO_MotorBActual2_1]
BO_ 910 TxPDO_MotorBActual2_14: 8 Vector__XXX
SG_ Motor_B_act_temp_14 : 0|16@1- (0.0625,0) [-2048|2047.9375] "°C" Vector__XXX
SG_ Motor_B_act_power_14 : 16|16@1- (0.016,0) [-524.288|524.272] "kW" Vector__XXX
SG_ Motor_B_act_voltage_14 : 32|16@1- (0.0625,0) [-2048|2047.9375] "V" Vector__XXX
SG_ Inverter_B_act_module_temp_14 : 48|16@1- (0.0625,0) [-2048|2047.9375] "°C" Vector__XXX

BO_ 897 TxPDO_MotorBActual2_1: 8 Vector__XXX
SG_ Motor_B_act_temp_1 : 0|16@1- (0.0625,0) [-2048|2047.9375] "°C" Vector__XXX
SG_ Motor_B_act_power_1 : 16|16@1- (0.016,0) [-524.288|524.272] "kW" Vector__XXX
SG_ Motor_B_act_voltage_1 : 32|16@1- (0.0625,0) [-2048|2047.9375] "V" Vector__XXX
SG_ Inverter_B_act_module_temp_1 : 48|16@1- (0.0625,0) [-2048|2047.9375] "°C" Vector__XXX

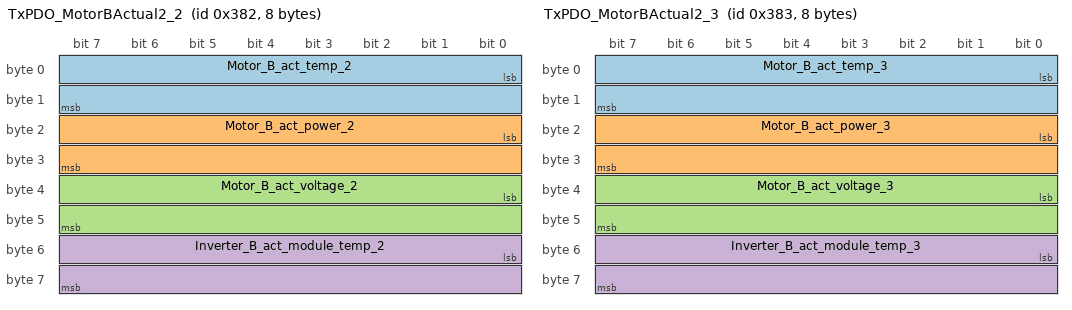
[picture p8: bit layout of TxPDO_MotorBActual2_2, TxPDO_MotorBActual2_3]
BO_ 898 TxPDO_MotorBActual2_2: 8 Vector__XXX
SG_ Motor_B_act_temp_2 : 0|16@1- (0.0625,0) [-2048|2047.9375] "°C" Vector__XXX
SG_ Motor_B_act_power_2 : 16|16@1- (0.016,0) [-524.288|524.272] "kW" Vector__XXX
SG_ Motor_B_act_voltage_2 : 32|16@1- (0.0625,0) [-2048|2047.9375] "V" Vector__XXX
SG_ Inverter_B_act_module_temp_2 : 48|16@1- (0.0625,0) [-2048|2047.9375] "°C" Vector__XXX

BO_ 899 TxPDO_MotorBActual2_3: 8 Vector__XXX
SG_ Motor_B_act_temp_3 : 0|16@1- (0.0625,0) [-2048|2047.9375] "°C" Vector__XXX
SG_ Motor_B_act_power_3 : 16|16@1- (0.016,0) [-524.288|524.272] "kW" Vector__XXX
SG_ Motor_B_act_voltage_3 : 32|16@1- (0.0625,0) [-2048|2047.9375] "V" Vector__XXX
SG_ Inverter_B_act_module_temp_3 : 48|16@1- (0.0625,0) [-2048|2047.9375] "°C" Vector__XXX

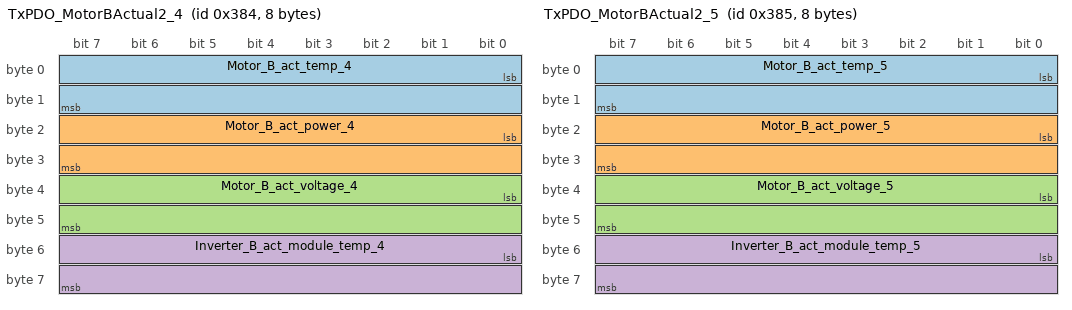
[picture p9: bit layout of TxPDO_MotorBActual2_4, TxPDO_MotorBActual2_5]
BO_ 900 TxPDO_MotorBActual2_4: 8 Vector__XXX
SG_ Motor_B_act_temp_4 : 0|16@1- (0.0625,0) [-2048|2047.9375] "°C" Vector__XXX
SG_ Motor_B_act_power_4 : 16|16@1- (0.016,0) [-524.288|524.272] "kW" Vector__XXX
SG_ Motor_B_act_voltage_4 : 32|16@1- (0.0625,0) [-2048|2047.9375] "V" Vector__XXX
SG_ Inverter_B_act_module_temp_4 : 48|16@1- (0.0625,0) [-2048|2047.9375] "°C" Vector__XXX

BO_ 901 TxPDO_MotorBActual2_5: 8 Vector__XXX
SG_ Motor_B_act_temp_5 : 0|16@1- (0.0625,0) [-2048|2047.9375] "°C" Vector__XXX
SG_ Motor_B_act_power_5 : 16|16@1- (0.016,0) [-524.288|524.272] "kW" Vector__XXX
SG_ Motor_B_act_voltage_5 : 32|16@1- (0.0625,0) [-2048|2047.9375] "V" Vector__XXX
SG_ Inverter_B_act_module_temp_5 : 48|16@1- (0.0625,0) [-2048|2047.9375] "°C" Vector__XXX

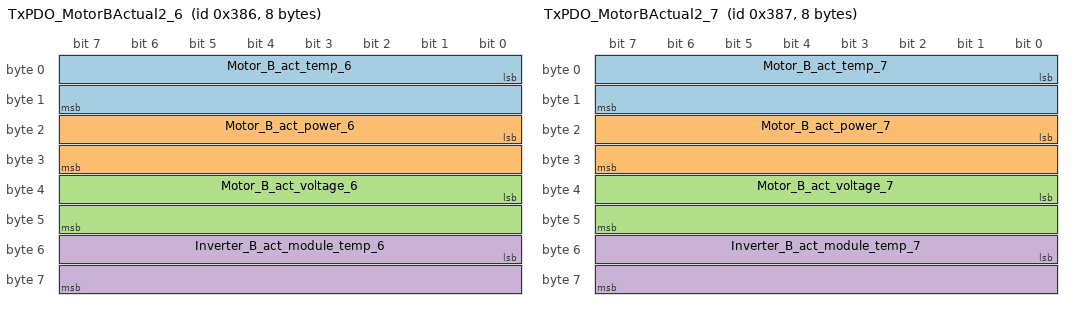
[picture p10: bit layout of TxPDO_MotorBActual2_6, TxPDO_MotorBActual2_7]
BO_ 902 TxPDO_MotorBActual2_6: 8 Vector__XXX
SG_ Motor_B_act_temp_6 : 0|16@1- (0.0625,0) [-2048|2047.9375] "°C" Vector__XXX
SG_ Motor_B_act_power_6 : 16|16@1- (0.016,0) [-524.288|524.272] "kW" Vector__XXX
SG_ Motor_B_act_voltage_6 : 32|16@1- (0.0625,0) [-2048|2047.9375] "V" Vector__XXX
SG_ Inverter_B_act_module_temp_6 : 48|16@1- (0.0625,0) [-2048|2047.9375] "°C" Vector__XXX

BO_ 903 TxPDO_MotorBActual2_7: 8 Vector__XXX
SG_ Motor_B_act_temp_7 : 0|16@1- (0.0625,0) [-2048|2047.9375] "°C" Vector__XXX
SG_ Motor_B_act_power_7 : 16|16@1- (0.016,0) [-524.288|524.272] "kW" Vector__XXX
SG_ Motor_B_act_voltage_7 : 32|16@1- (0.0625,0) [-2048|2047.9375] "V" Vector__XXX
SG_ Inverter_B_act_module_temp_7 : 48|16@1- (0.0625,0) [-2048|2047.9375] "°C" Vector__XXX

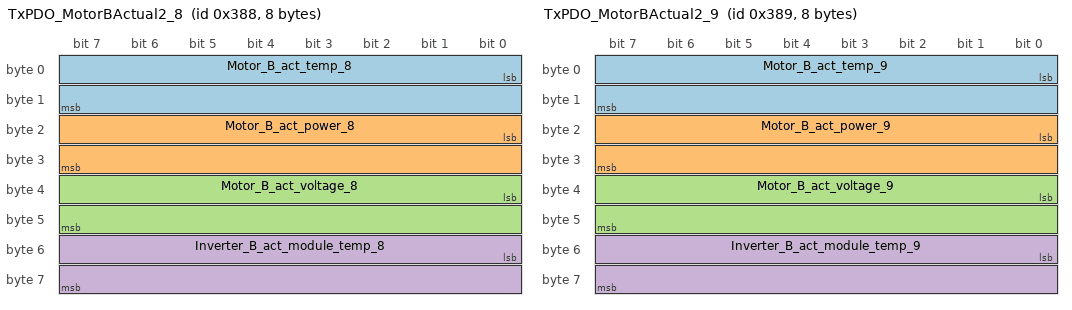
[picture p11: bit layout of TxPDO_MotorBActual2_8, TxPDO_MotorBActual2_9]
BO_ 904 TxPDO_MotorBActual2_8: 8 Vector__XXX
SG_ Motor_B_act_temp_8 : 0|16@1- (0.0625,0) [-2048|2047.9375] "°C" Vector__XXX
SG_ Motor_B_act_power_8 : 16|16@1- (0.016,0) [-524.288|524.272] "kW" Vector__XXX
SG_ Motor_B_act_voltage_8 : 32|16@1- (0.0625,0) [-2048|2047.9375] "V" Vector__XXX
SG_ Inverter_B_act_module_temp_8 : 48|16@1- (0.0625,0) [-2048|2047.9375] "°C" Vector__XXX

BO_ 905 TxPDO_MotorBActual2_9: 8 Vector__XXX
SG_ Motor_B_act_temp_9 : 0|16@1- (0.0625,0) [-2048|2047.9375] "°C" Vector__XXX
SG_ Motor_B_act_power_9 : 16|16@1- (0.016,0) [-524.288|524.272] "kW" Vector__XXX
SG_ Motor_B_act_voltage_9 : 32|16@1- (0.0625,0) [-2048|2047.9375] "V" Vector__XXX
SG_ Inverter_B_act_module_temp_9 : 48|16@1- (0.0625,0) [-2048|2047.9375] "°C" Vector__XXX

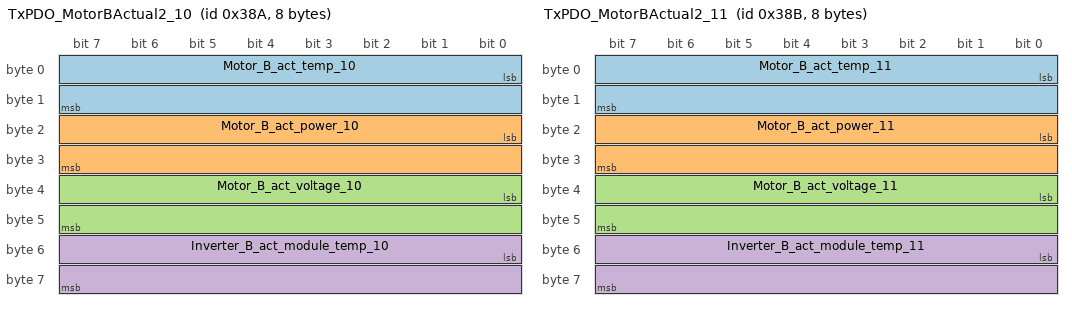
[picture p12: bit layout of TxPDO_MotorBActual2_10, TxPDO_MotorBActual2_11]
BO_ 906 TxPDO_MotorBActual2_10: 8 Vector__XXX
SG_ Motor_B_act_temp_10 : 0|16@1- (0.0625,0) [-2048|2047.9375] "°C" Vector__XXX
SG_ Motor_B_act_power_10 : 16|16@1- (0.016,0) [-524.288|524.272] "kW" Vector__XXX
SG_ Motor_B_act_voltage_10 : 32|16@1- (0.0625,0) [-2048|2047.9375] "V" Vector__XXX
SG_ Inverter_B_act_module_temp_10 : 48|16@1- (0.0625,0) [-2048|2047.9375] "°C" Vector__XXX

BO_ 907 TxPDO_MotorBActual2_11: 8 Vector__XXX
SG_ Motor_B_act_temp_11 : 0|16@1- (0.0625,0) [-2048|2047.9375] "°C" Vector__XXX
SG_ Motor_B_act_power_11 : 16|16@1- (0.016,0) [-524.288|524.272] "kW" Vector__XXX
SG_ Motor_B_act_voltage_11 : 32|16@1- (0.0625,0) [-2048|2047.9375] "V" Vector__XXX
SG_ Inverter_B_act_module_temp_11 : 48|16@1- (0.0625,0) [-2048|2047.9375] "°C" Vector__XXX

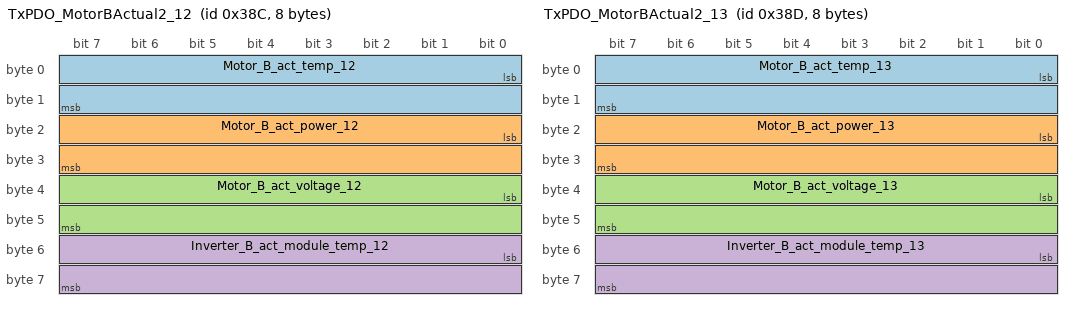
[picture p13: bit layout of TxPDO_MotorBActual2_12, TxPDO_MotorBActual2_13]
BO_ 908 TxPDO_MotorBActual2_12: 8 Vector__XXX
SG_ Motor_B_act_temp_12 : 0|16@1- (0.0625,0) [-2048|2047.9375] "°C" Vector__XXX
SG_ Motor_B_act_power_12 : 16|16@1- (0.016,0) [-524.288|524.272] "kW" Vector__XXX
SG_ Motor_B_act_voltage_12 : 32|16@1- (0.0625,0) [-2048|2047.9375] "V" Vector__XXX
SG_ Inverter_B_act_module_temp_12 : 48|16@1- (0.0625,0) [-2048|2047.9375] "°C" Vector__XXX

BO_ 909 TxPDO_MotorBActual2_13: 8 Vector__XXX
SG_ Motor_B_act_temp_13 : 0|16@1- (0.0625,0) [-2048|2047.9375] "°C" Vector__XXX
SG_ Motor_B_act_power_13 : 16|16@1- (0.016,0) [-524.288|524.272] "kW" Vector__XXX
SG_ Motor_B_act_voltage_13 : 32|16@1- (0.0625,0) [-2048|2047.9375] "V" Vector__XXX
SG_ Inverter_B_act_module_temp_13 : 48|16@1- (0.0625,0) [-2048|2047.9375] "°C" Vector__XXX

BO_ 0 NMT: 2 Vector__XXX
SG_ commmand_specifier : 0|8@1+ (1,0) [0|255] "" Vector__XXX
SG_ NodeID : 8|8@1+ (1,0) [0|255] "" Vector__XXX

BO_ 526 RxPDO_InverterASetpoint1_14: 8 Vector__XXX
SG_ Inverter_A_Controlword_14 : 0|16@1+ (1,0) [0|65535] "" Vector__XXX
SG_ Motor_A_target_velocity_14 : 16|32@1- (6.103515625E-005,0) [-131072|131071.999938965] "rpm" Vector__XXX
SG_ Motor_A_target_torque_14 : 48|16@1- (0.1,0) [-3276.8|3276.7] "%" Vector__XXX

BO_ 513 RxPDO_InverterASetpoint1_1: 8 Vector__XXX
SG_ Inverter_A_Controlword_1 : 0|16@1+ (1,0) [0|65535] "" Vector__XXX
SG_ Motor_A_target_velocity_1 : 16|32@1- (6.103515625E-005,0) [-131072|131071.999938965] "rpm" Vector__XXX
SG_ Motor_A_target_torque_1 : 48|16@1- (0.1,0) [-3276.8|3276.7] "%" Vector__XXX

BO_ 514 RxPDO_InverterASetpoint1_2: 8 Vector__XXX
SG_ Inverter_A_Controlword_2 : 0|16@1+ (1,0) [0|65535] "" Vector__XXX
SG_ Motor_A_target_velocity_2 : 16|32@1- (6.103515625E-005,0) [-131072|131071.999938965] "rpm" Vector__XXX
SG_ Motor_A_target_torque_2 : 48|16@1- (0.1,0) [-3276.8|3276.7] "%" Vector__XXX

BO_ 515 RxPDO_InverterASetpoint1_3: 8 Vector__XXX
SG_ Inverter_A_Controlword_3 : 0|16@1+ (1,0) [0|65535] "" Vector__XXX
SG_ Motor_A_target_velocity_3 : 16|32@1- (6.103515625E-005,0) [-131072|131071.999938965] "rpm" Vector__XXX
SG_ Motor_A_target_torque_3 : 48|16@1- (0.1,0) [-3276.8|3276.7] "%" Vector__XXX

BO_ 516 RxPDO_InverterASetpoint1_4: 8 Vector__XXX
SG_ Inverter_A_Controlword_4 : 0|16@1+ (1,0) [0|65535] "" Vector__XXX
SG_ Motor_A_target_velocity_4 : 16|32@1- (6.103515625E-005,0) [-131072|131071.999938965] "rpm" Vector__XXX
SG_ Motor_A_target_torque_4 : 48|16@1- (0.1,0) [-3276.8|3276.7] "%" Vector__XXX

BO_ 517 RxPDO_InverterASetpoint1_5: 8 Vector__XXX
SG_ Inverter_A_Controlword_5 : 0|16@1+ (1,0) [0|65535] "" Vector__XXX
SG_ Motor_A_target_velocity_5 : 16|32@1- (6.103515625E-005,0) [-131072|131071.999938965] "rpm" Vector__XXX
SG_ Motor_A_target_torque_5 : 48|16@1- (0.1,0) [-3276.8|3276.7] "%" Vector__XXX

BO_ 518 RxPDO_InverterASetpoint1_6: 8 Vector__XXX
SG_ Inverter_A_Controlword_6 : 0|16@1+ (1,0) [0|65535] "" Vector__XXX
SG_ Motor_A_target_velocity_6 : 16|32@1- (6.103515625E-005,0) [-131072|131071.999938965] "rpm" Vector__XXX
SG_ Motor_A_target_torque_6 : 48|16@1- (0.1,0) [-3276.8|3276.7] "%" Vector__XXX

BO_ 519 RxPDO_InverterASetpoint1_7: 8 Vector__XXX
SG_ Inverter_A_Controlword_7 : 0|16@1+ (1,0) [0|65535] "" Vector__XXX
SG_ Motor_A_target_velocity_7 : 16|32@1- (6.103515625E-005,0) [-131072|131071.999938965] "rpm" Vector__XXX
SG_ Motor_A_target_torque_7 : 48|16@1- (0.1,0) [-3276.8|3276.7] "%" Vector__XXX

BO_ 520 RxPDO_InverterASetpoint1_8: 8 Vector__XXX
SG_ Inverter_A_Controlword_8 : 0|16@1+ (1,0) [0|65535] "" Vector__XXX
SG_ Motor_A_target_velocity_8 : 16|32@1- (6.103515625E-005,0) [-131072|131071.999938965] "rpm" Vector__XXX
SG_ Motor_A_target_torque_8 : 48|16@1- (0.1,0) [-3276.8|3276.7] "%" Vector__XXX

BO_ 521 RxPDO_InverterASetpoint1_9: 8 Vector__XXX
SG_ Inverter_A_Controlword_9 : 0|16@1+ (1,0) [0|65535] "" Vector__XXX
SG_ Motor_A_target_velocity_9 : 16|32@1- (6.103515625E-005,0) [-131072|131071.999938965] "rpm" Vector__XXX
SG_ Motor_A_target_torque_9 : 48|16@1- (0.1,0) [-3276.8|3276.7] "%" Vector__XXX

BO_ 522 RxPDO_InverterASetpoint1_10: 8 Vector__XXX
SG_ Inverter_A_Controlword_10 : 0|16@1+ (1,0) [0|65535] "" Vector__XXX
SG_ Motor_A_target_velocity_10 : 16|32@1- (6.103515625E-005,0) [-131072|131071.999938965] "rpm" Vector__XXX
SG_ Motor_A_target_torque_10 : 48|16@1- (0.1,0) [-3276.8|3276.7] "%" Vector__XXX

BO_ 523 RxPDO_InverterASetpoint1_11: 8 Vector__XXX
SG_ Inverter_A_Controlword_11 : 0|16@1+ (1,0) [0|65535] "" Vector__XXX
SG_ Motor_A_target_velocity_11 : 16|32@1- (6.103515625E-005,0) [-131072|131071.999938965] "rpm" Vector__XXX
SG_ Motor_A_target_torque_11 : 48|16@1- (0.1,0) [-3276.8|3276.7] "%" Vector__XXX

BO_ 524 RxPDO_InverterASetpoint1_12: 8 Vector__XXX
SG_ Inverter_A_Controlword_12 : 0|16@1+ (1,0) [0|65535] "" Vector__XXX
SG_ Motor_A_target_velocity_12 : 16|32@1- (6.103515625E-005,0) [-131072|131071.999938965] "rpm" Vector__XXX
SG_ Motor_A_target_torque_12 : 48|16@1- (0.1,0) [-3276.8|3276.7] "%" Vector__XXX

BO_ 525 RxPDO_InverterASetpoint1_13: 8 Vector__XXX
SG_ Inverter_A_Controlword_13 : 0|16@1+ (1,0) [0|65535] "" Vector__XXX
SG_ Motor_A_target_velocity_13 : 16|32@1- (6.103515625E-005,0) [-131072|131071.999938965] "rpm" Vector__XXX
SG_ Motor_A_target_torque_13 : 48|16@1- (0.1,0) [-3276.8|3276.7] "%" Vector__XXX

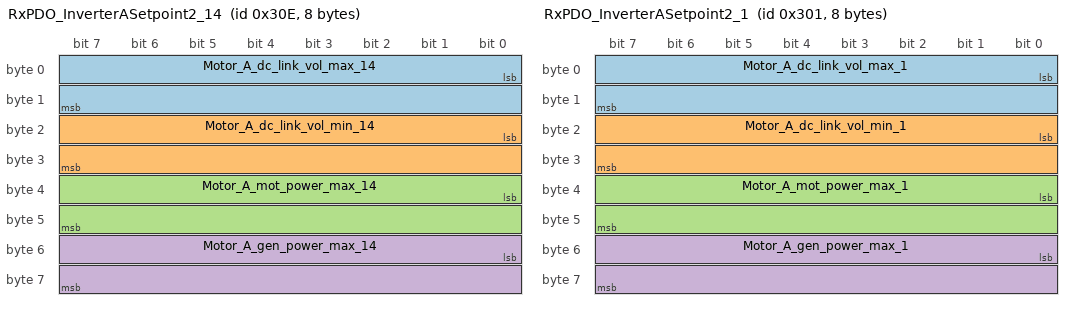
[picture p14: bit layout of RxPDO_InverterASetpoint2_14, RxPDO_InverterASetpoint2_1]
BO_ 782 RxPDO_InverterASetpoint2_14: 8 Vector__XXX
SG_ Motor_A_dc_link_vol_max_14 : 0|16@1- (0.0625,0) [-2048|2047.9375] "V" Vector__XXX
SG_ Motor_A_dc_link_vol_min_14 : 16|16@1- (0.0625,0) [-2048|2047.9375] "V" Vector__XXX
SG_ Motor_A_mot_power_max_14 : 32|16@1- (0.1,0) [-3276.8|3276.7] "%" Vector__XXX
SG_ Motor_A_gen_power_max_14 : 48|16@1- (0.1,0) [-3276.8|3276.7] "%" Vector__XXX

BO_ 769 RxPDO_InverterASetpoint2_1: 8 Vector__XXX
SG_ Motor_A_dc_link_vol_max_1 : 0|16@1- (0.0625,0) [-2048|2047.9375] "V" Vector__XXX
SG_ Motor_A_dc_link_vol_min_1 : 16|16@1- (0.0625,0) [-2048|2047.9375] "V" Vector__XXX
SG_ Motor_A_mot_power_max_1 : 32|16@1- (0.1,0) [-3276.8|3276.7] "%" Vector__XXX
SG_ Motor_A_gen_power_max_1 : 48|16@1- (0.1,0) [-3276.8|3276.7] "%" Vector__XXX

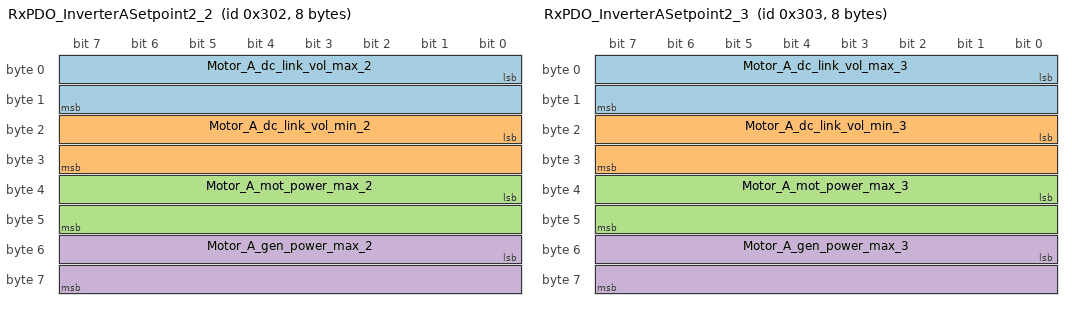
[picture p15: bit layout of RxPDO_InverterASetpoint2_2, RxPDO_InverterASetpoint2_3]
BO_ 770 RxPDO_InverterASetpoint2_2: 8 Vector__XXX
SG_ Motor_A_dc_link_vol_max_2 : 0|16@1- (0.0625,0) [-2048|2047.9375] "V" Vector__XXX
SG_ Motor_A_dc_link_vol_min_2 : 16|16@1- (0.0625,0) [-2048|2047.9375] "V" Vector__XXX
SG_ Motor_A_mot_power_max_2 : 32|16@1- (0.1,0) [-3276.8|3276.7] "%" Vector__XXX
SG_ Motor_A_gen_power_max_2 : 48|16@1- (0.1,0) [-3276.8|3276.7] "%" Vector__XXX

BO_ 771 RxPDO_InverterASetpoint2_3: 8 Vector__XXX
SG_ Motor_A_dc_link_vol_max_3 : 0|16@1- (0.0625,0) [-2048|2047.9375] "V" Vector__XXX
SG_ Motor_A_dc_link_vol_min_3 : 16|16@1- (0.0625,0) [-2048|2047.9375] "V" Vector__XXX
SG_ Motor_A_mot_power_max_3 : 32|16@1- (0.1,0) [-3276.8|3276.7] "%" Vector__XXX
SG_ Motor_A_gen_power_max_3 : 48|16@1- (0.1,0) [-3276.8|3276.7] "%" Vector__XXX

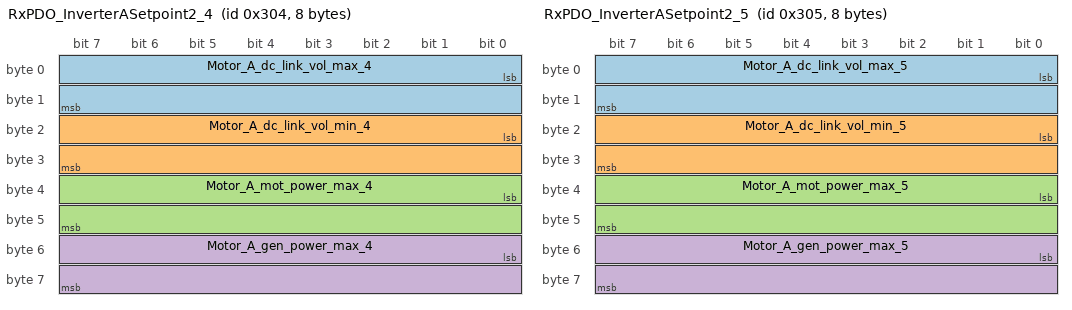
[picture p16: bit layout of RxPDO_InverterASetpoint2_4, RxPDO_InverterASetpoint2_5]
BO_ 772 RxPDO_InverterASetpoint2_4: 8 Vector__XXX
SG_ Motor_A_dc_link_vol_max_4 : 0|16@1- (0.0625,0) [-2048|2047.9375] "V" Vector__XXX
SG_ Motor_A_dc_link_vol_min_4 : 16|16@1- (0.0625,0) [-2048|2047.9375] "V" Vector__XXX
SG_ Motor_A_mot_power_max_4 : 32|16@1- (0.1,0) [-3276.8|3276.7] "%" Vector__XXX
SG_ Motor_A_gen_power_max_4 : 48|16@1- (0.1,0) [-3276.8|3276.7] "%" Vector__XXX

BO_ 773 RxPDO_InverterASetpoint2_5: 8 Vector__XXX
SG_ Motor_A_dc_link_vol_max_5 : 0|16@1- (0.0625,0) [-2048|2047.9375] "V" Vector__XXX
SG_ Motor_A_dc_link_vol_min_5 : 16|16@1- (0.0625,0) [-2048|2047.9375] "V" Vector__XXX
SG_ Motor_A_mot_power_max_5 : 32|16@1- (0.1,0) [-3276.8|3276.7] "%" Vector__XXX
SG_ Motor_A_gen_power_max_5 : 48|16@1- (0.1,0) [-3276.8|3276.7] "%" Vector__XXX

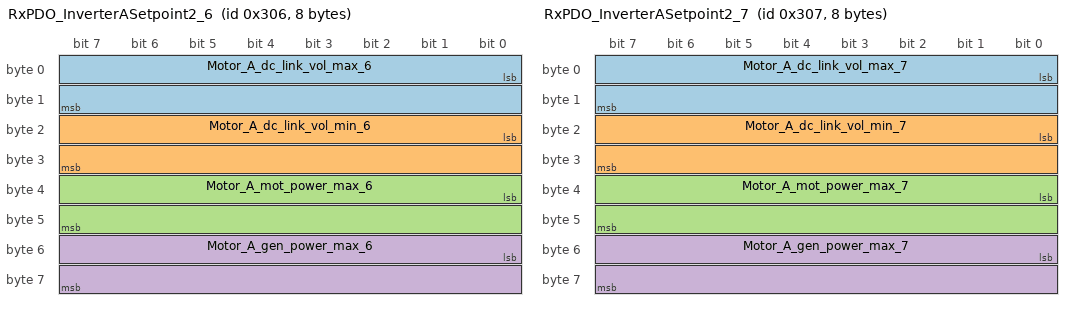
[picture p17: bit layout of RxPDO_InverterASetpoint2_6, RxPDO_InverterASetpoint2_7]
BO_ 774 RxPDO_InverterASetpoint2_6: 8 Vector__XXX
SG_ Motor_A_dc_link_vol_max_6 : 0|16@1- (0.0625,0) [-2048|2047.9375] "V" Vector__XXX
SG_ Motor_A_dc_link_vol_min_6 : 16|16@1- (0.0625,0) [-2048|2047.9375] "V" Vector__XXX
SG_ Motor_A_mot_power_max_6 : 32|16@1- (0.1,0) [-3276.8|3276.7] "%" Vector__XXX
SG_ Motor_A_gen_power_max_6 : 48|16@1- (0.1,0) [-3276.8|3276.7] "%" Vector__XXX

BO_ 775 RxPDO_InverterASetpoint2_7: 8 Vector__XXX
SG_ Motor_A_dc_link_vol_max_7 : 0|16@1- (0.0625,0) [-2048|2047.9375] "V" Vector__XXX
SG_ Motor_A_dc_link_vol_min_7 : 16|16@1- (0.0625,0) [-2048|2047.9375] "V" Vector__XXX
SG_ Motor_A_mot_power_max_7 : 32|16@1- (0.1,0) [-3276.8|3276.7] "%" Vector__XXX
SG_ Motor_A_gen_power_max_7 : 48|16@1- (0.1,0) [-3276.8|3276.7] "%" Vector__XXX

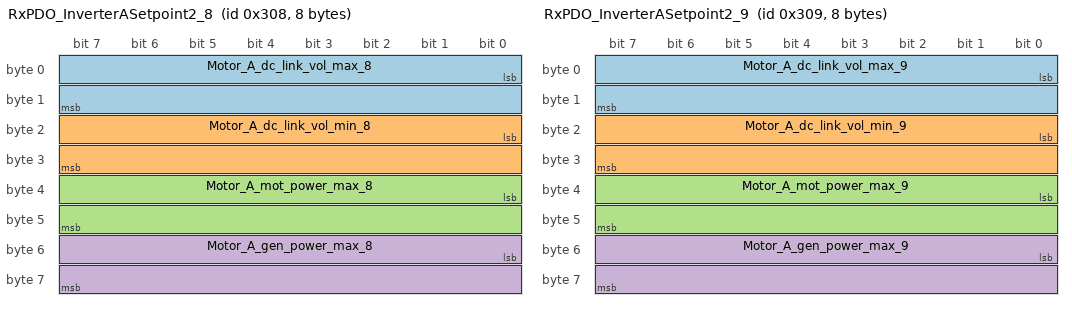
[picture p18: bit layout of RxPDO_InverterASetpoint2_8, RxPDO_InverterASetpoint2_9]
BO_ 776 RxPDO_InverterASetpoint2_8: 8 Vector__XXX
SG_ Motor_A_dc_link_vol_max_8 : 0|16@1- (0.0625,0) [-2048|2047.9375] "V" Vector__XXX
SG_ Motor_A_dc_link_vol_min_8 : 16|16@1- (0.0625,0) [-2048|2047.9375] "V" Vector__XXX
SG_ Motor_A_mot_power_max_8 : 32|16@1- (0.1,0) [-3276.8|3276.7] "%" Vector__XXX
SG_ Motor_A_gen_power_max_8 : 48|16@1- (0.1,0) [-3276.8|3276.7] "%" Vector__XXX

BO_ 777 RxPDO_InverterASetpoint2_9: 8 Vector__XXX
SG_ Motor_A_dc_link_vol_max_9 : 0|16@1- (0.0625,0) [-2048|2047.9375] "V" Vector__XXX
SG_ Motor_A_dc_link_vol_min_9 : 16|16@1- (0.0625,0) [-2048|2047.9375] "V" Vector__XXX
SG_ Motor_A_mot_power_max_9 : 32|16@1- (0.1,0) [-3276.8|3276.7] "%" Vector__XXX
SG_ Motor_A_gen_power_max_9 : 48|16@1- (0.1,0) [-3276.8|3276.7] "%" Vector__XXX

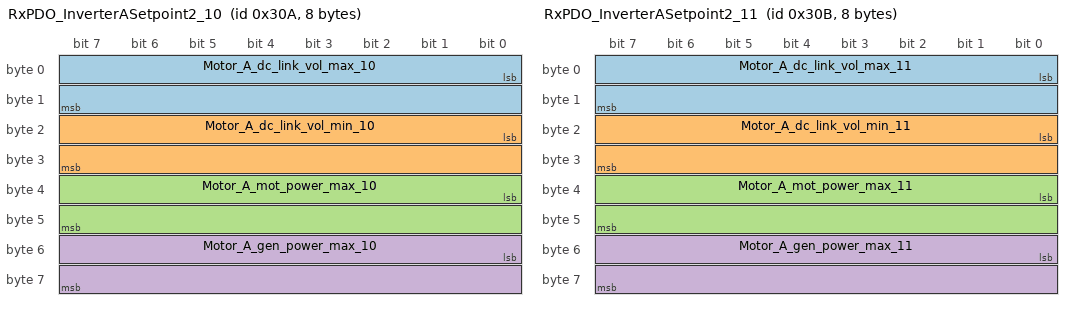
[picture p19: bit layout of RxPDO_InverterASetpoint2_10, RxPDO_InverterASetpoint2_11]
BO_ 778 RxPDO_InverterASetpoint2_10: 8 Vector__XXX
SG_ Motor_A_dc_link_vol_max_10 : 0|16@1- (0.0625,0) [-2048|2047.9375] "V" Vector__XXX
SG_ Motor_A_dc_link_vol_min_10 : 16|16@1- (0.0625,0) [-2048|2047.9375] "V" Vector__XXX
SG_ Motor_A_mot_power_max_10 : 32|16@1- (0.1,0) [-3276.8|3276.7] "%" Vector__XXX
SG_ Motor_A_gen_power_max_10 : 48|16@1- (0.1,0) [-3276.8|3276.7] "%" Vector__XXX

BO_ 779 RxPDO_InverterASetpoint2_11: 8 Vector__XXX
SG_ Motor_A_dc_link_vol_max_11 : 0|16@1- (0.0625,0) [-2048|2047.9375] "V" Vector__XXX
SG_ Motor_A_dc_link_vol_min_11 : 16|16@1- (0.0625,0) [-2048|2047.9375] "V" Vector__XXX
SG_ Motor_A_mot_power_max_11 : 32|16@1- (0.1,0) [-3276.8|3276.7] "%" Vector__XXX
SG_ Motor_A_gen_power_max_11 : 48|16@1- (0.1,0) [-3276.8|3276.7] "%" Vector__XXX

BO_ 780 RxPDO_InverterASetpoint2_12: 8 Vector__XXX
SG_ Motor_A_dc_link_vol_max_12 : 0|16@1- (0.0625,0) [-2048|2047.9375] "V" Vector__XXX
SG_ Motor_A_dc_link_vol_min_12 : 16|16@1- (0.0625,0) [-2048|2047.9375] "V" Vector__XXX
SG_ Motor_A_mot_power_max_12 : 32|16@1- (0.1,0) [-3276.8|3276.7] "%" Vector__XXX
SG_ Motor_A_gen_power_max_12 : 48|16@1- (0.1,0) [-3276.8|3276.7] "%" Vector__XXX

BO_ 781 RxPDO_InverterASetpoint2_13: 8 Vector__XXX
SG_ Motor_A_dc_link_vol_max_13 : 0|16@1- (0.0625,0) [-2048|2047.9375] "V" Vector__XXX
SG_ Motor_A_dc_link_vol_min_13 : 16|16@1- (0.0625,0) [-2048|2047.9375] "V" Vector__XXX
SG_ Motor_A_mot_power_max_13 : 32|16@1- (0.1,0) [-3276.8|3276.7] "%" Vector__XXX
SG_ Motor_A_gen_power_max_13 : 48|16@1- (0.1,0) [-3276.8|3276.7] "%" Vector__XXX

BO_ 1038 RxPDO_InverterBSetpoint1_14: 8 Vector__XXX
SG_ Inverter_B_Controlword_14 : 0|16@1+ (1,0) [0|65535] "" Vector__XXX
SG_ Motor_B_target_velocity_14 : 16|32@1- (6.103515625E-005,0) [-131072|131071.999938965] "rpm" Vector__XXX
SG_ Motor_B_target_torque_14 : 48|16@1- (0.1,0) [-3276.8|3276.7] "%" Vector__XXX

BO_ 1025 RxPDO_InverterBSetpoint1_1: 8 Vector__XXX
SG_ Inverter_B_Controlword_1 : 0|16@1+ (1,0) [0|65535] "" Vector__XXX
SG_ Motor_B_target_velocity_1 : 16|32@1- (6.103515625E-005,0) [-131072|131071.999938965] "rpm" Vector__XXX
SG_ Motor_B_target_torque_1 : 48|16@1- (0.1,0) [-3276.8|3276.7] "%" Vector__XXX

BO_ 1026 RxPDO_InverterBSetpoint1_2: 8 Vector__XXX
SG_ Inverter_B_Controlword_2 : 0|16@1+ (1,0) [0|65535] "" Vector__XXX
SG_ Motor_B_target_velocity_2 : 16|32@1- (6.103515625E-005,0) [-131072|131071.999938965] "rpm" Vector__XXX
SG_ Motor_B_target_torque_2 : 48|16@1- (0.1,0) [-3276.8|3276.7] "%" Vector__XXX

BO_ 1027 RxPDO_InverterBSetpoint1_3: 8 Vector__XXX
SG_ Inverter_B_Controlword_3 : 0|16@1+ (1,0) [0|65535] "" Vector__XXX
SG_ Motor_B_target_velocity_3 : 16|32@1- (6.103515625E-005,0) [-131072|131071.999938965] "rpm" Vector__XXX
SG_ Motor_B_target_torque_3 : 48|16@1- (0.1,0) [-3276.8|3276.7] "%" Vector__XXX

BO_ 1028 RxPDO_InverterBSetpoint1_4: 8 Vector__XXX
SG_ Inverter_B_Controlword_4 : 0|16@1+ (1,0) [0|65535] "" Vector__XXX
SG_ Motor_B_target_velocity_4 : 16|32@1- (6.103515625E-005,0) [-131072|131071.999938965] "rpm" Vector__XXX
SG_ Motor_B_target_torque_4 : 48|16@1- (0.1,0) [-3276.8|3276.7] "%" Vector__XXX

BO_ 1029 RxPDO_InverterBSetpoint1_5: 8 Vector__XXX
SG_ Inverter_B_Controlword_5 : 0|16@1+ (1,0) [0|65535] "" Vector__XXX
SG_ Motor_B_target_velocity_5 : 16|32@1- (6.103515625E-005,0) [-131072|131071.999938965] "rpm" Vector__XXX
SG_ Motor_B_target_torque_5 : 48|16@1- (0.1,0) [-3276.8|3276.7] "%" Vector__XXX

BO_ 1030 RxPDO_InverterBSetpoint1_6: 8 Vector__XXX
SG_ Inverter_B_Controlword_6 : 0|16@1+ (1,0) [0|65535] "" Vector__XXX
SG_ Motor_B_target_velocity_6 : 16|32@1- (6.103515625E-005,0) [-131072|131071.999938965] "rpm" Vector__XXX
SG_ Motor_B_target_torque_6 : 48|16@1- (0.1,0) [-3276.8|3276.7] "%" Vector__XXX

BO_ 1031 RxPDO_InverterBSetpoint1_7: 8 Vector__XXX
SG_ Inverter_B_Controlword_7 : 0|16@1+ (1,0) [0|65535] "" Vector__XXX
SG_ Motor_B_target_velocity_7 : 16|32@1- (6.103515625E-005,0) [-131072|131071.999938965] "rpm" Vector__XXX
SG_ Motor_B_target_torque_7 : 48|16@1- (0.1,0) [-3276.8|3276.7] "%" Vector__XXX

BO_ 1032 RxPDO_InverterBSetpoint1_8: 8 Vector__XXX
SG_ Inverter_B_Controlword_8 : 0|16@1+ (1,0) [0|65535] "" Vector__XXX
SG_ Motor_B_target_velocity_8 : 16|32@1- (6.103515625E-005,0) [-131072|131071.999938965] "rpm" Vector__XXX
SG_ Motor_B_target_torque_8 : 48|16@1- (0.1,0) [-3276.8|3276.7] "%" Vector__XXX

BO_ 1033 RxPDO_InverterBSetpoint1_9: 8 Vector__XXX
SG_ Inverter_B_Controlword_9 : 0|16@1+ (1,0) [0|65535] "" Vector__XXX
SG_ Motor_B_target_velocity_9 : 16|32@1- (6.103515625E-005,0) [-131072|131071.999938965] "rpm" Vector__XXX
SG_ Motor_B_target_torque_9 : 48|16@1- (0.1,0) [-3276.8|3276.7] "%" Vector__XXX

BO_ 1034 RxPDO_InverterBSetpoint1_10: 8 Vector__XXX
SG_ Inverter_B_Controlword_10 : 0|16@1+ (1,0) [0|65535] "" Vector__XXX
SG_ Motor_B_target_velocity_10 : 16|32@1- (6.103515625E-005,0) [-131072|131071.999938965] "rpm" Vector__XXX
SG_ Motor_B_target_torque_10 : 48|16@1- (0.1,0) [-3276.8|3276.7] "%" Vector__XXX

BO_ 1035 RxPDO_InverterBSetpoint1_11: 8 Vector__XXX
SG_ Inverter_B_Controlword_11 : 0|16@1+ (1,0) [0|65535] "" Vector__XXX
SG_ Motor_B_target_velocity_11 : 16|32@1- (6.103515625E-005,0) [-131072|131071.999938965] "rpm" Vector__XXX
SG_ Motor_B_target_torque_11 : 48|16@1- (0.1,0) [-3276.8|3276.7] "%" Vector__XXX

BO_ 1036 RxPDO_InverterBSetpoint1_12: 8 Vector__XXX
SG_ Inverter_B_Controlword_12 : 0|16@1+ (1,0) [0|65535] "" Vector__XXX
SG_ Motor_B_target_velocity_12 : 16|32@1- (6.103515625E-005,0) [-131072|131071.999938965] "rpm" Vector__XXX
SG_ Motor_B_target_torque_12 : 48|16@1- (0.1,0) [-3276.8|3276.7] "%" Vector__XXX

BO_ 1037 RxPDO_InverterBSetpoint1_13: 8 Vector__XXX
SG_ Inverter_B_Controlword_13 : 0|16@1+ (1,0) [0|65535] "" Vector__XXX
SG_ Motor_B_target_velocity_13 : 16|32@1- (6.103515625E-005,0) [-131072|131071.999938965] "rpm" Vector__XXX
SG_ Motor_B_target_torque_13 : 48|16@1- (0.1,0) [-3276.8|3276.7] "%" Vector__XXX

BO_ 1294 RxPDO_InverterBSetpoint2_14: 8 Vector__XXX
SG_ Motor_B_dc_link_vol_max_14 : 0|16@1- (0.0625,0) [-2048|2047.9375] "V" Vector__XXX
SG_ Motor_B_dc_link_vol_min_14 : 16|16@1- (0.0625,0) [-2048|2047.9375] "V" Vector__XXX
SG_ Motor_B_mot_power_max_14 : 32|16@1- (0.1,0) [-3276.8|3276.7] "%" Vector__XXX
SG_ Motor_B_gen_power_max_14 : 48|16@1- (0.1,0) [-3276.8|3276.7] "%" Vector__XXX

BO_ 1281 RxPDO_InverterBSetpoint2_1: 8 Vector__XXX
SG_ Motor_B_dc_link_vol_max_1 : 0|16@1- (0.0625,0) [-2048|2047.9375] "V" Vector__XXX
SG_ Motor_B_dc_link_vol_min_1 : 16|16@1- (0.0625,0) [-2048|2047.9375] "V" Vector__XXX
SG_ Motor_B_mot_power_max_1 : 32|16@1- (0.1,0) [-3276.8|3276.7] "%" Vector__XXX
SG_ Motor_B_gen_power_max_1 : 48|16@1- (0.1,0) [-3276.8|3276.7] "%" Vector__XXX

BO_ 1282 RxPDO_InverterBSetpoint2_2: 8 Vector__XXX
SG_ Motor_B_dc_link_vol_max_2 : 0|16@1- (0.0625,0) [-2048|2047.9375] "V" Vector__XXX
SG_ Motor_B_dc_link_vol_min_2 : 16|16@1- (0.0625,0) [-2048|2047.9375] "V" Vector__XXX
SG_ Motor_B_mot_power_max_2 : 32|16@1- (0.1,0) [-3276.8|3276.7] "%" Vector__XXX
SG_ Motor_B_gen_power_max_2 : 48|16@1- (0.1,0) [-3276.8|3276.7] "%" Vector__XXX

BO_ 1283 RxPDO_InverterBSetpoint2_3: 8 Vector__XXX
SG_ Motor_B_dc_link_vol_max_3 : 0|16@1- (0.0625,0) [-2048|2047.9375] "V" Vector__XXX
SG_ Motor_B_dc_link_vol_min_3 : 16|16@1- (0.0625,0) [-2048|2047.9375] "V" Vector__XXX
SG_ Motor_B_mot_power_max_3 : 32|16@1- (0.1,0) [-3276.8|3276.7] "%" Vector__XXX
SG_ Motor_B_gen_power_max_3 : 48|16@1- (0.1,0) [-3276.8|3276.7] "%" Vector__XXX

BO_ 1284 RxPDO_InverterBSetpoint2_4: 8 Vector__XXX
SG_ Motor_B_dc_link_vol_max_4 : 0|16@1- (0.0625,0) [-2048|2047.9375] "V" Vector__XXX
SG_ Motor_B_dc_link_vol_min_4 : 16|16@1- (0.0625,0) [-2048|2047.9375] "V" Vector__XXX
SG_ Motor_B_mot_power_max_4 : 32|16@1- (0.1,0) [-3276.8|3276.7] "%" Vector__XXX
SG_ Motor_B_gen_power_max_4 : 48|16@1- (0.1,0) [-3276.8|3276.7] "%" Vector__XXX

BO_ 1285 RxPDO_InverterBSetpoint2_5: 8 Vector__XXX
SG_ Motor_B_dc_link_vol_max_5 : 0|16@1- (0.0625,0) [-2048|2047.9375] "V" Vector__XXX
SG_ Motor_B_dc_link_vol_min_5 : 16|16@1- (0.0625,0) [-2048|2047.9375] "V" Vector__XXX
SG_ Motor_B_mot_power_max_5 : 32|16@1- (0.1,0) [-3276.8|3276.7] "%" Vector__XXX
SG_ Motor_B_gen_power_max_5 : 48|16@1- (0.1,0) [-3276.8|3276.7] "%" Vector__XXX

BO_ 1286 RxPDO_InverterBSetpoint2_6: 8 Vector__XXX
SG_ Motor_B_dc_link_vol_max_6 : 0|16@1- (0.0625,0) [-2048|2047.9375] "V" Vector__XXX
SG_ Motor_B_dc_link_vol_min_6 : 16|16@1- (0.0625,0) [-2048|2047.9375] "V" Vector__XXX
SG_ Motor_B_mot_power_max_6 : 32|16@1- (0.1,0) [-3276.8|3276.7] "%" Vector__XXX
SG_ Motor_B_gen_power_max_6 : 48|16@1- (0.1,0) [-3276.8|3276.7] "%" Vector__XXX

BO_ 1287 RxPDO_InverterBSetpoint2_7: 8 Vector__XXX
SG_ Motor_B_dc_link_vol_max_7 : 0|16@1- (0.0625,0) [-2048|2047.9375] "V" Vector__XXX
SG_ Motor_B_dc_link_vol_min_7 : 16|16@1- (0.0625,0) [-2048|2047.9375] "V" Vector__XXX
SG_ Motor_B_mot_power_max_7 : 32|16@1- (0.1,0) [-3276.8|3276.7] "%" Vector__XXX
SG_ Motor_B_gen_power_max_7 : 48|16@1- (0.1,0) [-3276.8|3276.7] "%" Vector__XXX

BO_ 1288 RxPDO_InverterBSetpoint2_8: 8 Vector__XXX
SG_ Motor_B_dc_link_vol_max_8 : 0|16@1- (0.0625,0) [-2048|2047.9375] "V" Vector__XXX
SG_ Motor_B_dc_link_vol_min_8 : 16|16@1- (0.0625,0) [-2048|2047.9375] "V" Vector__XXX
SG_ Motor_B_mot_power_max_8 : 32|16@1- (0.1,0) [-3276.8|3276.7] "%" Vector__XXX
SG_ Motor_B_gen_power_max_8 : 48|16@1- (0.1,0) [-3276.8|3276.7] "%" Vector__XXX

BO_ 1289 RxPDO_InverterBSetpoint2_9: 8 Vector__XXX
SG_ Motor_B_dc_link_vol_max_9 : 0|16@1- (0.0625,0) [-2048|2047.9375] "V" Vector__XXX
SG_ Motor_B_dc_link_vol_min_9 : 16|16@1- (0.0625,0) [-2048|2047.9375] "V" Vector__XXX
SG_ Motor_B_mot_power_max_9 : 32|16@1- (0.1,0) [-3276.8|3276.7] "%" Vector__XXX
SG_ Motor_B_gen_power_max_9 : 48|16@1- (0.1,0) [-3276.8|3276.7] "%" Vector__XXX

BO_ 1290 RxPDO_InverterBSetpoint2_10: 8 Vector__XXX
SG_ Motor_B_dc_link_vol_max_10 : 0|16@1- (0.0625,0) [-2048|2047.9375] "V" Vector__XXX
SG_ Motor_B_dc_link_vol_min_10 : 16|16@1- (0.0625,0) [-2048|2047.9375] "V" Vector__XXX
SG_ Motor_B_mot_power_max_10 : 32|16@1- (0.1,0) [-3276.8|3276.7] "%" Vector__XXX
SG_ Motor_B_gen_power_max_10 : 48|16@1- (0.1,0) [-3276.8|3276.7] "%" Vector__XXX

BO_ 1291 RxPDO_InverterBSetpoint2_11: 8 Vector__XXX
SG_ Motor_B_dc_link_vol_max_11 : 0|16@1- (0.0625,0) [-2048|2047.9375] "V" Vector__XXX
SG_ Motor_B_dc_link_vol_min_11 : 16|16@1- (0.0625,0) [-2048|2047.9375] "V" Vector__XXX
SG_ Motor_B_mot_power_max_11 : 32|16@1- (0.1,0) [-3276.8|3276.7] "%" Vector__XXX
SG_ Motor_B_gen_power_max_11 : 48|16@1- (0.1,0) [-3276.8|3276.7] "%" Vector__XXX

BO_ 1292 RxPDO_InverterBSetpoint2_12: 8 Vector__XXX
SG_ Motor_B_dc_link_vol_max_12 : 0|16@1- (0.0625,0) [-2048|2047.9375] "V" Vector__XXX
SG_ Motor_B_dc_link_vol_min_12 : 16|16@1- (0.0625,0) [-2048|2047.9375] "V" Vector__XXX
SG_ Motor_B_mot_power_max_12 : 32|16@1- (0.1,0) [-3276.8|3276.7] "%" Vector__XXX
SG_ Motor_B_gen_power_max_12 : 48|16@1- (0.1,0) [-3276.8|3276.7] "%" Vector__XXX

BO_ 1293 RxPDO_InverterBSetpoint2_13: 8 Vector__XXX
SG_ Motor_B_dc_link_vol_max_13 : 0|16@1- (0.0625,0) [-2048|2047.9375] "V" Vector__XXX
SG_ Motor_B_dc_link_vol_min_13 : 16|16@1- (0.0625,0) [-2048|2047.9375] "V" Vector__XXX
SG_ Motor_B_mot_power_max_13 : 32|16@1- (0.1,0) [-3276.8|3276.7] "%" Vector__XXX
SG_ Motor_B_gen_power_max_13 : 48|16@1- (0.1,0) [-3276.8|3276.7] "%" Vector__XXX

BO_ 1358 RxPDO_DeviceSetpoint_14: 8 Vector__XXX
SG_ system_time_stamp_14 : 0|32@1+ (1,0) [0|4294967295] "ms" Vector__XXX
SG_ dc_link_vol_precharge_dmd_14 : 32|16@1- (0.0625,0) [-2048|2047.9375] "V" Vector__XXX

BO_ 1345 RxPDO_DeviceSetpoint_1: 8 Vector__XXX
SG_ system_time_stamp_1 : 0|32@1+ (1,0) [0|4294967295] "ms" Vector__XXX
SG_ dc_link_vol_precharge_dmd_1 : 32|16@1- (0.0625,0) [-2048|2047.9375] "V" Vector__XXX

BO_ 1346 RxPDO_DeviceSetpoint_2: 8 Vector__XXX
SG_ system_time_stamp_2 : 0|32@1+ (1,0) [0|4294967295] "ms" Vector__XXX
SG_ dc_link_vol_precharge_dmd_2 : 32|16@1- (0.0625,0) [-2048|2047.9375] "V" Vector__XXX

BO_ 1347 RxPDO_DeviceSetpoint_3: 8 Vector__XXX
SG_ system_time_stamp_3 : 0|32@1+ (1,0) [0|4294967295] "ms" Vector__XXX
SG_ dc_link_vol_precharge_dmd_3 : 32|16@1- (0.0625,0) [-2048|2047.9375] "V" Vector__XXX

BO_ 1348 RxPDO_DeviceSetpoint_4: 8 Vector__XXX
SG_ system_time_stamp_4 : 0|32@1+ (1,0) [0|4294967295] "ms" Vector__XXX
SG_ dc_link_vol_precharge_dmd_4 : 32|16@1- (0.0625,0) [-2048|2047.9375] "V" Vector__XXX

BO_ 1349 RxPDO_DeviceSetpoint_5: 8 Vector__XXX
SG_ system_time_stamp_5 : 0|32@1+ (1,0) [0|4294967295] "ms" Vector__XXX
SG_ dc_link_vol_precharge_dmd_5 : 32|16@1- (0.0625,0) [-2048|2047.9375] "V" Vector__XXX

BO_ 1350 RxPDO_DeviceSetpoint_6: 8 Vector__XXX
SG_ system_time_stamp_6 : 0|32@1+ (1,0) [0|4294967295] "ms" Vector__XXX
SG_ dc_link_vol_precharge_dmd_6 : 32|16@1- (0.0625,0) [-2048|2047.9375] "V" Vector__XXX

BO_ 1351 RxPDO_DeviceSetpoint_7: 8 Vector__XXX
SG_ system_time_stamp_7 : 0|32@1+ (1,0) [0|4294967295] "ms" Vector__XXX
SG_ dc_link_vol_precharge_dmd_7 : 32|16@1- (0.0625,0) [-2048|2047.9375] "V" Vector__XXX

BO_ 1352 RxPDO_DeviceSetpoint_8: 8 Vector__XXX
SG_ system_time_stamp_8 : 0|32@1+ (1,0) [0|4294967295] "ms" Vector__XXX
SG_ dc_link_vol_precharge_dmd_8 : 32|16@1- (0.0625,0) [-2048|2047.9375] "V" Vector__XXX

BO_ 1353 RxPDO_DeviceSetpoint_9: 8 Vector__XXX
SG_ system_time_stamp_9 : 0|32@1+ (1,0) [0|4294967295] "ms" Vector__XXX
SG_ dc_link_vol_precharge_dmd_9 : 32|16@1- (0.0625,0) [-2048|2047.9375] "V" Vector__XXX

BO_ 1354 RxPDO_DeviceSetpoint_10: 8 Vector__XXX
SG_ system_time_stamp_10 : 0|32@1+ (1,0) [0|4294967295] "ms" Vector__XXX
SG_ dc_link_vol_precharge_dmd_10 : 32|16@1- (0.0625,0) [-2048|2047.9375] "V" Vector__XXX

BO_ 1355 RxPDO_DeviceSetpoint_11: 8 Vector__XXX
SG_ system_time_stamp_11 : 0|32@1+ (1,0) [0|4294967295] "ms" Vector__XXX
SG_ dc_link_vol_precharge_dmd_11 : 32|16@1- (0.0625,0) [-2048|2047.9375] "V" Vector__XXX

BO_ 1356 RxPDO_DeviceSetpoint_12: 8 Vector__XXX
SG_ system_time_stamp_12 : 0|32@1+ (1,0) [0|4294967295] "ms" Vector__XXX
SG_ dc_link_vol_precharge_dmd_12 : 32|16@1- (0.0625,0) [-2048|2047.9375] "V" Vector__XXX

BO_ 1357 RxPDO_DeviceSetpoint_13: 8 Vector__XXX
SG_ system_time_stamp_13 : 0|32@1+ (1,0) [0|4294967295] "ms" Vector__XXX
SG_ dc_link_vol_precharge_dmd_13 : 32|16@1- (0.0625,0) [-2048|2047.9375] "V" Vector__XXX

BA_DEF_  "BusType" STRING ;
BA_DEF_ SG_  "GenSigStartValue" FLOAT -3.4E+038 3.4E+038;

BA_DEF_DEF_  "BusType" "CAN";
BA_DEF_DEF_  "GenSigStartValue" 0;

VAL_ 462 Inverter_A_Statusword_14 0 "NotReadyToSwitchOn" 64 "SwitchOnDisabled" 80 "SwitchOnDisabled" 96 "SwitchOnDisabled" 112 "SwitchOnDisabled" 33 "ReadyToSwitchOn" 49 "ReadyToSwitchOn" 35 "SwitchedOn" 51 "SwitchedOn" 39 "OperationEnabled" 55 "OperationEnabled" 7 "QuickStopActive" 23 "QuickStopActive" 15 "FaultReactionActive" 31 "FaultReactionActive" 47 "FaultReactionActive" 63 "FaultReactionActive" 8 "Fault" 24 "Fault" 40 "Fault" 56 "Fault" ;
VAL_ 462 EVENTBUFFER_NEW_EVENT 0 "no" 1 "yes" ;
VAL_ 462 EVENTBUFFER_OVERFLOW 0 "no" 1 "yes" ;
VAL_ 462 POWERMODULE_TRIPZONE_OVERCURRE 0 "no" 1 "yes" ;
VAL_ 462 POWERMODULE_CURRENT_OFFSET_INI 0 "no" 1 "yes" ;
VAL_ 462 POWERMODULE_TEMPSENSOR_ERROR 0 "no" 1 "yes" ;
VAL_ 462 POWERMODULE_TEMPERATURE_WARNIN 0 "no" 1 "yes" ;
VAL_ 462 POWERMODULE_OVERTEMPERATURE 0 "no" 1 "yes" ;
VAL_ 462 POWERMODULE_IXT_FAULT 0 "no" 1 "yes" ;
VAL_ 462 POWERMODULE_SW_OVERCURRENT 0 "no" 1 "yes" ;
VAL_ 462 POWERMODULE_PATTERNDATA_INCONS 0 "no" 1 "yes" ;
VAL_ 462 DCBUS_TRIPZONE_OVERVOLTAGE 0 "no" 1 "yes" ;
VAL_ 462 DCBUS_SW_OVERVOLTAGE 0 "no" 1 "yes" ;
VAL_ 462 DCBUS_SW_UNDERVOLTAGE 0 "no" 1 "yes" ;
VAL_ 462 NEIGHBOUR_FAULT 0 "no" 1 "yes" ;
VAL_ 462 MOTOR_TEMPSENSOR_ERROR 0 "no" 1 "yes" ;
VAL_ 462 MOTOR_TEMPERATURE_WARNING 0 "no" 1 "yes" ;
VAL_ 462 MOTOR_OVERTEMPERATURE 0 "no" 1 "yes" ;
VAL_ 462 MOTOR_STATOR_FREQ_TO_HIGH 0 "no" 1 "yes" ;
VAL_ 462 SUPPLYVOLTAGE_ERROR 0 "no" 1 "yes" ;
VAL_ 462 RPDO_TIMEOUT 0 "no" 1 "yes" ;
VAL_ 462 NMT_NOT_OPERATIONAL 0 "no" 1 "yes" ;
VAL_ 462 TASKOVERRUN 0 "no" 1 "yes" ;
VAL_ 462 NETSYNC_ERROR 0 "no" 1 "yes" ;
VAL_ 462 POSDEVICE_SIGNAL_TO_LOW 0 "no" 1 "yes" ;
VAL_ 462 POSDEVICE_SIGNAL_TO_HIGH 0 "no" 1 "yes" ;
VAL_ 462 RESOLVER_CALIBRATION_FAILED 0 "no" 1 "yes" ;
VAL_ 462 SYSTEM_FAULT 0 "no" 1 "yes" ;
VAL_ 462 INTERLOCK_OPEN 0 "no" 1 "yes" ;
VAL_ 462 APPC_HAS_GATE_DRIVER_DISABLED 0 "no" 1 "yes" ;
VAL_ 462 MOTOR_STALL_ERROR 0 "no" 1 "yes" ;
VAL_ 462 AMBIENT_TEMPERATURE_WARNING 0 "no" 1 "yes" ;
VAL_ 462 AMBIENT_OVERTEMPERATURE 0 "no" 1 "yes" ;
VAL_ 462 AMBIENT_TEMPSENSOR_ERROR 0 "no" 1 "yes" ;
VAL_ 462 POWERMODULE_CLAMPING_TIMEOUT 0 "no" 1 "yes" ;
VAL_ 462 DCBUS_RIPPLE_TO_HIGH 0 "no" 1 "yes" ;
VAL_ 462 MOTOR_I2XT_WARNING 0 "no" 1 "yes" ;
VAL_ 462 MOTOR_I2XT_ERROR 0 "no" 1 "yes" ;
VAL_ 462 MOTOR_FIELDWEAKENING_ERROR 0 "no" 1 "yes" ;
VAL_ 462 INVALID_PARAMETER_COMBINATION 0 "no" 1 "yes" ;
VAL_ 462 PLUG_COVER_SENSOR_SIGNAL_LOW 0 "no" 1 "yes" ;
VAL_ 462 MOTOR_CONNECTION_TEST_FAILED 0 "no" 1 "yes" ;
VAL_ 462 POWERMODULE_IXT_WARNING 0 "no" 1 "yes" ;
VAL_ 462 ISOLATION_FAULT 0 "no" 1 "yes" ;
VAL_ 449 Inverter_A_Statusword_1 0 "NotReadyToSwitchOn" 64 "SwitchOnDisabled" 80 "SwitchOnDisabled" 96 "SwitchOnDisabled" 112 "SwitchOnDisabled" 33 "ReadyToSwitchOn" 49 "ReadyToSwitchOn" 35 "SwitchedOn" 51 "SwitchedOn" 39 "OperationEnabled" 55 "OperationEnabled" 7 "QuickStopActive" 23 "QuickStopActive" 15 "FaultReactionActive" 31 "FaultReactionActive" 47 "FaultReactionActive" 63 "FaultReactionActive" 8 "Fault" 24 "Fault" 40 "Fault" 56 "Fault" ;
VAL_ 449 EVENTBUFFER_NEW_EVENT 0 "no" 1 "yes" ;
VAL_ 449 EVENTBUFFER_OVERFLOW 0 "no" 1 "yes" ;
VAL_ 449 POWERMODULE_TRIPZONE_OVERCURRE 0 "no" 1 "yes" ;
VAL_ 449 POWERMODULE_CURRENT_OFFSET_INI 0 "no" 1 "yes" ;
VAL_ 449 POWERMODULE_TEMPSENSOR_ERROR 0 "no" 1 "yes" ;
VAL_ 449 POWERMODULE_TEMPERATURE_WARNIN 0 "no" 1 "yes" ;
VAL_ 449 POWERMODULE_OVERTEMPERATURE 0 "no" 1 "yes" ;
VAL_ 449 POWERMODULE_IXT_FAULT 0 "no" 1 "yes" ;
VAL_ 449 POWERMODULE_SW_OVERCURRENT 0 "no" 1 "yes" ;
VAL_ 449 POWERMODULE_PATTERNDATA_INCONS 0 "no" 1 "yes" ;
VAL_ 449 DCBUS_TRIPZONE_OVERVOLTAGE 0 "no" 1 "yes" ;
VAL_ 449 DCBUS_SW_OVERVOLTAGE 0 "no" 1 "yes" ;
VAL_ 449 DCBUS_SW_UNDERVOLTAGE 0 "no" 1 "yes" ;
VAL_ 449 NEIGHBOUR_FAULT 0 "no" 1 "yes" ;
VAL_ 449 MOTOR_TEMPSENSOR_ERROR 0 "no" 1 "yes" ;
VAL_ 449 MOTOR_TEMPERATURE_WARNING 0 "no" 1 "yes" ;
VAL_ 449 MOTOR_OVERTEMPERATURE 0 "no" 1 "yes" ;
VAL_ 449 MOTOR_STATOR_FREQ_TO_HIGH 0 "no" 1 "yes" ;
VAL_ 449 SUPPLYVOLTAGE_ERROR 0 "no" 1 "yes" ;
VAL_ 449 RPDO_TIMEOUT 0 "no" 1 "yes" ;
VAL_ 449 NMT_NOT_OPERATIONAL 0 "no" 1 "yes" ;
VAL_ 449 TASKOVERRUN 0 "no" 1 "yes" ;
VAL_ 449 NETSYNC_ERROR 0 "no" 1 "yes" ;
VAL_ 449 POSDEVICE_SIGNAL_TO_LOW 0 "no" 1 "yes" ;
VAL_ 449 POSDEVICE_SIGNAL_TO_HIGH 0 "no" 1 "yes" ;
VAL_ 449 RESOLVER_CALIBRATION_FAILED 0 "no" 1 "yes" ;
VAL_ 449 SYSTEM_FAULT 0 "no" 1 "yes" ;
VAL_ 449 INTERLOCK_OPEN 0 "no" 1 "yes" ;
VAL_ 449 APPC_HAS_GATE_DRIVER_DISABLED 0 "no" 1 "yes" ;
VAL_ 449 MOTOR_STALL_ERROR 0 "no" 1 "yes" ;
VAL_ 449 AMBIENT_TEMPERATURE_WARNING 0 "no" 1 "yes" ;
VAL_ 449 AMBIENT_OVERTEMPERATURE 0 "no" 1 "yes" ;
VAL_ 449 AMBIENT_TEMPSENSOR_ERROR 0 "no" 1 "yes" ;
VAL_ 449 POWERMODULE_CLAMPING_TIMEOUT 0 "no" 1 "yes" ;
VAL_ 449 DCBUS_RIPPLE_TO_HIGH 0 "no" 1 "yes" ;
VAL_ 449 MOTOR_I2XT_WARNING 0 "no" 1 "yes" ;
VAL_ 449 MOTOR_I2XT_ERROR 0 "no" 1 "yes" ;
VAL_ 449 MOTOR_FIELDWEAKENING_ERROR 0 "no" 1 "yes" ;
VAL_ 449 INVALID_PARAMETER_COMBINATION 0 "no" 1 "yes" ;
VAL_ 449 PLUG_COVER_SENSOR_SIGNAL_LOW 0 "no" 1 "yes" ;
VAL_ 449 MOTOR_CONNECTION_TEST_FAILED 0 "no" 1 "yes" ;
VAL_ 449 POWERMODULE_IXT_WARNING 0 "no" 1 "yes" ;
VAL_ 449 ISOLATION_FAULT 0 "no" 1 "yes" ;
VAL_ 450 Inverter_A_Statusword_2 0 "NotReadyToSwitchOn" 64 "SwitchOnDisabled" 80 "SwitchOnDisabled" 96 "SwitchOnDisabled" 112 "SwitchOnDisabled" 33 "ReadyToSwitchOn" 49 "ReadyToSwitchOn" 35 "SwitchedOn" 51 "SwitchedOn" 39 "OperationEnabled" 55 "OperationEnabled" 7 "QuickStopActive" 23 "QuickStopActive" 15 "FaultReactionActive" 31 "FaultReactionActive" 47 "FaultReactionActive" 63 "FaultReactionActive" 8 "Fault" 24 "Fault" 40 "Fault" 56 "Fault" ;
VAL_ 450 EVENTBUFFER_NEW_EVENT 0 "no" 1 "yes" ;
VAL_ 450 EVENTBUFFER_OVERFLOW 0 "no" 1 "yes" ;
VAL_ 450 POWERMODULE_TRIPZONE_OVERCURRE 0 "no" 1 "yes" ;
VAL_ 450 POWERMODULE_CURRENT_OFFSET_INI 0 "no" 1 "yes" ;
VAL_ 450 POWERMODULE_TEMPSENSOR_ERROR 0 "no" 1 "yes" ;
VAL_ 450 POWERMODULE_TEMPERATURE_WARNIN 0 "no" 1 "yes" ;
VAL_ 450 POWERMODULE_OVERTEMPERATURE 0 "no" 1 "yes" ;
VAL_ 450 POWERMODULE_IXT_FAULT 0 "no" 1 "yes" ;
VAL_ 450 POWERMODULE_SW_OVERCURRENT 0 "no" 1 "yes" ;
VAL_ 450 POWERMODULE_PATTERNDATA_INCONS 0 "no" 1 "yes" ;
VAL_ 450 DCBUS_TRIPZONE_OVERVOLTAGE 0 "no" 1 "yes" ;
VAL_ 450 DCBUS_SW_OVERVOLTAGE 0 "no" 1 "yes" ;
VAL_ 450 DCBUS_SW_UNDERVOLTAGE 0 "no" 1 "yes" ;
VAL_ 450 NEIGHBOUR_FAULT 0 "no" 1 "yes" ;
VAL_ 450 MOTOR_TEMPSENSOR_ERROR 0 "no" 1 "yes" ;
VAL_ 450 MOTOR_TEMPERATURE_WARNING 0 "no" 1 "yes" ;
VAL_ 450 MOTOR_OVERTEMPERATURE 0 "no" 1 "yes" ;
VAL_ 450 MOTOR_STATOR_FREQ_TO_HIGH 0 "no" 1 "yes" ;
VAL_ 450 SUPPLYVOLTAGE_ERROR 0 "no" 1 "yes" ;
VAL_ 450 RPDO_TIMEOUT 0 "no" 1 "yes" ;
VAL_ 450 NMT_NOT_OPERATIONAL 0 "no" 1 "yes" ;
VAL_ 450 TASKOVERRUN 0 "no" 1 "yes" ;
VAL_ 450 NETSYNC_ERROR 0 "no" 1 "yes" ;
VAL_ 450 POSDEVICE_SIGNAL_TO_LOW 0 "no" 1 "yes" ;
VAL_ 450 POSDEVICE_SIGNAL_TO_HIGH 0 "no" 1 "yes" ;
VAL_ 450 RESOLVER_CALIBRATION_FAILED 0 "no" 1 "yes" ;
VAL_ 450 SYSTEM_FAULT 0 "no" 1 "yes" ;
VAL_ 450 INTERLOCK_OPEN 0 "no" 1 "yes" ;
VAL_ 450 APPC_HAS_GATE_DRIVER_DISABLED 0 "no" 1 "yes" ;
VAL_ 450 MOTOR_STALL_ERROR 0 "no" 1 "yes" ;
VAL_ 450 AMBIENT_TEMPERATURE_WARNING 0 "no" 1 "yes" ;
VAL_ 450 AMBIENT_OVERTEMPERATURE 0 "no" 1 "yes" ;
VAL_ 450 AMBIENT_TEMPSENSOR_ERROR 0 "no" 1 "yes" ;
VAL_ 450 POWERMODULE_CLAMPING_TIMEOUT 0 "no" 1 "yes" ;
VAL_ 450 DCBUS_RIPPLE_TO_HIGH 0 "no" 1 "yes" ;
VAL_ 450 MOTOR_I2XT_WARNING 0 "no" 1 "yes" ;
VAL_ 450 MOTOR_I2XT_ERROR 0 "no" 1 "yes" ;
VAL_ 450 MOTOR_FIELDWEAKENING_ERROR 0 "no" 1 "yes" ;
VAL_ 450 INVALID_PARAMETER_COMBINATION 0 "no" 1 "yes" ;
VAL_ 450 PLUG_COVER_SENSOR_SIGNAL_LOW 0 "no" 1 "yes" ;
VAL_ 450 MOTOR_CONNECTION_TEST_FAILED 0 "no" 1 "yes" ;
VAL_ 450 POWERMODULE_IXT_WARNING 0 "no" 1 "yes" ;
VAL_ 450 ISOLATION_FAULT 0 "no" 1 "yes" ;
VAL_ 451 Inverter_A_Statusword_3 0 "NotReadyToSwitchOn" 64 "SwitchOnDisabled" 80 "SwitchOnDisabled" 96 "SwitchOnDisabled" 112 "SwitchOnDisabled" 33 "ReadyToSwitchOn" 49 "ReadyToSwitchOn" 35 "SwitchedOn" 51 "SwitchedOn" 39 "OperationEnabled" 55 "OperationEnabled" 7 "QuickStopActive" 23 "QuickStopActive" 15 "FaultReactionActive" 31 "FaultReactionActive" 47 "FaultReactionActive" 63 "FaultReactionActive" 8 "Fault" 24 "Fault" 40 "Fault" 56 "Fault" ;
VAL_ 451 EVENTBUFFER_NEW_EVENT 0 "no" 1 "yes" ;
VAL_ 451 EVENTBUFFER_OVERFLOW 0 "no" 1 "yes" ;
VAL_ 451 POWERMODULE_TRIPZONE_OVERCURRE 0 "no" 1 "yes" ;
VAL_ 451 POWERMODULE_CURRENT_OFFSET_INI 0 "no" 1 "yes" ;
VAL_ 451 POWERMODULE_TEMPSENSOR_ERROR 0 "no" 1 "yes" ;
VAL_ 451 POWERMODULE_TEMPERATURE_WARNIN 0 "no" 1 "yes" ;
VAL_ 451 POWERMODULE_OVERTEMPERATURE 0 "no" 1 "yes" ;
VAL_ 451 POWERMODULE_IXT_FAULT 0 "no" 1 "yes" ;
VAL_ 451 POWERMODULE_SW_OVERCURRENT 0 "no" 1 "yes" ;
VAL_ 451 POWERMODULE_PATTERNDATA_INCONS 0 "no" 1 "yes" ;
VAL_ 451 DCBUS_TRIPZONE_OVERVOLTAGE 0 "no" 1 "yes" ;
VAL_ 451 DCBUS_SW_OVERVOLTAGE 0 "no" 1 "yes" ;
VAL_ 451 DCBUS_SW_UNDERVOLTAGE 0 "no" 1 "yes" ;
VAL_ 451 NEIGHBOUR_FAULT 0 "no" 1 "yes" ;
VAL_ 451 MOTOR_TEMPSENSOR_ERROR 0 "no" 1 "yes" ;
VAL_ 451 MOTOR_TEMPERATURE_WARNING 0 "no" 1 "yes" ;
VAL_ 451 MOTOR_OVERTEMPERATURE 0 "no" 1 "yes" ;
VAL_ 451 MOTOR_STATOR_FREQ_TO_HIGH 0 "no" 1 "yes" ;
VAL_ 451 SUPPLYVOLTAGE_ERROR 0 "no" 1 "yes" ;
VAL_ 451 RPDO_TIMEOUT 0 "no" 1 "yes" ;
VAL_ 451 NMT_NOT_OPERATIONAL 0 "no" 1 "yes" ;
VAL_ 451 TASKOVERRUN 0 "no" 1 "yes" ;
VAL_ 451 NETSYNC_ERROR 0 "no" 1 "yes" ;
VAL_ 451 POSDEVICE_SIGNAL_TO_LOW 0 "no" 1 "yes" ;
VAL_ 451 POSDEVICE_SIGNAL_TO_HIGH 0 "no" 1 "yes" ;
VAL_ 451 RESOLVER_CALIBRATION_FAILED 0 "no" 1 "yes" ;
VAL_ 451 SYSTEM_FAULT 0 "no" 1 "yes" ;
VAL_ 451 INTERLOCK_OPEN 0 "no" 1 "yes" ;
VAL_ 451 APPC_HAS_GATE_DRIVER_DISABLED 0 "no" 1 "yes" ;
VAL_ 451 MOTOR_STALL_ERROR 0 "no" 1 "yes" ;
VAL_ 451 AMBIENT_TEMPERATURE_WARNING 0 "no" 1 "yes" ;
VAL_ 451 AMBIENT_OVERTEMPERATURE 0 "no" 1 "yes" ;
VAL_ 451 AMBIENT_TEMPSENSOR_ERROR 0 "no" 1 "yes" ;
VAL_ 451 POWERMODULE_CLAMPING_TIMEOUT 0 "no" 1 "yes" ;
VAL_ 451 DCBUS_RIPPLE_TO_HIGH 0 "no" 1 "yes" ;
VAL_ 451 MOTOR_I2XT_WARNING 0 "no" 1 "yes" ;
VAL_ 451 MOTOR_I2XT_ERROR 0 "no" 1 "yes" ;
VAL_ 451 MOTOR_FIELDWEAKENING_ERROR 0 "no" 1 "yes" ;
VAL_ 451 INVALID_PARAMETER_COMBINATION 0 "no" 1 "yes" ;
VAL_ 451 PLUG_COVER_SENSOR_SIGNAL_LOW 0 "no" 1 "yes" ;
VAL_ 451 MOTOR_CONNECTION_TEST_FAILED 0 "no" 1 "yes" ;
VAL_ 451 POWERMODULE_IXT_WARNING 0 "no" 1 "yes" ;
VAL_ 451 ISOLATION_FAULT 0 "no" 1 "yes" ;
VAL_ 452 Inverter_A_Statusword_4 0 "NotReadyToSwitchOn" 64 "SwitchOnDisabled" 80 "SwitchOnDisabled" 96 "SwitchOnDisabled" 112 "SwitchOnDisabled" 33 "ReadyToSwitchOn" 49 "ReadyToSwitchOn" 35 "SwitchedOn" 51 "SwitchedOn" 39 "OperationEnabled" 55 "OperationEnabled" 7 "QuickStopActive" 23 "QuickStopActive" 15 "FaultReactionActive" 31 "FaultReactionActive" 47 "FaultReactionActive" 63 "FaultReactionActive" 8 "Fault" 24 "Fault" 40 "Fault" 56 "Fault" ;
VAL_ 452 EVENTBUFFER_NEW_EVENT 0 "no" 1 "yes" ;
VAL_ 452 EVENTBUFFER_OVERFLOW 0 "no" 1 "yes" ;
VAL_ 452 POWERMODULE_TRIPZONE_OVERCURRE 0 "no" 1 "yes" ;
VAL_ 452 POWERMODULE_CURRENT_OFFSET_INI 0 "no" 1 "yes" ;
VAL_ 452 POWERMODULE_TEMPSENSOR_ERROR 0 "no" 1 "yes" ;
VAL_ 452 POWERMODULE_TEMPERATURE_WARNIN 0 "no" 1 "yes" ;
VAL_ 452 POWERMODULE_OVERTEMPERATURE 0 "no" 1 "yes" ;
VAL_ 452 POWERMODULE_IXT_FAULT 0 "no" 1 "yes" ;
VAL_ 452 POWERMODULE_SW_OVERCURRENT 0 "no" 1 "yes" ;
VAL_ 452 POWERMODULE_PATTERNDATA_INCONS 0 "no" 1 "yes" ;
VAL_ 452 DCBUS_TRIPZONE_OVERVOLTAGE 0 "no" 1 "yes" ;
VAL_ 452 DCBUS_SW_OVERVOLTAGE 0 "no" 1 "yes" ;
VAL_ 452 DCBUS_SW_UNDERVOLTAGE 0 "no" 1 "yes" ;
VAL_ 452 NEIGHBOUR_FAULT 0 "no" 1 "yes" ;
VAL_ 452 MOTOR_TEMPSENSOR_ERROR 0 "no" 1 "yes" ;
VAL_ 452 MOTOR_TEMPERATURE_WARNING 0 "no" 1 "yes" ;
VAL_ 452 MOTOR_OVERTEMPERATURE 0 "no" 1 "yes" ;
VAL_ 452 MOTOR_STATOR_FREQ_TO_HIGH 0 "no" 1 "yes" ;
VAL_ 452 SUPPLYVOLTAGE_ERROR 0 "no" 1 "yes" ;
VAL_ 452 RPDO_TIMEOUT 0 "no" 1 "yes" ;
VAL_ 452 NMT_NOT_OPERATIONAL 0 "no" 1 "yes" ;
VAL_ 452 TASKOVERRUN 0 "no" 1 "yes" ;
VAL_ 452 NETSYNC_ERROR 0 "no" 1 "yes" ;
VAL_ 452 POSDEVICE_SIGNAL_TO_LOW 0 "no" 1 "yes" ;
VAL_ 452 POSDEVICE_SIGNAL_TO_HIGH 0 "no" 1 "yes" ;
VAL_ 452 RESOLVER_CALIBRATION_FAILED 0 "no" 1 "yes" ;
VAL_ 452 SYSTEM_FAULT 0 "no" 1 "yes" ;
VAL_ 452 INTERLOCK_OPEN 0 "no" 1 "yes" ;
VAL_ 452 APPC_HAS_GATE_DRIVER_DISABLED 0 "no" 1 "yes" ;
VAL_ 452 MOTOR_STALL_ERROR 0 "no" 1 "yes" ;
VAL_ 452 AMBIENT_TEMPERATURE_WARNING 0 "no" 1 "yes" ;
VAL_ 452 AMBIENT_OVERTEMPERATURE 0 "no" 1 "yes" ;
VAL_ 452 AMBIENT_TEMPSENSOR_ERROR 0 "no" 1 "yes" ;
VAL_ 452 POWERMODULE_CLAMPING_TIMEOUT 0 "no" 1 "yes" ;
VAL_ 452 DCBUS_RIPPLE_TO_HIGH 0 "no" 1 "yes" ;
VAL_ 452 MOTOR_I2XT_WARNING 0 "no" 1 "yes" ;
VAL_ 452 MOTOR_I2XT_ERROR 0 "no" 1 "yes" ;
VAL_ 452 MOTOR_FIELDWEAKENING_ERROR 0 "no" 1 "yes" ;
VAL_ 452 INVALID_PARAMETER_COMBINATION 0 "no" 1 "yes" ;
VAL_ 452 PLUG_COVER_SENSOR_SIGNAL_LOW 0 "no" 1 "yes" ;
VAL_ 452 MOTOR_CONNECTION_TEST_FAILED 0 "no" 1 "yes" ;
VAL_ 452 POWERMODULE_IXT_WARNING 0 "no" 1 "yes" ;
VAL_ 452 ISOLATION_FAULT 0 "no" 1 "yes" ;
VAL_ 453 Inverter_A_Statusword_5 0 "NotReadyToSwitchOn" 64 "SwitchOnDisabled" 80 "SwitchOnDisabled" 96 "SwitchOnDisabled" 112 "SwitchOnDisabled" 33 "ReadyToSwitchOn" 49 "ReadyToSwitchOn" 35 "SwitchedOn" 51 "SwitchedOn" 39 "OperationEnabled" 55 "OperationEnabled" 7 "QuickStopActive" 23 "QuickStopActive" 15 "FaultReactionActive" 31 "FaultReactionActive" 47 "FaultReactionActive" 63 "FaultReactionActive" 8 "Fault" 24 "Fault" 40 "Fault" 56 "Fault" ;
VAL_ 453 EVENTBUFFER_NEW_EVENT 0 "no" 1 "yes" ;
VAL_ 453 EVENTBUFFER_OVERFLOW 0 "no" 1 "yes" ;
VAL_ 453 POWERMODULE_TRIPZONE_OVERCURRE 0 "no" 1 "yes" ;
VAL_ 453 POWERMODULE_CURRENT_OFFSET_INI 0 "no" 1 "yes" ;
VAL_ 453 POWERMODULE_TEMPSENSOR_ERROR 0 "no" 1 "yes" ;
VAL_ 453 POWERMODULE_TEMPERATURE_WARNIN 0 "no" 1 "yes" ;
VAL_ 453 POWERMODULE_OVERTEMPERATURE 0 "no" 1 "yes" ;
VAL_ 453 POWERMODULE_IXT_FAULT 0 "no" 1 "yes" ;
VAL_ 453 POWERMODULE_SW_OVERCURRENT 0 "no" 1 "yes" ;
VAL_ 453 POWERMODULE_PATTERNDATA_INCONS 0 "no" 1 "yes" ;
VAL_ 453 DCBUS_TRIPZONE_OVERVOLTAGE 0 "no" 1 "yes" ;
VAL_ 453 DCBUS_SW_OVERVOLTAGE 0 "no" 1 "yes" ;
VAL_ 453 DCBUS_SW_UNDERVOLTAGE 0 "no" 1 "yes" ;
VAL_ 453 NEIGHBOUR_FAULT 0 "no" 1 "yes" ;
VAL_ 453 MOTOR_TEMPSENSOR_ERROR 0 "no" 1 "yes" ;
VAL_ 453 MOTOR_TEMPERATURE_WARNING 0 "no" 1 "yes" ;
VAL_ 453 MOTOR_OVERTEMPERATURE 0 "no" 1 "yes" ;
VAL_ 453 MOTOR_STATOR_FREQ_TO_HIGH 0 "no" 1 "yes" ;
VAL_ 453 SUPPLYVOLTAGE_ERROR 0 "no" 1 "yes" ;
VAL_ 453 RPDO_TIMEOUT 0 "no" 1 "yes" ;
VAL_ 453 NMT_NOT_OPERATIONAL 0 "no" 1 "yes" ;
VAL_ 453 TASKOVERRUN 0 "no" 1 "yes" ;
VAL_ 453 NETSYNC_ERROR 0 "no" 1 "yes" ;
VAL_ 453 POSDEVICE_SIGNAL_TO_LOW 0 "no" 1 "yes" ;
VAL_ 453 POSDEVICE_SIGNAL_TO_HIGH 0 "no" 1 "yes" ;
VAL_ 453 RESOLVER_CALIBRATION_FAILED 0 "no" 1 "yes" ;
VAL_ 453 SYSTEM_FAULT 0 "no" 1 "yes" ;
VAL_ 453 INTERLOCK_OPEN 0 "no" 1 "yes" ;
VAL_ 453 APPC_HAS_GATE_DRIVER_DISABLED 0 "no" 1 "yes" ;
VAL_ 453 MOTOR_STALL_ERROR 0 "no" 1 "yes" ;
VAL_ 453 AMBIENT_TEMPERATURE_WARNING 0 "no" 1 "yes" ;
VAL_ 453 AMBIENT_OVERTEMPERATURE 0 "no" 1 "yes" ;
VAL_ 453 AMBIENT_TEMPSENSOR_ERROR 0 "no" 1 "yes" ;
VAL_ 453 POWERMODULE_CLAMPING_TIMEOUT 0 "no" 1 "yes" ;
VAL_ 453 DCBUS_RIPPLE_TO_HIGH 0 "no" 1 "yes" ;
VAL_ 453 MOTOR_I2XT_WARNING 0 "no" 1 "yes" ;
VAL_ 453 MOTOR_I2XT_ERROR 0 "no" 1 "yes" ;
VAL_ 453 MOTOR_FIELDWEAKENING_ERROR 0 "no" 1 "yes" ;
VAL_ 453 INVALID_PARAMETER_COMBINATION 0 "no" 1 "yes" ;
VAL_ 453 PLUG_COVER_SENSOR_SIGNAL_LOW 0 "no" 1 "yes" ;
VAL_ 453 MOTOR_CONNECTION_TEST_FAILED 0 "no" 1 "yes" ;
VAL_ 453 POWERMODULE_IXT_WARNING 0 "no" 1 "yes" ;
VAL_ 453 ISOLATION_FAULT 0 "no" 1 "yes" ;
VAL_ 454 Inverter_A_Statusword_6 0 "NotReadyToSwitchOn" 64 "SwitchOnDisabled" 80 "SwitchOnDisabled" 96 "SwitchOnDisabled" 112 "SwitchOnDisabled" 33 "ReadyToSwitchOn" 49 "ReadyToSwitchOn" 35 "SwitchedOn" 51 "SwitchedOn" 39 "OperationEnabled" 55 "OperationEnabled" 7 "QuickStopActive" 23 "QuickStopActive" 15 "FaultReactionActive" 31 "FaultReactionActive" 47 "FaultReactionActive" 63 "FaultReactionActive" 8 "Fault" 24 "Fault" 40 "Fault" 56 "Fault" ;
VAL_ 454 EVENTBUFFER_NEW_EVENT 0 "no" 1 "yes" ;
VAL_ 454 EVENTBUFFER_OVERFLOW 0 "no" 1 "yes" ;
VAL_ 454 POWERMODULE_TRIPZONE_OVERCURRE 0 "no" 1 "yes" ;
VAL_ 454 POWERMODULE_CURRENT_OFFSET_INI 0 "no" 1 "yes" ;
VAL_ 454 POWERMODULE_TEMPSENSOR_ERROR 0 "no" 1 "yes" ;
VAL_ 454 POWERMODULE_TEMPERATURE_WARNIN 0 "no" 1 "yes" ;
VAL_ 454 POWERMODULE_OVERTEMPERATURE 0 "no" 1 "yes" ;
VAL_ 454 POWERMODULE_IXT_FAULT 0 "no" 1 "yes" ;
VAL_ 454 POWERMODULE_SW_OVERCURRENT 0 "no" 1 "yes" ;
VAL_ 454 POWERMODULE_PATTERNDATA_INCONS 0 "no" 1 "yes" ;
VAL_ 454 DCBUS_TRIPZONE_OVERVOLTAGE 0 "no" 1 "yes" ;
VAL_ 454 DCBUS_SW_OVERVOLTAGE 0 "no" 1 "yes" ;
VAL_ 454 DCBUS_SW_UNDERVOLTAGE 0 "no" 1 "yes" ;
VAL_ 454 NEIGHBOUR_FAULT 0 "no" 1 "yes" ;
VAL_ 454 MOTOR_TEMPSENSOR_ERROR 0 "no" 1 "yes" ;
VAL_ 454 MOTOR_TEMPERATURE_WARNING 0 "no" 1 "yes" ;
VAL_ 454 MOTOR_OVERTEMPERATURE 0 "no" 1 "yes" ;
VAL_ 454 MOTOR_STATOR_FREQ_TO_HIGH 0 "no" 1 "yes" ;
VAL_ 454 SUPPLYVOLTAGE_ERROR 0 "no" 1 "yes" ;
VAL_ 454 RPDO_TIMEOUT 0 "no" 1 "yes" ;
VAL_ 454 NMT_NOT_OPERATIONAL 0 "no" 1 "yes" ;
VAL_ 454 TASKOVERRUN 0 "no" 1 "yes" ;
VAL_ 454 NETSYNC_ERROR 0 "no" 1 "yes" ;
VAL_ 454 POSDEVICE_SIGNAL_TO_LOW 0 "no" 1 "yes" ;
VAL_ 454 POSDEVICE_SIGNAL_TO_HIGH 0 "no" 1 "yes" ;
VAL_ 454 RESOLVER_CALIBRATION_FAILED 0 "no" 1 "yes" ;
VAL_ 454 SYSTEM_FAULT 0 "no" 1 "yes" ;
VAL_ 454 INTERLOCK_OPEN 0 "no" 1 "yes" ;
VAL_ 454 APPC_HAS_GATE_DRIVER_DISABLED 0 "no" 1 "yes" ;
VAL_ 454 MOTOR_STALL_ERROR 0 "no" 1 "yes" ;
VAL_ 454 AMBIENT_TEMPERATURE_WARNING 0 "no" 1 "yes" ;
VAL_ 454 AMBIENT_OVERTEMPERATURE 0 "no" 1 "yes" ;
VAL_ 454 AMBIENT_TEMPSENSOR_ERROR 0 "no" 1 "yes" ;
VAL_ 454 POWERMODULE_CLAMPING_TIMEOUT 0 "no" 1 "yes" ;
VAL_ 454 DCBUS_RIPPLE_TO_HIGH 0 "no" 1 "yes" ;
VAL_ 454 MOTOR_I2XT_WARNING 0 "no" 1 "yes" ;
VAL_ 454 MOTOR_I2XT_ERROR 0 "no" 1 "yes" ;
VAL_ 454 MOTOR_FIELDWEAKENING_ERROR 0 "no" 1 "yes" ;
VAL_ 454 INVALID_PARAMETER_COMBINATION 0 "no" 1 "yes" ;
VAL_ 454 PLUG_COVER_SENSOR_SIGNAL_LOW 0 "no" 1 "yes" ;
VAL_ 454 MOTOR_CONNECTION_TEST_FAILED 0 "no" 1 "yes" ;
VAL_ 454 POWERMODULE_IXT_WARNING 0 "no" 1 "yes" ;
VAL_ 454 ISOLATION_FAULT 0 "no" 1 "yes" ;
VAL_ 455 Inverter_A_Statusword_7 0 "NotReadyToSwitchOn" 64 "SwitchOnDisabled" 80 "SwitchOnDisabled" 96 "SwitchOnDisabled" 112 "SwitchOnDisabled" 33 "ReadyToSwitchOn" 49 "ReadyToSwitchOn" 35 "SwitchedOn" 51 "SwitchedOn" 39 "OperationEnabled" 55 "OperationEnabled" 7 "QuickStopActive" 23 "QuickStopActive" 15 "FaultReactionActive" 31 "FaultReactionActive" 47 "FaultReactionActive" 63 "FaultReactionActive" 8 "Fault" 24 "Fault" 40 "Fault" 56 "Fault" ;
VAL_ 455 EVENTBUFFER_NEW_EVENT 0 "no" 1 "yes" ;
VAL_ 455 EVENTBUFFER_OVERFLOW 0 "no" 1 "yes" ;
VAL_ 455 POWERMODULE_TRIPZONE_OVERCURRE 0 "no" 1 "yes" ;
VAL_ 455 POWERMODULE_CURRENT_OFFSET_INI 0 "no" 1 "yes" ;
VAL_ 455 POWERMODULE_TEMPSENSOR_ERROR 0 "no" 1 "yes" ;
VAL_ 455 POWERMODULE_TEMPERATURE_WARNIN 0 "no" 1 "yes" ;
VAL_ 455 POWERMODULE_OVERTEMPERATURE 0 "no" 1 "yes" ;
VAL_ 455 POWERMODULE_IXT_FAULT 0 "no" 1 "yes" ;
VAL_ 455 POWERMODULE_SW_OVERCURRENT 0 "no" 1 "yes" ;
VAL_ 455 POWERMODULE_PATTERNDATA_INCONS 0 "no" 1 "yes" ;
VAL_ 455 DCBUS_TRIPZONE_OVERVOLTAGE 0 "no" 1 "yes" ;
VAL_ 455 DCBUS_SW_OVERVOLTAGE 0 "no" 1 "yes" ;
VAL_ 455 DCBUS_SW_UNDERVOLTAGE 0 "no" 1 "yes" ;
VAL_ 455 NEIGHBOUR_FAULT 0 "no" 1 "yes" ;
VAL_ 455 MOTOR_TEMPSENSOR_ERROR 0 "no" 1 "yes" ;
VAL_ 455 MOTOR_TEMPERATURE_WARNING 0 "no" 1 "yes" ;
VAL_ 455 MOTOR_OVERTEMPERATURE 0 "no" 1 "yes" ;
VAL_ 455 MOTOR_STATOR_FREQ_TO_HIGH 0 "no" 1 "yes" ;
VAL_ 455 SUPPLYVOLTAGE_ERROR 0 "no" 1 "yes" ;
VAL_ 455 RPDO_TIMEOUT 0 "no" 1 "yes" ;
VAL_ 455 NMT_NOT_OPERATIONAL 0 "no" 1 "yes" ;
VAL_ 455 TASKOVERRUN 0 "no" 1 "yes" ;
VAL_ 455 NETSYNC_ERROR 0 "no" 1 "yes" ;
VAL_ 455 POSDEVICE_SIGNAL_TO_LOW 0 "no" 1 "yes" ;
VAL_ 455 POSDEVICE_SIGNAL_TO_HIGH 0 "no" 1 "yes" ;
VAL_ 455 RESOLVER_CALIBRATION_FAILED 0 "no" 1 "yes" ;
VAL_ 455 SYSTEM_FAULT 0 "no" 1 "yes" ;
VAL_ 455 INTERLOCK_OPEN 0 "no" 1 "yes" ;
VAL_ 455 APPC_HAS_GATE_DRIVER_DISABLED 0 "no" 1 "yes" ;
VAL_ 455 MOTOR_STALL_ERROR 0 "no" 1 "yes" ;
VAL_ 455 AMBIENT_TEMPERATURE_WARNING 0 "no" 1 "yes" ;
VAL_ 455 AMBIENT_OVERTEMPERATURE 0 "no" 1 "yes" ;
VAL_ 455 AMBIENT_TEMPSENSOR_ERROR 0 "no" 1 "yes" ;
VAL_ 455 POWERMODULE_CLAMPING_TIMEOUT 0 "no" 1 "yes" ;
VAL_ 455 DCBUS_RIPPLE_TO_HIGH 0 "no" 1 "yes" ;
VAL_ 455 MOTOR_I2XT_WARNING 0 "no" 1 "yes" ;
VAL_ 455 MOTOR_I2XT_ERROR 0 "no" 1 "yes" ;
VAL_ 455 MOTOR_FIELDWEAKENING_ERROR 0 "no" 1 "yes" ;
VAL_ 455 INVALID_PARAMETER_COMBINATION 0 "no" 1 "yes" ;
VAL_ 455 PLUG_COVER_SENSOR_SIGNAL_LOW 0 "no" 1 "yes" ;
VAL_ 455 MOTOR_CONNECTION_TEST_FAILED 0 "no" 1 "yes" ;
VAL_ 455 POWERMODULE_IXT_WARNING 0 "no" 1 "yes" ;
VAL_ 455 ISOLATION_FAULT 0 "no" 1 "yes" ;
VAL_ 456 Inverter_A_Statusword_8 0 "NotReadyToSwitchOn" 64 "SwitchOnDisabled" 80 "SwitchOnDisabled" 96 "SwitchOnDisabled" 112 "SwitchOnDisabled" 33 "ReadyToSwitchOn" 49 "ReadyToSwitchOn" 35 "SwitchedOn" 51 "SwitchedOn" 39 "OperationEnabled" 55 "OperationEnabled" 7 "QuickStopActive" 23 "QuickStopActive" 15 "FaultReactionActive" 31 "FaultReactionActive" 47 "FaultReactionActive" 63 "FaultReactionActive" 8 "Fault" 24 "Fault" 40 "Fault" 56 "Fault" ;
VAL_ 456 EVENTBUFFER_NEW_EVENT 0 "no" 1 "yes" ;
VAL_ 456 EVENTBUFFER_OVERFLOW 0 "no" 1 "yes" ;
VAL_ 456 POWERMODULE_TRIPZONE_OVERCURRE 0 "no" 1 "yes" ;
VAL_ 456 POWERMODULE_CURRENT_OFFSET_INI 0 "no" 1 "yes" ;
VAL_ 456 POWERMODULE_TEMPSENSOR_ERROR 0 "no" 1 "yes" ;
VAL_ 456 POWERMODULE_TEMPERATURE_WARNIN 0 "no" 1 "yes" ;
VAL_ 456 POWERMODULE_OVERTEMPERATURE 0 "no" 1 "yes" ;
VAL_ 456 POWERMODULE_IXT_FAULT 0 "no" 1 "yes" ;
VAL_ 456 POWERMODULE_SW_OVERCURRENT 0 "no" 1 "yes" ;
VAL_ 456 POWERMODULE_PATTERNDATA_INCONS 0 "no" 1 "yes" ;
VAL_ 456 DCBUS_TRIPZONE_OVERVOLTAGE 0 "no" 1 "yes" ;
VAL_ 456 DCBUS_SW_OVERVOLTAGE 0 "no" 1 "yes" ;
VAL_ 456 DCBUS_SW_UNDERVOLTAGE 0 "no" 1 "yes" ;
VAL_ 456 NEIGHBOUR_FAULT 0 "no" 1 "yes" ;
VAL_ 456 MOTOR_TEMPSENSOR_ERROR 0 "no" 1 "yes" ;
VAL_ 456 MOTOR_TEMPERATURE_WARNING 0 "no" 1 "yes" ;
VAL_ 456 MOTOR_OVERTEMPERATURE 0 "no" 1 "yes" ;
VAL_ 456 MOTOR_STATOR_FREQ_TO_HIGH 0 "no" 1 "yes" ;
VAL_ 456 SUPPLYVOLTAGE_ERROR 0 "no" 1 "yes" ;
VAL_ 456 RPDO_TIMEOUT 0 "no" 1 "yes" ;
VAL_ 456 NMT_NOT_OPERATIONAL 0 "no" 1 "yes" ;
VAL_ 456 TASKOVERRUN 0 "no" 1 "yes" ;
VAL_ 456 NETSYNC_ERROR 0 "no" 1 "yes" ;
VAL_ 456 POSDEVICE_SIGNAL_TO_LOW 0 "no" 1 "yes" ;
VAL_ 456 POSDEVICE_SIGNAL_TO_HIGH 0 "no" 1 "yes" ;
VAL_ 456 RESOLVER_CALIBRATION_FAILED 0 "no" 1 "yes" ;
VAL_ 456 SYSTEM_FAULT 0 "no" 1 "yes" ;
VAL_ 456 INTERLOCK_OPEN 0 "no" 1 "yes" ;
VAL_ 456 APPC_HAS_GATE_DRIVER_DISABLED 0 "no" 1 "yes" ;
VAL_ 456 MOTOR_STALL_ERROR 0 "no" 1 "yes" ;
VAL_ 456 AMBIENT_TEMPERATURE_WARNING 0 "no" 1 "yes" ;
VAL_ 456 AMBIENT_OVERTEMPERATURE 0 "no" 1 "yes" ;
VAL_ 456 AMBIENT_TEMPSENSOR_ERROR 0 "no" 1 "yes" ;
VAL_ 456 POWERMODULE_CLAMPING_TIMEOUT 0 "no" 1 "yes" ;
VAL_ 456 DCBUS_RIPPLE_TO_HIGH 0 "no" 1 "yes" ;
VAL_ 456 MOTOR_I2XT_WARNING 0 "no" 1 "yes" ;
VAL_ 456 MOTOR_I2XT_ERROR 0 "no" 1 "yes" ;
VAL_ 456 MOTOR_FIELDWEAKENING_ERROR 0 "no" 1 "yes" ;
VAL_ 456 INVALID_PARAMETER_COMBINATION 0 "no" 1 "yes" ;
VAL_ 456 PLUG_COVER_SENSOR_SIGNAL_LOW 0 "no" 1 "yes" ;
VAL_ 456 MOTOR_CONNECTION_TEST_FAILED 0 "no" 1 "yes" ;
VAL_ 456 POWERMODULE_IXT_WARNING 0 "no" 1 "yes" ;
VAL_ 456 ISOLATION_FAULT 0 "no" 1 "yes" ;
VAL_ 457 Inverter_A_Statusword_9 0 "NotReadyToSwitchOn" 64 "SwitchOnDisabled" 80 "SwitchOnDisabled" 96 "SwitchOnDisabled" 112 "SwitchOnDisabled" 33 "ReadyToSwitchOn" 49 "ReadyToSwitchOn" 35 "SwitchedOn" 51 "SwitchedOn" 39 "OperationEnabled" 55 "OperationEnabled" 7 "QuickStopActive" 23 "QuickStopActive" 15 "FaultReactionActive" 31 "FaultReactionActive" 47 "FaultReactionActive" 63 "FaultReactionActive" 8 "Fault" 24 "Fault" 40 "Fault" 56 "Fault" ;
VAL_ 457 EVENTBUFFER_NEW_EVENT 0 "no" 1 "yes" ;
VAL_ 457 EVENTBUFFER_OVERFLOW 0 "no" 1 "yes" ;
VAL_ 457 POWERMODULE_TRIPZONE_OVERCURRE 0 "no" 1 "yes" ;
VAL_ 457 POWERMODULE_CURRENT_OFFSET_INI 0 "no" 1 "yes" ;
VAL_ 457 POWERMODULE_TEMPSENSOR_ERROR 0 "no" 1 "yes" ;
VAL_ 457 POWERMODULE_TEMPERATURE_WARNIN 0 "no" 1 "yes" ;
VAL_ 457 POWERMODULE_OVERTEMPERATURE 0 "no" 1 "yes" ;
VAL_ 457 POWERMODULE_IXT_FAULT 0 "no" 1 "yes" ;
VAL_ 457 POWERMODULE_SW_OVERCURRENT 0 "no" 1 "yes" ;
VAL_ 457 POWERMODULE_PATTERNDATA_INCONS 0 "no" 1 "yes" ;
VAL_ 457 DCBUS_TRIPZONE_OVERVOLTAGE 0 "no" 1 "yes" ;
VAL_ 457 DCBUS_SW_OVERVOLTAGE 0 "no" 1 "yes" ;
VAL_ 457 DCBUS_SW_UNDERVOLTAGE 0 "no" 1 "yes" ;
VAL_ 457 NEIGHBOUR_FAULT 0 "no" 1 "yes" ;
VAL_ 457 MOTOR_TEMPSENSOR_ERROR 0 "no" 1 "yes" ;
VAL_ 457 MOTOR_TEMPERATURE_WARNING 0 "no" 1 "yes" ;
VAL_ 457 MOTOR_OVERTEMPERATURE 0 "no" 1 "yes" ;
VAL_ 457 MOTOR_STATOR_FREQ_TO_HIGH 0 "no" 1 "yes" ;
VAL_ 457 SUPPLYVOLTAGE_ERROR 0 "no" 1 "yes" ;
VAL_ 457 RPDO_TIMEOUT 0 "no" 1 "yes" ;
VAL_ 457 NMT_NOT_OPERATIONAL 0 "no" 1 "yes" ;
VAL_ 457 TASKOVERRUN 0 "no" 1 "yes" ;
VAL_ 457 NETSYNC_ERROR 0 "no" 1 "yes" ;
VAL_ 457 POSDEVICE_SIGNAL_TO_LOW 0 "no" 1 "yes" ;
VAL_ 457 POSDEVICE_SIGNAL_TO_HIGH 0 "no" 1 "yes" ;
VAL_ 457 RESOLVER_CALIBRATION_FAILED 0 "no" 1 "yes" ;
VAL_ 457 SYSTEM_FAULT 0 "no" 1 "yes" ;
VAL_ 457 INTERLOCK_OPEN 0 "no" 1 "yes" ;
VAL_ 457 APPC_HAS_GATE_DRIVER_DISABLED 0 "no" 1 "yes" ;
VAL_ 457 MOTOR_STALL_ERROR 0 "no" 1 "yes" ;
VAL_ 457 AMBIENT_TEMPERATURE_WARNING 0 "no" 1 "yes" ;
VAL_ 457 AMBIENT_OVERTEMPERATURE 0 "no" 1 "yes" ;
VAL_ 457 AMBIENT_TEMPSENSOR_ERROR 0 "no" 1 "yes" ;
VAL_ 457 POWERMODULE_CLAMPING_TIMEOUT 0 "no" 1 "yes" ;
VAL_ 457 DCBUS_RIPPLE_TO_HIGH 0 "no" 1 "yes" ;
VAL_ 457 MOTOR_I2XT_WARNING 0 "no" 1 "yes" ;
VAL_ 457 MOTOR_I2XT_ERROR 0 "no" 1 "yes" ;
VAL_ 457 MOTOR_FIELDWEAKENING_ERROR 0 "no" 1 "yes" ;
VAL_ 457 INVALID_PARAMETER_COMBINATION 0 "no" 1 "yes" ;
VAL_ 457 PLUG_COVER_SENSOR_SIGNAL_LOW 0 "no" 1 "yes" ;
VAL_ 457 MOTOR_CONNECTION_TEST_FAILED 0 "no" 1 "yes" ;
VAL_ 457 POWERMODULE_IXT_WARNING 0 "no" 1 "yes" ;
VAL_ 457 ISOLATION_FAULT 0 "no" 1 "yes" ;
VAL_ 458 Inverter_A_Statusword_10 0 "NotReadyToSwitchOn" 64 "SwitchOnDisabled" 80 "SwitchOnDisabled" 96 "SwitchOnDisabled" 112 "SwitchOnDisabled" 33 "ReadyToSwitchOn" 49 "ReadyToSwitchOn" 35 "SwitchedOn" 51 "SwitchedOn" 39 "OperationEnabled" 55 "OperationEnabled" 7 "QuickStopActive" 23 "QuickStopActive" 15 "FaultReactionActive" 31 "FaultReactionActive" 47 "FaultReactionActive" 63 "FaultReactionActive" 8 "Fault" 24 "Fault" 40 "Fault" 56 "Fault" ;
VAL_ 458 EVENTBUFFER_NEW_EVENT 0 "no" 1 "yes" ;
VAL_ 458 EVENTBUFFER_OVERFLOW 0 "no" 1 "yes" ;
VAL_ 458 POWERMODULE_TRIPZONE_OVERCURRE 0 "no" 1 "yes" ;
VAL_ 458 POWERMODULE_CURRENT_OFFSET_INI 0 "no" 1 "yes" ;
VAL_ 458 POWERMODULE_TEMPSENSOR_ERROR 0 "no" 1 "yes" ;
VAL_ 458 POWERMODULE_TEMPERATURE_WARNIN 0 "no" 1 "yes" ;
VAL_ 458 POWERMODULE_OVERTEMPERATURE 0 "no" 1 "yes" ;
VAL_ 458 POWERMODULE_IXT_FAULT 0 "no" 1 "yes" ;
VAL_ 458 POWERMODULE_SW_OVERCURRENT 0 "no" 1 "yes" ;
VAL_ 458 POWERMODULE_PATTERNDATA_INCONS 0 "no" 1 "yes" ;
VAL_ 458 DCBUS_TRIPZONE_OVERVOLTAGE 0 "no" 1 "yes" ;
VAL_ 458 DCBUS_SW_OVERVOLTAGE 0 "no" 1 "yes" ;
VAL_ 458 DCBUS_SW_UNDERVOLTAGE 0 "no" 1 "yes" ;
VAL_ 458 NEIGHBOUR_FAULT 0 "no" 1 "yes" ;
VAL_ 458 MOTOR_TEMPSENSOR_ERROR 0 "no" 1 "yes" ;
VAL_ 458 MOTOR_TEMPERATURE_WARNING 0 "no" 1 "yes" ;
VAL_ 458 MOTOR_OVERTEMPERATURE 0 "no" 1 "yes" ;
VAL_ 458 MOTOR_STATOR_FREQ_TO_HIGH 0 "no" 1 "yes" ;
VAL_ 458 SUPPLYVOLTAGE_ERROR 0 "no" 1 "yes" ;
VAL_ 458 RPDO_TIMEOUT 0 "no" 1 "yes" ;
VAL_ 458 NMT_NOT_OPERATIONAL 0 "no" 1 "yes" ;
VAL_ 458 TASKOVERRUN 0 "no" 1 "yes" ;
VAL_ 458 NETSYNC_ERROR 0 "no" 1 "yes" ;
VAL_ 458 POSDEVICE_SIGNAL_TO_LOW 0 "no" 1 "yes" ;
VAL_ 458 POSDEVICE_SIGNAL_TO_HIGH 0 "no" 1 "yes" ;
VAL_ 458 RESOLVER_CALIBRATION_FAILED 0 "no" 1 "yes" ;
VAL_ 458 SYSTEM_FAULT 0 "no" 1 "yes" ;
VAL_ 458 INTERLOCK_OPEN 0 "no" 1 "yes" ;
VAL_ 458 APPC_HAS_GATE_DRIVER_DISABLED 0 "no" 1 "yes" ;
VAL_ 458 MOTOR_STALL_ERROR 0 "no" 1 "yes" ;
VAL_ 458 AMBIENT_TEMPERATURE_WARNING 0 "no" 1 "yes" ;
VAL_ 458 AMBIENT_OVERTEMPERATURE 0 "no" 1 "yes" ;
VAL_ 458 AMBIENT_TEMPSENSOR_ERROR 0 "no" 1 "yes" ;
VAL_ 458 POWERMODULE_CLAMPING_TIMEOUT 0 "no" 1 "yes" ;
VAL_ 458 DCBUS_RIPPLE_TO_HIGH 0 "no" 1 "yes" ;
VAL_ 458 MOTOR_I2XT_WARNING 0 "no" 1 "yes" ;
VAL_ 458 MOTOR_I2XT_ERROR 0 "no" 1 "yes" ;
VAL_ 458 MOTOR_FIELDWEAKENING_ERROR 0 "no" 1 "yes" ;
VAL_ 458 INVALID_PARAMETER_COMBINATION 0 "no" 1 "yes" ;
VAL_ 458 PLUG_COVER_SENSOR_SIGNAL_LOW 0 "no" 1 "yes" ;
VAL_ 458 MOTOR_CONNECTION_TEST_FAILED 0 "no" 1 "yes" ;
VAL_ 458 POWERMODULE_IXT_WARNING 0 "no" 1 "yes" ;
VAL_ 458 ISOLATION_FAULT 0 "no" 1 "yes" ;
VAL_ 459 Inverter_A_Statusword_11 0 "NotReadyToSwitchOn" 64 "SwitchOnDisabled" 80 "SwitchOnDisabled" 96 "SwitchOnDisabled" 112 "SwitchOnDisabled" 33 "ReadyToSwitchOn" 49 "ReadyToSwitchOn" 35 "SwitchedOn" 51 "SwitchedOn" 39 "OperationEnabled" 55 "OperationEnabled" 7 "QuickStopActive" 23 "QuickStopActive" 15 "FaultReactionActive" 31 "FaultReactionActive" 47 "FaultReactionActive" 63 "FaultReactionActive" 8 "Fault" 24 "Fault" 40 "Fault" 56 "Fault" ;
VAL_ 459 EVENTBUFFER_NEW_EVENT 0 "no" 1 "yes" ;
VAL_ 459 EVENTBUFFER_OVERFLOW 0 "no" 1 "yes" ;
VAL_ 459 POWERMODULE_TRIPZONE_OVERCURRE 0 "no" 1 "yes" ;
VAL_ 459 POWERMODULE_CURRENT_OFFSET_INI 0 "no" 1 "yes" ;
VAL_ 459 POWERMODULE_TEMPSENSOR_ERROR 0 "no" 1 "yes" ;
VAL_ 459 POWERMODULE_TEMPERATURE_WARNIN 0 "no" 1 "yes" ;
VAL_ 459 POWERMODULE_OVERTEMPERATURE 0 "no" 1 "yes" ;
VAL_ 459 POWERMODULE_IXT_FAULT 0 "no" 1 "yes" ;
VAL_ 459 POWERMODULE_SW_OVERCURRENT 0 "no" 1 "yes" ;
VAL_ 459 POWERMODULE_PATTERNDATA_INCONS 0 "no" 1 "yes" ;
VAL_ 459 DCBUS_TRIPZONE_OVERVOLTAGE 0 "no" 1 "yes" ;
VAL_ 459 DCBUS_SW_OVERVOLTAGE 0 "no" 1 "yes" ;
VAL_ 459 DCBUS_SW_UNDERVOLTAGE 0 "no" 1 "yes" ;
VAL_ 459 NEIGHBOUR_FAULT 0 "no" 1 "yes" ;
VAL_ 459 MOTOR_TEMPSENSOR_ERROR 0 "no" 1 "yes" ;
VAL_ 459 MOTOR_TEMPERATURE_WARNING 0 "no" 1 "yes" ;
VAL_ 459 MOTOR_OVERTEMPERATURE 0 "no" 1 "yes" ;
VAL_ 459 MOTOR_STATOR_FREQ_TO_HIGH 0 "no" 1 "yes" ;
VAL_ 459 SUPPLYVOLTAGE_ERROR 0 "no" 1 "yes" ;
VAL_ 459 RPDO_TIMEOUT 0 "no" 1 "yes" ;
VAL_ 459 NMT_NOT_OPERATIONAL 0 "no" 1 "yes" ;
VAL_ 459 TASKOVERRUN 0 "no" 1 "yes" ;
VAL_ 459 NETSYNC_ERROR 0 "no" 1 "yes" ;
VAL_ 459 POSDEVICE_SIGNAL_TO_LOW 0 "no" 1 "yes" ;
VAL_ 459 POSDEVICE_SIGNAL_TO_HIGH 0 "no" 1 "yes" ;
VAL_ 459 RESOLVER_CALIBRATION_FAILED 0 "no" 1 "yes" ;
VAL_ 459 SYSTEM_FAULT 0 "no" 1 "yes" ;
VAL_ 459 INTERLOCK_OPEN 0 "no" 1 "yes" ;
VAL_ 459 APPC_HAS_GATE_DRIVER_DISABLED 0 "no" 1 "yes" ;
VAL_ 459 MOTOR_STALL_ERROR 0 "no" 1 "yes" ;
VAL_ 459 AMBIENT_TEMPERATURE_WARNING 0 "no" 1 "yes" ;
VAL_ 459 AMBIENT_OVERTEMPERATURE 0 "no" 1 "yes" ;
VAL_ 459 AMBIENT_TEMPSENSOR_ERROR 0 "no" 1 "yes" ;
VAL_ 459 POWERMODULE_CLAMPING_TIMEOUT 0 "no" 1 "yes" ;
VAL_ 459 DCBUS_RIPPLE_TO_HIGH 0 "no" 1 "yes" ;
VAL_ 459 MOTOR_I2XT_WARNING 0 "no" 1 "yes" ;
VAL_ 459 MOTOR_I2XT_ERROR 0 "no" 1 "yes" ;
VAL_ 459 MOTOR_FIELDWEAKENING_ERROR 0 "no" 1 "yes" ;
VAL_ 459 INVALID_PARAMETER_COMBINATION 0 "no" 1 "yes" ;
VAL_ 459 PLUG_COVER_SENSOR_SIGNAL_LOW 0 "no" 1 "yes" ;
VAL_ 459 MOTOR_CONNECTION_TEST_FAILED 0 "no" 1 "yes" ;
VAL_ 459 POWERMODULE_IXT_WARNING 0 "no" 1 "yes" ;
VAL_ 459 ISOLATION_FAULT 0 "no" 1 "yes" ;
VAL_ 460 Inverter_A_Statusword_12 0 "NotReadyToSwitchOn" 64 "SwitchOnDisabled" 80 "SwitchOnDisabled" 96 "SwitchOnDisabled" 112 "SwitchOnDisabled" 33 "ReadyToSwitchOn" 49 "ReadyToSwitchOn" 35 "SwitchedOn" 51 "SwitchedOn" 39 "OperationEnabled" 55 "OperationEnabled" 7 "QuickStopActive" 23 "QuickStopActive" 15 "FaultReactionActive" 31 "FaultReactionActive" 47 "FaultReactionActive" 63 "FaultReactionActive" 8 "Fault" 24 "Fault" 40 "Fault" 56 "Fault" ;
VAL_ 460 EVENTBUFFER_NEW_EVENT 0 "no" 1 "yes" ;
VAL_ 460 EVENTBUFFER_OVERFLOW 0 "no" 1 "yes" ;
VAL_ 460 POWERMODULE_TRIPZONE_OVERCURRE 0 "no" 1 "yes" ;
VAL_ 460 POWERMODULE_CURRENT_OFFSET_INI 0 "no" 1 "yes" ;
VAL_ 460 POWERMODULE_TEMPSENSOR_ERROR 0 "no" 1 "yes" ;
VAL_ 460 POWERMODULE_TEMPERATURE_WARNIN 0 "no" 1 "yes" ;
VAL_ 460 POWERMODULE_OVERTEMPERATURE 0 "no" 1 "yes" ;
VAL_ 460 POWERMODULE_IXT_FAULT 0 "no" 1 "yes" ;
VAL_ 460 POWERMODULE_SW_OVERCURRENT 0 "no" 1 "yes" ;
VAL_ 460 POWERMODULE_PATTERNDATA_INCONS 0 "no" 1 "yes" ;
VAL_ 460 DCBUS_TRIPZONE_OVERVOLTAGE 0 "no" 1 "yes" ;
VAL_ 460 DCBUS_SW_OVERVOLTAGE 0 "no" 1 "yes" ;
VAL_ 460 DCBUS_SW_UNDERVOLTAGE 0 "no" 1 "yes" ;
VAL_ 460 NEIGHBOUR_FAULT 0 "no" 1 "yes" ;
VAL_ 460 MOTOR_TEMPSENSOR_ERROR 0 "no" 1 "yes" ;
VAL_ 460 MOTOR_TEMPERATURE_WARNING 0 "no" 1 "yes" ;
VAL_ 460 MOTOR_OVERTEMPERATURE 0 "no" 1 "yes" ;
VAL_ 460 MOTOR_STATOR_FREQ_TO_HIGH 0 "no" 1 "yes" ;
VAL_ 460 SUPPLYVOLTAGE_ERROR 0 "no" 1 "yes" ;
VAL_ 460 RPDO_TIMEOUT 0 "no" 1 "yes" ;
VAL_ 460 NMT_NOT_OPERATIONAL 0 "no" 1 "yes" ;
VAL_ 460 TASKOVERRUN 0 "no" 1 "yes" ;
VAL_ 460 NETSYNC_ERROR 0 "no" 1 "yes" ;
VAL_ 460 POSDEVICE_SIGNAL_TO_LOW 0 "no" 1 "yes" ;
VAL_ 460 POSDEVICE_SIGNAL_TO_HIGH 0 "no" 1 "yes" ;
VAL_ 460 RESOLVER_CALIBRATION_FAILED 0 "no" 1 "yes" ;
VAL_ 460 SYSTEM_FAULT 0 "no" 1 "yes" ;
VAL_ 460 INTERLOCK_OPEN 0 "no" 1 "yes" ;
VAL_ 460 APPC_HAS_GATE_DRIVER_DISABLED 0 "no" 1 "yes" ;
VAL_ 460 MOTOR_STALL_ERROR 0 "no" 1 "yes" ;
VAL_ 460 AMBIENT_TEMPERATURE_WARNING 0 "no" 1 "yes" ;
VAL_ 460 AMBIENT_OVERTEMPERATURE 0 "no" 1 "yes" ;
VAL_ 460 AMBIENT_TEMPSENSOR_ERROR 0 "no" 1 "yes" ;
VAL_ 460 POWERMODULE_CLAMPING_TIMEOUT 0 "no" 1 "yes" ;
VAL_ 460 DCBUS_RIPPLE_TO_HIGH 0 "no" 1 "yes" ;
VAL_ 460 MOTOR_I2XT_WARNING 0 "no" 1 "yes" ;
VAL_ 460 MOTOR_I2XT_ERROR 0 "no" 1 "yes" ;
VAL_ 460 MOTOR_FIELDWEAKENING_ERROR 0 "no" 1 "yes" ;
VAL_ 460 INVALID_PARAMETER_COMBINATION 0 "no" 1 "yes" ;
VAL_ 460 PLUG_COVER_SENSOR_SIGNAL_LOW 0 "no" 1 "yes" ;
VAL_ 460 MOTOR_CONNECTION_TEST_FAILED 0 "no" 1 "yes" ;
VAL_ 460 POWERMODULE_IXT_WARNING 0 "no" 1 "yes" ;
VAL_ 460 ISOLATION_FAULT 0 "no" 1 "yes" ;
VAL_ 461 Inverter_A_Statusword_13 0 "NotReadyToSwitchOn" 64 "SwitchOnDisabled" 80 "SwitchOnDisabled" 96 "SwitchOnDisabled" 112 "SwitchOnDisabled" 33 "ReadyToSwitchOn" 49 "ReadyToSwitchOn" 35 "SwitchedOn" 51 "SwitchedOn" 39 "OperationEnabled" 55 "OperationEnabled" 7 "QuickStopActive" 23 "QuickStopActive" 15 "FaultReactionActive" 31 "FaultReactionActive" 47 "FaultReactionActive" 63 "FaultReactionActive" 8 "Fault" 24 "Fault" 40 "Fault" 56 "Fault" ;
VAL_ 461 EVENTBUFFER_NEW_EVENT 0 "no" 1 "yes" ;
VAL_ 461 EVENTBUFFER_OVERFLOW 0 "no" 1 "yes" ;
VAL_ 461 POWERMODULE_TRIPZONE_OVERCURRE 0 "no" 1 "yes" ;
VAL_ 461 POWERMODULE_CURRENT_OFFSET_INI 0 "no" 1 "yes" ;
VAL_ 461 POWERMODULE_TEMPSENSOR_ERROR 0 "no" 1 "yes" ;
VAL_ 461 POWERMODULE_TEMPERATURE_WARNIN 0 "no" 1 "yes" ;
VAL_ 461 POWERMODULE_OVERTEMPERATURE 0 "no" 1 "yes" ;
VAL_ 461 POWERMODULE_IXT_FAULT 0 "no" 1 "yes" ;
VAL_ 461 POWERMODULE_SW_OVERCURRENT 0 "no" 1 "yes" ;
VAL_ 461 POWERMODULE_PATTERNDATA_INCONS 0 "no" 1 "yes" ;
VAL_ 461 DCBUS_TRIPZONE_OVERVOLTAGE 0 "no" 1 "yes" ;
VAL_ 461 DCBUS_SW_OVERVOLTAGE 0 "no" 1 "yes" ;
VAL_ 461 DCBUS_SW_UNDERVOLTAGE 0 "no" 1 "yes" ;
VAL_ 461 NEIGHBOUR_FAULT 0 "no" 1 "yes" ;
VAL_ 461 MOTOR_TEMPSENSOR_ERROR 0 "no" 1 "yes" ;
VAL_ 461 MOTOR_TEMPERATURE_WARNING 0 "no" 1 "yes" ;
VAL_ 461 MOTOR_OVERTEMPERATURE 0 "no" 1 "yes" ;
VAL_ 461 MOTOR_STATOR_FREQ_TO_HIGH 0 "no" 1 "yes" ;
VAL_ 461 SUPPLYVOLTAGE_ERROR 0 "no" 1 "yes" ;
VAL_ 461 RPDO_TIMEOUT 0 "no" 1 "yes" ;
VAL_ 461 NMT_NOT_OPERATIONAL 0 "no" 1 "yes" ;
VAL_ 461 TASKOVERRUN 0 "no" 1 "yes" ;
VAL_ 461 NETSYNC_ERROR 0 "no" 1 "yes" ;
VAL_ 461 POSDEVICE_SIGNAL_TO_LOW 0 "no" 1 "yes" ;
VAL_ 461 POSDEVICE_SIGNAL_TO_HIGH 0 "no" 1 "yes" ;
VAL_ 461 RESOLVER_CALIBRATION_FAILED 0 "no" 1 "yes" ;
VAL_ 461 SYSTEM_FAULT 0 "no" 1 "yes" ;
VAL_ 461 INTERLOCK_OPEN 0 "no" 1 "yes" ;
VAL_ 461 APPC_HAS_GATE_DRIVER_DISABLED 0 "no" 1 "yes" ;
VAL_ 461 MOTOR_STALL_ERROR 0 "no" 1 "yes" ;
VAL_ 461 AMBIENT_TEMPERATURE_WARNING 0 "no" 1 "yes" ;
VAL_ 461 AMBIENT_OVERTEMPERATURE 0 "no" 1 "yes" ;
VAL_ 461 AMBIENT_TEMPSENSOR_ERROR 0 "no" 1 "yes" ;
VAL_ 461 POWERMODULE_CLAMPING_TIMEOUT 0 "no" 1 "yes" ;
VAL_ 461 DCBUS_RIPPLE_TO_HIGH 0 "no" 1 "yes" ;
VAL_ 461 MOTOR_I2XT_WARNING 0 "no" 1 "yes" ;
VAL_ 461 MOTOR_I2XT_ERROR 0 "no" 1 "yes" ;
VAL_ 461 MOTOR_FIELDWEAKENING_ERROR 0 "no" 1 "yes" ;
VAL_ 461 INVALID_PARAMETER_COMBINATION 0 "no" 1 "yes" ;
VAL_ 461 PLUG_COVER_SENSOR_SIGNAL_LOW 0 "no" 1 "yes" ;
VAL_ 461 MOTOR_CONNECTION_TEST_FAILED 0 "no" 1 "yes" ;
VAL_ 461 POWERMODULE_IXT_WARNING 0 "no" 1 "yes" ;
VAL_ 461 ISOLATION_FAULT 0 "no" 1 "yes" ;
VAL_ 718 Inverter_B_Statusword_14 0 "NotReadyToSwitchOn" 64 "SwitchOnDisabled" 80 "SwitchOnDisabled" 96 "SwitchOnDisabled" 112 "SwitchOnDisabled" 33 "ReadyToSwitchOn" 49 "ReadyToSwitchOn" 35 "SwitchedOn" 51 "SwitchedOn" 39 "OperationEnabled" 55 "OperationEnabled" 7 "QuickStopActive" 23 "QuickStopActive" 15 "FaultReactionActive" 31 "FaultReactionActive" 47 "FaultReactionActive" 63 "FaultReactionActive" 8 "Fault" 24 "Fault" 40 "Fault" 56 "Fault" ;
VAL_ 718 EVENTBUFFER_NEW_EVENT 0 "no" 1 "yes" ;
VAL_ 718 EVENTBUFFER_OVERFLOW 0 "no" 1 "yes" ;
VAL_ 718 POWERMODULE_TRIPZONE_OVERCURRE 0 "no" 1 "yes" ;
VAL_ 718 POWERMODULE_CURRENT_OFFSET_INI 0 "no" 1 "yes" ;
VAL_ 718 POWERMODULE_TEMPSENSOR_ERROR 0 "no" 1 "yes" ;
VAL_ 718 POWERMODULE_TEMPERATURE_WARNIN 0 "no" 1 "yes" ;
VAL_ 718 POWERMODULE_OVERTEMPERATURE 0 "no" 1 "yes" ;
VAL_ 718 POWERMODULE_IXT_FAULT 0 "no" 1 "yes" ;
VAL_ 718 POWERMODULE_SW_OVERCURRENT 0 "no" 1 "yes" ;
VAL_ 718 POWERMODULE_PATTERNDATA_INCONS 0 "no" 1 "yes" ;
VAL_ 718 DCBUS_TRIPZONE_OVERVOLTAGE 0 "no" 1 "yes" ;
VAL_ 718 DCBUS_SW_OVERVOLTAGE 0 "no" 1 "yes" ;
VAL_ 718 DCBUS_SW_UNDERVOLTAGE 0 "no" 1 "yes" ;
VAL_ 718 NEIGHBOUR_FAULT 0 "no" 1 "yes" ;
VAL_ 718 MOTOR_TEMPSENSOR_ERROR 0 "no" 1 "yes" ;
VAL_ 718 MOTOR_TEMPERATURE_WARNING 0 "no" 1 "yes" ;
VAL_ 718 MOTOR_OVERTEMPERATURE 0 "no" 1 "yes" ;
VAL_ 718 MOTOR_STATOR_FREQ_TO_HIGH 0 "no" 1 "yes" ;
VAL_ 718 SUPPLYVOLTAGE_ERROR 0 "no" 1 "yes" ;
VAL_ 718 RPDO_TIMEOUT 0 "no" 1 "yes" ;
VAL_ 718 NMT_NOT_OPERATIONAL 0 "no" 1 "yes" ;
VAL_ 718 TASKOVERRUN 0 "no" 1 "yes" ;
VAL_ 718 NETSYNC_ERROR 0 "no" 1 "yes" ;
VAL_ 718 POSDEVICE_SIGNAL_TO_LOW 0 "no" 1 "yes" ;
VAL_ 718 POSDEVICE_SIGNAL_TO_HIGH 0 "no" 1 "yes" ;
VAL_ 718 RESOLVER_CALIBRATION_FAILED 0 "no" 1 "yes" ;
VAL_ 718 SYSTEM_FAULT 0 "no" 1 "yes" ;
VAL_ 718 INTERLOCK_OPEN 0 "no" 1 "yes" ;
VAL_ 718 APPC_HAS_GATE_DRIVER_DISABLED 0 "no" 1 "yes" ;
VAL_ 718 MOTOR_STALL_ERROR 0 "no" 1 "yes" ;
VAL_ 718 AMBIENT_TEMPERATURE_WARNING 0 "no" 1 "yes" ;
VAL_ 718 AMBIENT_OVERTEMPERATURE 0 "no" 1 "yes" ;
VAL_ 718 AMBIENT_TEMPSENSOR_ERROR 0 "no" 1 "yes" ;
VAL_ 718 POWERMODULE_CLAMPING_TIMEOUT 0 "no" 1 "yes" ;
VAL_ 718 DCBUS_RIPPLE_TO_HIGH 0 "no" 1 "yes" ;
VAL_ 718 MOTOR_I2XT_WARNING 0 "no" 1 "yes" ;
VAL_ 718 MOTOR_I2XT_ERROR 0 "no" 1 "yes" ;
VAL_ 718 MOTOR_FIELDWEAKENING_ERROR 0 "no" 1 "yes" ;
VAL_ 718 INVALID_PARAMETER_COMBINATION 0 "no" 1 "yes" ;
VAL_ 718 PLUG_COVER_SENSOR_SIGNAL_LOW 0 "no" 1 "yes" ;
VAL_ 718 MOTOR_CONNECTION_TEST_FAILED 0 "no" 1 "yes" ;
VAL_ 718 POWERMODULE_IXT_WARNING 0 "no" 1 "yes" ;
VAL_ 718 ISOLATION_FAULT 0 "no" 1 "yes" ;
VAL_ 705 Inverter_B_Statusword_1 0 "NotReadyToSwitchOn" 64 "SwitchOnDisabled" 80 "SwitchOnDisabled" 96 "SwitchOnDisabled" 112 "SwitchOnDisabled" 33 "ReadyToSwitchOn" 49 "ReadyToSwitchOn" 35 "SwitchedOn" 51 "SwitchedOn" 39 "OperationEnabled" 55 "OperationEnabled" 7 "QuickStopActive" 23 "QuickStopActive" 15 "FaultReactionActive" 31 "FaultReactionActive" 47 "FaultReactionActive" 63 "FaultReactionActive" 8 "Fault" 24 "Fault" 40 "Fault" 56 "Fault" ;
VAL_ 705 EVENTBUFFER_NEW_EVENT 0 "no" 1 "yes" ;
VAL_ 705 EVENTBUFFER_OVERFLOW 0 "no" 1 "yes" ;
VAL_ 705 POWERMODULE_TRIPZONE_OVERCURRE 0 "no" 1 "yes" ;
VAL_ 705 POWERMODULE_CURRENT_OFFSET_INI 0 "no" 1 "yes" ;
VAL_ 705 POWERMODULE_TEMPSENSOR_ERROR 0 "no" 1 "yes" ;
VAL_ 705 POWERMODULE_TEMPERATURE_WARNIN 0 "no" 1 "yes" ;
VAL_ 705 POWERMODULE_OVERTEMPERATURE 0 "no" 1 "yes" ;
VAL_ 705 POWERMODULE_IXT_FAULT 0 "no" 1 "yes" ;
VAL_ 705 POWERMODULE_SW_OVERCURRENT 0 "no" 1 "yes" ;
VAL_ 705 POWERMODULE_PATTERNDATA_INCONS 0 "no" 1 "yes" ;
VAL_ 705 DCBUS_TRIPZONE_OVERVOLTAGE 0 "no" 1 "yes" ;
VAL_ 705 DCBUS_SW_OVERVOLTAGE 0 "no" 1 "yes" ;
VAL_ 705 DCBUS_SW_UNDERVOLTAGE 0 "no" 1 "yes" ;
VAL_ 705 NEIGHBOUR_FAULT 0 "no" 1 "yes" ;
VAL_ 705 MOTOR_TEMPSENSOR_ERROR 0 "no" 1 "yes" ;
VAL_ 705 MOTOR_TEMPERATURE_WARNING 0 "no" 1 "yes" ;
VAL_ 705 MOTOR_OVERTEMPERATURE 0 "no" 1 "yes" ;
VAL_ 705 MOTOR_STATOR_FREQ_TO_HIGH 0 "no" 1 "yes" ;
VAL_ 705 SUPPLYVOLTAGE_ERROR 0 "no" 1 "yes" ;
VAL_ 705 RPDO_TIMEOUT 0 "no" 1 "yes" ;
VAL_ 705 NMT_NOT_OPERATIONAL 0 "no" 1 "yes" ;
VAL_ 705 TASKOVERRUN 0 "no" 1 "yes" ;
VAL_ 705 NETSYNC_ERROR 0 "no" 1 "yes" ;
VAL_ 705 POSDEVICE_SIGNAL_TO_LOW 0 "no" 1 "yes" ;
VAL_ 705 POSDEVICE_SIGNAL_TO_HIGH 0 "no" 1 "yes" ;
VAL_ 705 RESOLVER_CALIBRATION_FAILED 0 "no" 1 "yes" ;
VAL_ 705 SYSTEM_FAULT 0 "no" 1 "yes" ;
VAL_ 705 INTERLOCK_OPEN 0 "no" 1 "yes" ;
VAL_ 705 APPC_HAS_GATE_DRIVER_DISABLED 0 "no" 1 "yes" ;
VAL_ 705 MOTOR_STALL_ERROR 0 "no" 1 "yes" ;
VAL_ 705 AMBIENT_TEMPERATURE_WARNING 0 "no" 1 "yes" ;
VAL_ 705 AMBIENT_OVERTEMPERATURE 0 "no" 1 "yes" ;
VAL_ 705 AMBIENT_TEMPSENSOR_ERROR 0 "no" 1 "yes" ;
VAL_ 705 POWERMODULE_CLAMPING_TIMEOUT 0 "no" 1 "yes" ;
VAL_ 705 DCBUS_RIPPLE_TO_HIGH 0 "no" 1 "yes" ;
VAL_ 705 MOTOR_I2XT_WARNING 0 "no" 1 "yes" ;
VAL_ 705 MOTOR_I2XT_ERROR 0 "no" 1 "yes" ;
VAL_ 705 MOTOR_FIELDWEAKENING_ERROR 0 "no" 1 "yes" ;
VAL_ 705 INVALID_PARAMETER_COMBINATION 0 "no" 1 "yes" ;
VAL_ 705 PLUG_COVER_SENSOR_SIGNAL_LOW 0 "no" 1 "yes" ;
VAL_ 705 MOTOR_CONNECTION_TEST_FAILED 0 "no" 1 "yes" ;
VAL_ 705 POWERMODULE_IXT_WARNING 0 "no" 1 "yes" ;
VAL_ 705 ISOLATION_FAULT 0 "no" 1 "yes" ;
VAL_ 706 Inverter_B_Statusword_2 0 "NotReadyToSwitchOn" 64 "SwitchOnDisabled" 80 "SwitchOnDisabled" 96 "SwitchOnDisabled" 112 "SwitchOnDisabled" 33 "ReadyToSwitchOn" 49 "ReadyToSwitchOn" 35 "SwitchedOn" 51 "SwitchedOn" 39 "OperationEnabled" 55 "OperationEnabled" 7 "QuickStopActive" 23 "QuickStopActive" 15 "FaultReactionActive" 31 "FaultReactionActive" 47 "FaultReactionActive" 63 "FaultReactionActive" 8 "Fault" 24 "Fault" 40 "Fault" 56 "Fault" ;
VAL_ 706 EVENTBUFFER_NEW_EVENT 0 "no" 1 "yes" ;
VAL_ 706 EVENTBUFFER_OVERFLOW 0 "no" 1 "yes" ;
VAL_ 706 POWERMODULE_TRIPZONE_OVERCURRE 0 "no" 1 "yes" ;
VAL_ 706 POWERMODULE_CURRENT_OFFSET_INI 0 "no" 1 "yes" ;
VAL_ 706 POWERMODULE_TEMPSENSOR_ERROR 0 "no" 1 "yes" ;
VAL_ 706 POWERMODULE_TEMPERATURE_WARNIN 0 "no" 1 "yes" ;
VAL_ 706 POWERMODULE_OVERTEMPERATURE 0 "no" 1 "yes" ;
VAL_ 706 POWERMODULE_IXT_FAULT 0 "no" 1 "yes" ;
VAL_ 706 POWERMODULE_SW_OVERCURRENT 0 "no" 1 "yes" ;
VAL_ 706 POWERMODULE_PATTERNDATA_INCONS 0 "no" 1 "yes" ;
VAL_ 706 DCBUS_TRIPZONE_OVERVOLTAGE 0 "no" 1 "yes" ;
VAL_ 706 DCBUS_SW_OVERVOLTAGE 0 "no" 1 "yes" ;
VAL_ 706 DCBUS_SW_UNDERVOLTAGE 0 "no" 1 "yes" ;
VAL_ 706 NEIGHBOUR_FAULT 0 "no" 1 "yes" ;
VAL_ 706 MOTOR_TEMPSENSOR_ERROR 0 "no" 1 "yes" ;
VAL_ 706 MOTOR_TEMPERATURE_WARNING 0 "no" 1 "yes" ;
VAL_ 706 MOTOR_OVERTEMPERATURE 0 "no" 1 "yes" ;
VAL_ 706 MOTOR_STATOR_FREQ_TO_HIGH 0 "no" 1 "yes" ;
VAL_ 706 SUPPLYVOLTAGE_ERROR 0 "no" 1 "yes" ;
VAL_ 706 RPDO_TIMEOUT 0 "no" 1 "yes" ;
VAL_ 706 NMT_NOT_OPERATIONAL 0 "no" 1 "yes" ;
VAL_ 706 TASKOVERRUN 0 "no" 1 "yes" ;
VAL_ 706 NETSYNC_ERROR 0 "no" 1 "yes" ;
VAL_ 706 POSDEVICE_SIGNAL_TO_LOW 0 "no" 1 "yes" ;
VAL_ 706 POSDEVICE_SIGNAL_TO_HIGH 0 "no" 1 "yes" ;
VAL_ 706 RESOLVER_CALIBRATION_FAILED 0 "no" 1 "yes" ;
VAL_ 706 SYSTEM_FAULT 0 "no" 1 "yes" ;
VAL_ 706 INTERLOCK_OPEN 0 "no" 1 "yes" ;
VAL_ 706 APPC_HAS_GATE_DRIVER_DISABLED 0 "no" 1 "yes" ;
VAL_ 706 MOTOR_STALL_ERROR 0 "no" 1 "yes" ;
VAL_ 706 AMBIENT_TEMPERATURE_WARNING 0 "no" 1 "yes" ;
VAL_ 706 AMBIENT_OVERTEMPERATURE 0 "no" 1 "yes" ;
VAL_ 706 AMBIENT_TEMPSENSOR_ERROR 0 "no" 1 "yes" ;
VAL_ 706 POWERMODULE_CLAMPING_TIMEOUT 0 "no" 1 "yes" ;
VAL_ 706 DCBUS_RIPPLE_TO_HIGH 0 "no" 1 "yes" ;
VAL_ 706 MOTOR_I2XT_WARNING 0 "no" 1 "yes" ;
VAL_ 706 MOTOR_I2XT_ERROR 0 "no" 1 "yes" ;
VAL_ 706 MOTOR_FIELDWEAKENING_ERROR 0 "no" 1 "yes" ;
VAL_ 706 INVALID_PARAMETER_COMBINATION 0 "no" 1 "yes" ;
VAL_ 706 PLUG_COVER_SENSOR_SIGNAL_LOW 0 "no" 1 "yes" ;
VAL_ 706 MOTOR_CONNECTION_TEST_FAILED 0 "no" 1 "yes" ;
VAL_ 706 POWERMODULE_IXT_WARNING 0 "no" 1 "yes" ;
VAL_ 706 ISOLATION_FAULT 0 "no" 1 "yes" ;
VAL_ 707 Inverter_B_Statusword_3 0 "NotReadyToSwitchOn" 64 "SwitchOnDisabled" 80 "SwitchOnDisabled" 96 "SwitchOnDisabled" 112 "SwitchOnDisabled" 33 "ReadyToSwitchOn" 49 "ReadyToSwitchOn" 35 "SwitchedOn" 51 "SwitchedOn" 39 "OperationEnabled" 55 "OperationEnabled" 7 "QuickStopActive" 23 "QuickStopActive" 15 "FaultReactionActive" 31 "FaultReactionActive" 47 "FaultReactionActive" 63 "FaultReactionActive" 8 "Fault" 24 "Fault" 40 "Fault" 56 "Fault" ;
VAL_ 707 EVENTBUFFER_NEW_EVENT 0 "no" 1 "yes" ;
VAL_ 707 EVENTBUFFER_OVERFLOW 0 "no" 1 "yes" ;
VAL_ 707 POWERMODULE_TRIPZONE_OVERCURRE 0 "no" 1 "yes" ;
VAL_ 707 POWERMODULE_CURRENT_OFFSET_INI 0 "no" 1 "yes" ;
VAL_ 707 POWERMODULE_TEMPSENSOR_ERROR 0 "no" 1 "yes" ;
VAL_ 707 POWERMODULE_TEMPERATURE_WARNIN 0 "no" 1 "yes" ;
VAL_ 707 POWERMODULE_OVERTEMPERATURE 0 "no" 1 "yes" ;
VAL_ 707 POWERMODULE_IXT_FAULT 0 "no" 1 "yes" ;
VAL_ 707 POWERMODULE_SW_OVERCURRENT 0 "no" 1 "yes" ;
VAL_ 707 POWERMODULE_PATTERNDATA_INCONS 0 "no" 1 "yes" ;
VAL_ 707 DCBUS_TRIPZONE_OVERVOLTAGE 0 "no" 1 "yes" ;
VAL_ 707 DCBUS_SW_OVERVOLTAGE 0 "no" 1 "yes" ;
VAL_ 707 DCBUS_SW_UNDERVOLTAGE 0 "no" 1 "yes" ;
VAL_ 707 NEIGHBOUR_FAULT 0 "no" 1 "yes" ;
VAL_ 707 MOTOR_TEMPSENSOR_ERROR 0 "no" 1 "yes" ;
VAL_ 707 MOTOR_TEMPERATURE_WARNING 0 "no" 1 "yes" ;
VAL_ 707 MOTOR_OVERTEMPERATURE 0 "no" 1 "yes" ;
VAL_ 707 MOTOR_STATOR_FREQ_TO_HIGH 0 "no" 1 "yes" ;
VAL_ 707 SUPPLYVOLTAGE_ERROR 0 "no" 1 "yes" ;
VAL_ 707 RPDO_TIMEOUT 0 "no" 1 "yes" ;
VAL_ 707 NMT_NOT_OPERATIONAL 0 "no" 1 "yes" ;
VAL_ 707 TASKOVERRUN 0 "no" 1 "yes" ;
VAL_ 707 NETSYNC_ERROR 0 "no" 1 "yes" ;
VAL_ 707 POSDEVICE_SIGNAL_TO_LOW 0 "no" 1 "yes" ;
VAL_ 707 POSDEVICE_SIGNAL_TO_HIGH 0 "no" 1 "yes" ;
VAL_ 707 RESOLVER_CALIBRATION_FAILED 0 "no" 1 "yes" ;
VAL_ 707 SYSTEM_FAULT 0 "no" 1 "yes" ;
VAL_ 707 INTERLOCK_OPEN 0 "no" 1 "yes" ;
VAL_ 707 APPC_HAS_GATE_DRIVER_DISABLED 0 "no" 1 "yes" ;
VAL_ 707 MOTOR_STALL_ERROR 0 "no" 1 "yes" ;
VAL_ 707 AMBIENT_TEMPERATURE_WARNING 0 "no" 1 "yes" ;
VAL_ 707 AMBIENT_OVERTEMPERATURE 0 "no" 1 "yes" ;
VAL_ 707 AMBIENT_TEMPSENSOR_ERROR 0 "no" 1 "yes" ;
VAL_ 707 POWERMODULE_CLAMPING_TIMEOUT 0 "no" 1 "yes" ;
VAL_ 707 DCBUS_RIPPLE_TO_HIGH 0 "no" 1 "yes" ;
VAL_ 707 MOTOR_I2XT_WARNING 0 "no" 1 "yes" ;
VAL_ 707 MOTOR_I2XT_ERROR 0 "no" 1 "yes" ;
VAL_ 707 MOTOR_FIELDWEAKENING_ERROR 0 "no" 1 "yes" ;
VAL_ 707 INVALID_PARAMETER_COMBINATION 0 "no" 1 "yes" ;
VAL_ 707 PLUG_COVER_SENSOR_SIGNAL_LOW 0 "no" 1 "yes" ;
VAL_ 707 MOTOR_CONNECTION_TEST_FAILED 0 "no" 1 "yes" ;
VAL_ 707 POWERMODULE_IXT_WARNING 0 "no" 1 "yes" ;
VAL_ 707 ISOLATION_FAULT 0 "no" 1 "yes" ;
VAL_ 708 Inverter_B_Statusword_4 0 "NotReadyToSwitchOn" 64 "SwitchOnDisabled" 80 "SwitchOnDisabled" 96 "SwitchOnDisabled" 112 "SwitchOnDisabled" 33 "ReadyToSwitchOn" 49 "ReadyToSwitchOn" 35 "SwitchedOn" 51 "SwitchedOn" 39 "OperationEnabled" 55 "OperationEnabled" 7 "QuickStopActive" 23 "QuickStopActive" 15 "FaultReactionActive" 31 "FaultReactionActive" 47 "FaultReactionActive" 63 "FaultReactionActive" 8 "Fault" 24 "Fault" 40 "Fault" 56 "Fault" ;
VAL_ 708 EVENTBUFFER_NEW_EVENT 0 "no" 1 "yes" ;
VAL_ 708 EVENTBUFFER_OVERFLOW 0 "no" 1 "yes" ;
VAL_ 708 POWERMODULE_TRIPZONE_OVERCURRE 0 "no" 1 "yes" ;
VAL_ 708 POWERMODULE_CURRENT_OFFSET_INI 0 "no" 1 "yes" ;
VAL_ 708 POWERMODULE_TEMPSENSOR_ERROR 0 "no" 1 "yes" ;
VAL_ 708 POWERMODULE_TEMPERATURE_WARNIN 0 "no" 1 "yes" ;
VAL_ 708 POWERMODULE_OVERTEMPERATURE 0 "no" 1 "yes" ;
VAL_ 708 POWERMODULE_IXT_FAULT 0 "no" 1 "yes" ;
VAL_ 708 POWERMODULE_SW_OVERCURRENT 0 "no" 1 "yes" ;
VAL_ 708 POWERMODULE_PATTERNDATA_INCONS 0 "no" 1 "yes" ;
VAL_ 708 DCBUS_TRIPZONE_OVERVOLTAGE 0 "no" 1 "yes" ;
VAL_ 708 DCBUS_SW_OVERVOLTAGE 0 "no" 1 "yes" ;
VAL_ 708 DCBUS_SW_UNDERVOLTAGE 0 "no" 1 "yes" ;
VAL_ 708 NEIGHBOUR_FAULT 0 "no" 1 "yes" ;
VAL_ 708 MOTOR_TEMPSENSOR_ERROR 0 "no" 1 "yes" ;
VAL_ 708 MOTOR_TEMPERATURE_WARNING 0 "no" 1 "yes" ;
VAL_ 708 MOTOR_OVERTEMPERATURE 0 "no" 1 "yes" ;
VAL_ 708 MOTOR_STATOR_FREQ_TO_HIGH 0 "no" 1 "yes" ;
VAL_ 708 SUPPLYVOLTAGE_ERROR 0 "no" 1 "yes" ;
VAL_ 708 RPDO_TIMEOUT 0 "no" 1 "yes" ;
VAL_ 708 NMT_NOT_OPERATIONAL 0 "no" 1 "yes" ;
VAL_ 708 TASKOVERRUN 0 "no" 1 "yes" ;
VAL_ 708 NETSYNC_ERROR 0 "no" 1 "yes" ;
VAL_ 708 POSDEVICE_SIGNAL_TO_LOW 0 "no" 1 "yes" ;
VAL_ 708 POSDEVICE_SIGNAL_TO_HIGH 0 "no" 1 "yes" ;
VAL_ 708 RESOLVER_CALIBRATION_FAILED 0 "no" 1 "yes" ;
VAL_ 708 SYSTEM_FAULT 0 "no" 1 "yes" ;
VAL_ 708 INTERLOCK_OPEN 0 "no" 1 "yes" ;
VAL_ 708 APPC_HAS_GATE_DRIVER_DISABLED 0 "no" 1 "yes" ;
VAL_ 708 MOTOR_STALL_ERROR 0 "no" 1 "yes" ;
VAL_ 708 AMBIENT_TEMPERATURE_WARNING 0 "no" 1 "yes" ;
VAL_ 708 AMBIENT_OVERTEMPERATURE 0 "no" 1 "yes" ;
VAL_ 708 AMBIENT_TEMPSENSOR_ERROR 0 "no" 1 "yes" ;
VAL_ 708 POWERMODULE_CLAMPING_TIMEOUT 0 "no" 1 "yes" ;
VAL_ 708 DCBUS_RIPPLE_TO_HIGH 0 "no" 1 "yes" ;
VAL_ 708 MOTOR_I2XT_WARNING 0 "no" 1 "yes" ;
VAL_ 708 MOTOR_I2XT_ERROR 0 "no" 1 "yes" ;
VAL_ 708 MOTOR_FIELDWEAKENING_ERROR 0 "no" 1 "yes" ;
VAL_ 708 INVALID_PARAMETER_COMBINATION 0 "no" 1 "yes" ;
VAL_ 708 PLUG_COVER_SENSOR_SIGNAL_LOW 0 "no" 1 "yes" ;
VAL_ 708 MOTOR_CONNECTION_TEST_FAILED 0 "no" 1 "yes" ;
VAL_ 708 POWERMODULE_IXT_WARNING 0 "no" 1 "yes" ;
VAL_ 708 ISOLATION_FAULT 0 "no" 1 "yes" ;
VAL_ 709 Inverter_B_Statusword_5 0 "NotReadyToSwitchOn" 64 "SwitchOnDisabled" 80 "SwitchOnDisabled" 96 "SwitchOnDisabled" 112 "SwitchOnDisabled" 33 "ReadyToSwitchOn" 49 "ReadyToSwitchOn" 35 "SwitchedOn" 51 "SwitchedOn" 39 "OperationEnabled" 55 "OperationEnabled" 7 "QuickStopActive" 23 "QuickStopActive" 15 "FaultReactionActive" 31 "FaultReactionActive" 47 "FaultReactionActive" 63 "FaultReactionActive" 8 "Fault" 24 "Fault" 40 "Fault" 56 "Fault" ;
VAL_ 709 EVENTBUFFER_NEW_EVENT 0 "no" 1 "yes" ;
VAL_ 709 EVENTBUFFER_OVERFLOW 0 "no" 1 "yes" ;
VAL_ 709 POWERMODULE_TRIPZONE_OVERCURRE 0 "no" 1 "yes" ;
VAL_ 709 POWERMODULE_CURRENT_OFFSET_INI 0 "no" 1 "yes" ;
VAL_ 709 POWERMODULE_TEMPSENSOR_ERROR 0 "no" 1 "yes" ;
VAL_ 709 POWERMODULE_TEMPERATURE_WARNIN 0 "no" 1 "yes" ;
VAL_ 709 POWERMODULE_OVERTEMPERATURE 0 "no" 1 "yes" ;
VAL_ 709 POWERMODULE_IXT_FAULT 0 "no" 1 "yes" ;
VAL_ 709 POWERMODULE_SW_OVERCURRENT 0 "no" 1 "yes" ;
VAL_ 709 POWERMODULE_PATTERNDATA_INCONS 0 "no" 1 "yes" ;
VAL_ 709 DCBUS_TRIPZONE_OVERVOLTAGE 0 "no" 1 "yes" ;
VAL_ 709 DCBUS_SW_OVERVOLTAGE 0 "no" 1 "yes" ;
VAL_ 709 DCBUS_SW_UNDERVOLTAGE 0 "no" 1 "yes" ;
VAL_ 709 NEIGHBOUR_FAULT 0 "no" 1 "yes" ;
VAL_ 709 MOTOR_TEMPSENSOR_ERROR 0 "no" 1 "yes" ;
VAL_ 709 MOTOR_TEMPERATURE_WARNING 0 "no" 1 "yes" ;
VAL_ 709 MOTOR_OVERTEMPERATURE 0 "no" 1 "yes" ;
VAL_ 709 MOTOR_STATOR_FREQ_TO_HIGH 0 "no" 1 "yes" ;
VAL_ 709 SUPPLYVOLTAGE_ERROR 0 "no" 1 "yes" ;
VAL_ 709 RPDO_TIMEOUT 0 "no" 1 "yes" ;
VAL_ 709 NMT_NOT_OPERATIONAL 0 "no" 1 "yes" ;
VAL_ 709 TASKOVERRUN 0 "no" 1 "yes" ;
VAL_ 709 NETSYNC_ERROR 0 "no" 1 "yes" ;
VAL_ 709 POSDEVICE_SIGNAL_TO_LOW 0 "no" 1 "yes" ;
VAL_ 709 POSDEVICE_SIGNAL_TO_HIGH 0 "no" 1 "yes" ;
VAL_ 709 RESOLVER_CALIBRATION_FAILED 0 "no" 1 "yes" ;
VAL_ 709 SYSTEM_FAULT 0 "no" 1 "yes" ;
VAL_ 709 INTERLOCK_OPEN 0 "no" 1 "yes" ;
VAL_ 709 APPC_HAS_GATE_DRIVER_DISABLED 0 "no" 1 "yes" ;
VAL_ 709 MOTOR_STALL_ERROR 0 "no" 1 "yes" ;
VAL_ 709 AMBIENT_TEMPERATURE_WARNING 0 "no" 1 "yes" ;
VAL_ 709 AMBIENT_OVERTEMPERATURE 0 "no" 1 "yes" ;
VAL_ 709 AMBIENT_TEMPSENSOR_ERROR 0 "no" 1 "yes" ;
VAL_ 709 POWERMODULE_CLAMPING_TIMEOUT 0 "no" 1 "yes" ;
VAL_ 709 DCBUS_RIPPLE_TO_HIGH 0 "no" 1 "yes" ;
VAL_ 709 MOTOR_I2XT_WARNING 0 "no" 1 "yes" ;
VAL_ 709 MOTOR_I2XT_ERROR 0 "no" 1 "yes" ;
VAL_ 709 MOTOR_FIELDWEAKENING_ERROR 0 "no" 1 "yes" ;
VAL_ 709 INVALID_PARAMETER_COMBINATION 0 "no" 1 "yes" ;
VAL_ 709 PLUG_COVER_SENSOR_SIGNAL_LOW 0 "no" 1 "yes" ;
VAL_ 709 MOTOR_CONNECTION_TEST_FAILED 0 "no" 1 "yes" ;
VAL_ 709 POWERMODULE_IXT_WARNING 0 "no" 1 "yes" ;
VAL_ 709 ISOLATION_FAULT 0 "no" 1 "yes" ;
VAL_ 710 Inverter_B_Statusword_6 0 "NotReadyToSwitchOn" 64 "SwitchOnDisabled" 80 "SwitchOnDisabled" 96 "SwitchOnDisabled" 112 "SwitchOnDisabled" 33 "ReadyToSwitchOn" 49 "ReadyToSwitchOn" 35 "SwitchedOn" 51 "SwitchedOn" 39 "OperationEnabled" 55 "OperationEnabled" 7 "QuickStopActive" 23 "QuickStopActive" 15 "FaultReactionActive" 31 "FaultReactionActive" 47 "FaultReactionActive" 63 "FaultReactionActive" 8 "Fault" 24 "Fault" 40 "Fault" 56 "Fault" ;
VAL_ 710 EVENTBUFFER_NEW_EVENT 0 "no" 1 "yes" ;
VAL_ 710 EVENTBUFFER_OVERFLOW 0 "no" 1 "yes" ;
VAL_ 710 POWERMODULE_TRIPZONE_OVERCURRE 0 "no" 1 "yes" ;
VAL_ 710 POWERMODULE_CURRENT_OFFSET_INI 0 "no" 1 "yes" ;
VAL_ 710 POWERMODULE_TEMPSENSOR_ERROR 0 "no" 1 "yes" ;
VAL_ 710 POWERMODULE_TEMPERATURE_WARNIN 0 "no" 1 "yes" ;
VAL_ 710 POWERMODULE_OVERTEMPERATURE 0 "no" 1 "yes" ;
VAL_ 710 POWERMODULE_IXT_FAULT 0 "no" 1 "yes" ;
VAL_ 710 POWERMODULE_SW_OVERCURRENT 0 "no" 1 "yes" ;
VAL_ 710 POWERMODULE_PATTERNDATA_INCONS 0 "no" 1 "yes" ;
VAL_ 710 DCBUS_TRIPZONE_OVERVOLTAGE 0 "no" 1 "yes" ;
VAL_ 710 DCBUS_SW_OVERVOLTAGE 0 "no" 1 "yes" ;
VAL_ 710 DCBUS_SW_UNDERVOLTAGE 0 "no" 1 "yes" ;
VAL_ 710 NEIGHBOUR_FAULT 0 "no" 1 "yes" ;
VAL_ 710 MOTOR_TEMPSENSOR_ERROR 0 "no" 1 "yes" ;
VAL_ 710 MOTOR_TEMPERATURE_WARNING 0 "no" 1 "yes" ;
VAL_ 710 MOTOR_OVERTEMPERATURE 0 "no" 1 "yes" ;
VAL_ 710 MOTOR_STATOR_FREQ_TO_HIGH 0 "no" 1 "yes" ;
VAL_ 710 SUPPLYVOLTAGE_ERROR 0 "no" 1 "yes" ;
VAL_ 710 RPDO_TIMEOUT 0 "no" 1 "yes" ;
VAL_ 710 NMT_NOT_OPERATIONAL 0 "no" 1 "yes" ;
VAL_ 710 TASKOVERRUN 0 "no" 1 "yes" ;
VAL_ 710 NETSYNC_ERROR 0 "no" 1 "yes" ;
VAL_ 710 POSDEVICE_SIGNAL_TO_LOW 0 "no" 1 "yes" ;
VAL_ 710 POSDEVICE_SIGNAL_TO_HIGH 0 "no" 1 "yes" ;
VAL_ 710 RESOLVER_CALIBRATION_FAILED 0 "no" 1 "yes" ;
VAL_ 710 SYSTEM_FAULT 0 "no" 1 "yes" ;
VAL_ 710 INTERLOCK_OPEN 0 "no" 1 "yes" ;
VAL_ 710 APPC_HAS_GATE_DRIVER_DISABLED 0 "no" 1 "yes" ;
VAL_ 710 MOTOR_STALL_ERROR 0 "no" 1 "yes" ;
VAL_ 710 AMBIENT_TEMPERATURE_WARNING 0 "no" 1 "yes" ;
VAL_ 710 AMBIENT_OVERTEMPERATURE 0 "no" 1 "yes" ;
VAL_ 710 AMBIENT_TEMPSENSOR_ERROR 0 "no" 1 "yes" ;
VAL_ 710 POWERMODULE_CLAMPING_TIMEOUT 0 "no" 1 "yes" ;
VAL_ 710 DCBUS_RIPPLE_TO_HIGH 0 "no" 1 "yes" ;
VAL_ 710 MOTOR_I2XT_WARNING 0 "no" 1 "yes" ;
VAL_ 710 MOTOR_I2XT_ERROR 0 "no" 1 "yes" ;
VAL_ 710 MOTOR_FIELDWEAKENING_ERROR 0 "no" 1 "yes" ;
VAL_ 710 INVALID_PARAMETER_COMBINATION 0 "no" 1 "yes" ;
VAL_ 710 PLUG_COVER_SENSOR_SIGNAL_LOW 0 "no" 1 "yes" ;
VAL_ 710 MOTOR_CONNECTION_TEST_FAILED 0 "no" 1 "yes" ;
VAL_ 710 POWERMODULE_IXT_WARNING 0 "no" 1 "yes" ;
VAL_ 710 ISOLATION_FAULT 0 "no" 1 "yes" ;
VAL_ 711 Inverter_B_Statusword_7 0 "NotReadyToSwitchOn" 64 "SwitchOnDisabled" 80 "SwitchOnDisabled" 96 "SwitchOnDisabled" 112 "SwitchOnDisabled" 33 "ReadyToSwitchOn" 49 "ReadyToSwitchOn" 35 "SwitchedOn" 51 "SwitchedOn" 39 "OperationEnabled" 55 "OperationEnabled" 7 "QuickStopActive" 23 "QuickStopActive" 15 "FaultReactionActive" 31 "FaultReactionActive" 47 "FaultReactionActive" 63 "FaultReactionActive" 8 "Fault" 24 "Fault" 40 "Fault" 56 "Fault" ;
VAL_ 711 EVENTBUFFER_NEW_EVENT 0 "no" 1 "yes" ;
VAL_ 711 EVENTBUFFER_OVERFLOW 0 "no" 1 "yes" ;
VAL_ 711 POWERMODULE_TRIPZONE_OVERCURRE 0 "no" 1 "yes" ;
VAL_ 711 POWERMODULE_CURRENT_OFFSET_INI 0 "no" 1 "yes" ;
VAL_ 711 POWERMODULE_TEMPSENSOR_ERROR 0 "no" 1 "yes" ;
VAL_ 711 POWERMODULE_TEMPERATURE_WARNIN 0 "no" 1 "yes" ;
VAL_ 711 POWERMODULE_OVERTEMPERATURE 0 "no" 1 "yes" ;
VAL_ 711 POWERMODULE_IXT_FAULT 0 "no" 1 "yes" ;
VAL_ 711 POWERMODULE_SW_OVERCURRENT 0 "no" 1 "yes" ;
VAL_ 711 POWERMODULE_PATTERNDATA_INCONS 0 "no" 1 "yes" ;
VAL_ 711 DCBUS_TRIPZONE_OVERVOLTAGE 0 "no" 1 "yes" ;
VAL_ 711 DCBUS_SW_OVERVOLTAGE 0 "no" 1 "yes" ;
VAL_ 711 DCBUS_SW_UNDERVOLTAGE 0 "no" 1 "yes" ;
VAL_ 711 NEIGHBOUR_FAULT 0 "no" 1 "yes" ;
VAL_ 711 MOTOR_TEMPSENSOR_ERROR 0 "no" 1 "yes" ;
VAL_ 711 MOTOR_TEMPERATURE_WARNING 0 "no" 1 "yes" ;
VAL_ 711 MOTOR_OVERTEMPERATURE 0 "no" 1 "yes" ;
VAL_ 711 MOTOR_STATOR_FREQ_TO_HIGH 0 "no" 1 "yes" ;
VAL_ 711 SUPPLYVOLTAGE_ERROR 0 "no" 1 "yes" ;
VAL_ 711 RPDO_TIMEOUT 0 "no" 1 "yes" ;
VAL_ 711 NMT_NOT_OPERATIONAL 0 "no" 1 "yes" ;
VAL_ 711 TASKOVERRUN 0 "no" 1 "yes" ;
VAL_ 711 NETSYNC_ERROR 0 "no" 1 "yes" ;
VAL_ 711 POSDEVICE_SIGNAL_TO_LOW 0 "no" 1 "yes" ;
VAL_ 711 POSDEVICE_SIGNAL_TO_HIGH 0 "no" 1 "yes" ;
VAL_ 711 RESOLVER_CALIBRATION_FAILED 0 "no" 1 "yes" ;
VAL_ 711 SYSTEM_FAULT 0 "no" 1 "yes" ;
VAL_ 711 INTERLOCK_OPEN 0 "no" 1 "yes" ;
VAL_ 711 APPC_HAS_GATE_DRIVER_DISABLED 0 "no" 1 "yes" ;
VAL_ 711 MOTOR_STALL_ERROR 0 "no" 1 "yes" ;
VAL_ 711 AMBIENT_TEMPERATURE_WARNING 0 "no" 1 "yes" ;
VAL_ 711 AMBIENT_OVERTEMPERATURE 0 "no" 1 "yes" ;
VAL_ 711 AMBIENT_TEMPSENSOR_ERROR 0 "no" 1 "yes" ;
VAL_ 711 POWERMODULE_CLAMPING_TIMEOUT 0 "no" 1 "yes" ;
VAL_ 711 DCBUS_RIPPLE_TO_HIGH 0 "no" 1 "yes" ;
VAL_ 711 MOTOR_I2XT_WARNING 0 "no" 1 "yes" ;
VAL_ 711 MOTOR_I2XT_ERROR 0 "no" 1 "yes" ;
VAL_ 711 MOTOR_FIELDWEAKENING_ERROR 0 "no" 1 "yes" ;
VAL_ 711 INVALID_PARAMETER_COMBINATION 0 "no" 1 "yes" ;
VAL_ 711 PLUG_COVER_SENSOR_SIGNAL_LOW 0 "no" 1 "yes" ;
VAL_ 711 MOTOR_CONNECTION_TEST_FAILED 0 "no" 1 "yes" ;
VAL_ 711 POWERMODULE_IXT_WARNING 0 "no" 1 "yes" ;
VAL_ 711 ISOLATION_FAULT 0 "no" 1 "yes" ;
VAL_ 712 Inverter_B_Statusword_8 0 "NotReadyToSwitchOn" 64 "SwitchOnDisabled" 80 "SwitchOnDisabled" 96 "SwitchOnDisabled" 112 "SwitchOnDisabled" 33 "ReadyToSwitchOn" 49 "ReadyToSwitchOn" 35 "SwitchedOn" 51 "SwitchedOn" 39 "OperationEnabled" 55 "OperationEnabled" 7 "QuickStopActive" 23 "QuickStopActive" 15 "FaultReactionActive" 31 "FaultReactionActive" 47 "FaultReactionActive" 63 "FaultReactionActive" 8 "Fault" 24 "Fault" 40 "Fault" 56 "Fault" ;
VAL_ 712 EVENTBUFFER_NEW_EVENT 0 "no" 1 "yes" ;
VAL_ 712 EVENTBUFFER_OVERFLOW 0 "no" 1 "yes" ;
VAL_ 712 POWERMODULE_TRIPZONE_OVERCURRE 0 "no" 1 "yes" ;
VAL_ 712 POWERMODULE_CURRENT_OFFSET_INI 0 "no" 1 "yes" ;
VAL_ 712 POWERMODULE_TEMPSENSOR_ERROR 0 "no" 1 "yes" ;
VAL_ 712 POWERMODULE_TEMPERATURE_WARNIN 0 "no" 1 "yes" ;
VAL_ 712 POWERMODULE_OVERTEMPERATURE 0 "no" 1 "yes" ;
VAL_ 712 POWERMODULE_IXT_FAULT 0 "no" 1 "yes" ;
VAL_ 712 POWERMODULE_SW_OVERCURRENT 0 "no" 1 "yes" ;
VAL_ 712 POWERMODULE_PATTERNDATA_INCONS 0 "no" 1 "yes" ;
VAL_ 712 DCBUS_TRIPZONE_OVERVOLTAGE 0 "no" 1 "yes" ;
VAL_ 712 DCBUS_SW_OVERVOLTAGE 0 "no" 1 "yes" ;
VAL_ 712 DCBUS_SW_UNDERVOLTAGE 0 "no" 1 "yes" ;
VAL_ 712 NEIGHBOUR_FAULT 0 "no" 1 "yes" ;
VAL_ 712 MOTOR_TEMPSENSOR_ERROR 0 "no" 1 "yes" ;
VAL_ 712 MOTOR_TEMPERATURE_WARNING 0 "no" 1 "yes" ;
VAL_ 712 MOTOR_OVERTEMPERATURE 0 "no" 1 "yes" ;
VAL_ 712 MOTOR_STATOR_FREQ_TO_HIGH 0 "no" 1 "yes" ;
VAL_ 712 SUPPLYVOLTAGE_ERROR 0 "no" 1 "yes" ;
VAL_ 712 RPDO_TIMEOUT 0 "no" 1 "yes" ;
VAL_ 712 NMT_NOT_OPERATIONAL 0 "no" 1 "yes" ;
VAL_ 712 TASKOVERRUN 0 "no" 1 "yes" ;
VAL_ 712 NETSYNC_ERROR 0 "no" 1 "yes" ;
VAL_ 712 POSDEVICE_SIGNAL_TO_LOW 0 "no" 1 "yes" ;
VAL_ 712 POSDEVICE_SIGNAL_TO_HIGH 0 "no" 1 "yes" ;
VAL_ 712 RESOLVER_CALIBRATION_FAILED 0 "no" 1 "yes" ;
VAL_ 712 SYSTEM_FAULT 0 "no" 1 "yes" ;
VAL_ 712 INTERLOCK_OPEN 0 "no" 1 "yes" ;
VAL_ 712 APPC_HAS_GATE_DRIVER_DISABLED 0 "no" 1 "yes" ;
VAL_ 712 MOTOR_STALL_ERROR 0 "no" 1 "yes" ;
VAL_ 712 AMBIENT_TEMPERATURE_WARNING 0 "no" 1 "yes" ;
VAL_ 712 AMBIENT_OVERTEMPERATURE 0 "no" 1 "yes" ;
VAL_ 712 AMBIENT_TEMPSENSOR_ERROR 0 "no" 1 "yes" ;
VAL_ 712 POWERMODULE_CLAMPING_TIMEOUT 0 "no" 1 "yes" ;
VAL_ 712 DCBUS_RIPPLE_TO_HIGH 0 "no" 1 "yes" ;
VAL_ 712 MOTOR_I2XT_WARNING 0 "no" 1 "yes" ;
VAL_ 712 MOTOR_I2XT_ERROR 0 "no" 1 "yes" ;
VAL_ 712 MOTOR_FIELDWEAKENING_ERROR 0 "no" 1 "yes" ;
VAL_ 712 INVALID_PARAMETER_COMBINATION 0 "no" 1 "yes" ;
VAL_ 712 PLUG_COVER_SENSOR_SIGNAL_LOW 0 "no" 1 "yes" ;
VAL_ 712 MOTOR_CONNECTION_TEST_FAILED 0 "no" 1 "yes" ;
VAL_ 712 POWERMODULE_IXT_WARNING 0 "no" 1 "yes" ;
VAL_ 712 ISOLATION_FAULT 0 "no" 1 "yes" ;
VAL_ 713 Inverter_B_Statusword_9 0 "NotReadyToSwitchOn" 64 "SwitchOnDisabled" 80 "SwitchOnDisabled" 96 "SwitchOnDisabled" 112 "SwitchOnDisabled" 33 "ReadyToSwitchOn" 49 "ReadyToSwitchOn" 35 "SwitchedOn" 51 "SwitchedOn" 39 "OperationEnabled" 55 "OperationEnabled" 7 "QuickStopActive" 23 "QuickStopActive" 15 "FaultReactionActive" 31 "FaultReactionActive" 47 "FaultReactionActive" 63 "FaultReactionActive" 8 "Fault" 24 "Fault" 40 "Fault" 56 "Fault" ;
VAL_ 713 EVENTBUFFER_NEW_EVENT 0 "no" 1 "yes" ;
VAL_ 713 EVENTBUFFER_OVERFLOW 0 "no" 1 "yes" ;
VAL_ 713 POWERMODULE_TRIPZONE_OVERCURRE 0 "no" 1 "yes" ;
VAL_ 713 POWERMODULE_CURRENT_OFFSET_INI 0 "no" 1 "yes" ;
VAL_ 713 POWERMODULE_TEMPSENSOR_ERROR 0 "no" 1 "yes" ;
VAL_ 713 POWERMODULE_TEMPERATURE_WARNIN 0 "no" 1 "yes" ;
VAL_ 713 POWERMODULE_OVERTEMPERATURE 0 "no" 1 "yes" ;
VAL_ 713 POWERMODULE_IXT_FAULT 0 "no" 1 "yes" ;
VAL_ 713 POWERMODULE_SW_OVERCURRENT 0 "no" 1 "yes" ;
VAL_ 713 POWERMODULE_PATTERNDATA_INCONS 0 "no" 1 "yes" ;
VAL_ 713 DCBUS_TRIPZONE_OVERVOLTAGE 0 "no" 1 "yes" ;
VAL_ 713 DCBUS_SW_OVERVOLTAGE 0 "no" 1 "yes" ;
VAL_ 713 DCBUS_SW_UNDERVOLTAGE 0 "no" 1 "yes" ;
VAL_ 713 NEIGHBOUR_FAULT 0 "no" 1 "yes" ;
VAL_ 713 MOTOR_TEMPSENSOR_ERROR 0 "no" 1 "yes" ;
VAL_ 713 MOTOR_TEMPERATURE_WARNING 0 "no" 1 "yes" ;
VAL_ 713 MOTOR_OVERTEMPERATURE 0 "no" 1 "yes" ;
VAL_ 713 MOTOR_STATOR_FREQ_TO_HIGH 0 "no" 1 "yes" ;
VAL_ 713 SUPPLYVOLTAGE_ERROR 0 "no" 1 "yes" ;
VAL_ 713 RPDO_TIMEOUT 0 "no" 1 "yes" ;
VAL_ 713 NMT_NOT_OPERATIONAL 0 "no" 1 "yes" ;
VAL_ 713 TASKOVERRUN 0 "no" 1 "yes" ;
VAL_ 713 NETSYNC_ERROR 0 "no" 1 "yes" ;
VAL_ 713 POSDEVICE_SIGNAL_TO_LOW 0 "no" 1 "yes" ;
VAL_ 713 POSDEVICE_SIGNAL_TO_HIGH 0 "no" 1 "yes" ;
VAL_ 713 RESOLVER_CALIBRATION_FAILED 0 "no" 1 "yes" ;
VAL_ 713 SYSTEM_FAULT 0 "no" 1 "yes" ;
VAL_ 713 INTERLOCK_OPEN 0 "no" 1 "yes" ;
VAL_ 713 APPC_HAS_GATE_DRIVER_DISABLED 0 "no" 1 "yes" ;
VAL_ 713 MOTOR_STALL_ERROR 0 "no" 1 "yes" ;
VAL_ 713 AMBIENT_TEMPERATURE_WARNING 0 "no" 1 "yes" ;
VAL_ 713 AMBIENT_OVERTEMPERATURE 0 "no" 1 "yes" ;
VAL_ 713 AMBIENT_TEMPSENSOR_ERROR 0 "no" 1 "yes" ;
VAL_ 713 POWERMODULE_CLAMPING_TIMEOUT 0 "no" 1 "yes" ;
VAL_ 713 DCBUS_RIPPLE_TO_HIGH 0 "no" 1 "yes" ;
VAL_ 713 MOTOR_I2XT_WARNING 0 "no" 1 "yes" ;
VAL_ 713 MOTOR_I2XT_ERROR 0 "no" 1 "yes" ;
VAL_ 713 MOTOR_FIELDWEAKENING_ERROR 0 "no" 1 "yes" ;
VAL_ 713 INVALID_PARAMETER_COMBINATION 0 "no" 1 "yes" ;
VAL_ 713 PLUG_COVER_SENSOR_SIGNAL_LOW 0 "no" 1 "yes" ;
VAL_ 713 MOTOR_CONNECTION_TEST_FAILED 0 "no" 1 "yes" ;
VAL_ 713 POWERMODULE_IXT_WARNING 0 "no" 1 "yes" ;
VAL_ 713 ISOLATION_FAULT 0 "no" 1 "yes" ;
VAL_ 714 Inverter_B_Statusword_10 0 "NotReadyToSwitchOn" 64 "SwitchOnDisabled" 80 "SwitchOnDisabled" 96 "SwitchOnDisabled" 112 "SwitchOnDisabled" 33 "ReadyToSwitchOn" 49 "ReadyToSwitchOn" 35 "SwitchedOn" 51 "SwitchedOn" 39 "OperationEnabled" 55 "OperationEnabled" 7 "QuickStopActive" 23 "QuickStopActive" 15 "FaultReactionActive" 31 "FaultReactionActive" 47 "FaultReactionActive" 63 "FaultReactionActive" 8 "Fault" 24 "Fault" 40 "Fault" 56 "Fault" ;
VAL_ 714 EVENTBUFFER_NEW_EVENT 0 "no" 1 "yes" ;
VAL_ 714 EVENTBUFFER_OVERFLOW 0 "no" 1 "yes" ;
VAL_ 714 POWERMODULE_TRIPZONE_OVERCURRE 0 "no" 1 "yes" ;
VAL_ 714 POWERMODULE_CURRENT_OFFSET_INI 0 "no" 1 "yes" ;
VAL_ 714 POWERMODULE_TEMPSENSOR_ERROR 0 "no" 1 "yes" ;
VAL_ 714 POWERMODULE_TEMPERATURE_WARNIN 0 "no" 1 "yes" ;
VAL_ 714 POWERMODULE_OVERTEMPERATURE 0 "no" 1 "yes" ;
VAL_ 714 POWERMODULE_IXT_FAULT 0 "no" 1 "yes" ;
VAL_ 714 POWERMODULE_SW_OVERCURRENT 0 "no" 1 "yes" ;
VAL_ 714 POWERMODULE_PATTERNDATA_INCONS 0 "no" 1 "yes" ;
VAL_ 714 DCBUS_TRIPZONE_OVERVOLTAGE 0 "no" 1 "yes" ;
VAL_ 714 DCBUS_SW_OVERVOLTAGE 0 "no" 1 "yes" ;
VAL_ 714 DCBUS_SW_UNDERVOLTAGE 0 "no" 1 "yes" ;
VAL_ 714 NEIGHBOUR_FAULT 0 "no" 1 "yes" ;
VAL_ 714 MOTOR_TEMPSENSOR_ERROR 0 "no" 1 "yes" ;
VAL_ 714 MOTOR_TEMPERATURE_WARNING 0 "no" 1 "yes" ;
VAL_ 714 MOTOR_OVERTEMPERATURE 0 "no" 1 "yes" ;
VAL_ 714 MOTOR_STATOR_FREQ_TO_HIGH 0 "no" 1 "yes" ;
VAL_ 714 SUPPLYVOLTAGE_ERROR 0 "no" 1 "yes" ;
VAL_ 714 RPDO_TIMEOUT 0 "no" 1 "yes" ;
VAL_ 714 NMT_NOT_OPERATIONAL 0 "no" 1 "yes" ;
VAL_ 714 TASKOVERRUN 0 "no" 1 "yes" ;
VAL_ 714 NETSYNC_ERROR 0 "no" 1 "yes" ;
VAL_ 714 POSDEVICE_SIGNAL_TO_LOW 0 "no" 1 "yes" ;
VAL_ 714 POSDEVICE_SIGNAL_TO_HIGH 0 "no" 1 "yes" ;
VAL_ 714 RESOLVER_CALIBRATION_FAILED 0 "no" 1 "yes" ;
VAL_ 714 SYSTEM_FAULT 0 "no" 1 "yes" ;
VAL_ 714 INTERLOCK_OPEN 0 "no" 1 "yes" ;
VAL_ 714 APPC_HAS_GATE_DRIVER_DISABLED 0 "no" 1 "yes" ;
VAL_ 714 MOTOR_STALL_ERROR 0 "no" 1 "yes" ;
VAL_ 714 AMBIENT_TEMPERATURE_WARNING 0 "no" 1 "yes" ;
VAL_ 714 AMBIENT_OVERTEMPERATURE 0 "no" 1 "yes" ;
VAL_ 714 AMBIENT_TEMPSENSOR_ERROR 0 "no" 1 "yes" ;
VAL_ 714 POWERMODULE_CLAMPING_TIMEOUT 0 "no" 1 "yes" ;
VAL_ 714 DCBUS_RIPPLE_TO_HIGH 0 "no" 1 "yes" ;
VAL_ 714 MOTOR_I2XT_WARNING 0 "no" 1 "yes" ;
VAL_ 714 MOTOR_I2XT_ERROR 0 "no" 1 "yes" ;
VAL_ 714 MOTOR_FIELDWEAKENING_ERROR 0 "no" 1 "yes" ;
VAL_ 714 INVALID_PARAMETER_COMBINATION 0 "no" 1 "yes" ;
VAL_ 714 PLUG_COVER_SENSOR_SIGNAL_LOW 0 "no" 1 "yes" ;
VAL_ 714 MOTOR_CONNECTION_TEST_FAILED 0 "no" 1 "yes" ;
VAL_ 714 POWERMODULE_IXT_WARNING 0 "no" 1 "yes" ;
VAL_ 714 ISOLATION_FAULT 0 "no" 1 "yes" ;
VAL_ 715 Inverter_B_Statusword_11 0 "NotReadyToSwitchOn" 64 "SwitchOnDisabled" 80 "SwitchOnDisabled" 96 "SwitchOnDisabled" 112 "SwitchOnDisabled" 33 "ReadyToSwitchOn" 49 "ReadyToSwitchOn" 35 "SwitchedOn" 51 "SwitchedOn" 39 "OperationEnabled" 55 "OperationEnabled" 7 "QuickStopActive" 23 "QuickStopActive" 15 "FaultReactionActive" 31 "FaultReactionActive" 47 "FaultReactionActive" 63 "FaultReactionActive" 8 "Fault" 24 "Fault" 40 "Fault" 56 "Fault" ;
VAL_ 715 EVENTBUFFER_NEW_EVENT 0 "no" 1 "yes" ;
VAL_ 715 EVENTBUFFER_OVERFLOW 0 "no" 1 "yes" ;
VAL_ 715 POWERMODULE_TRIPZONE_OVERCURRE 0 "no" 1 "yes" ;
VAL_ 715 POWERMODULE_CURRENT_OFFSET_INI 0 "no" 1 "yes" ;
VAL_ 715 POWERMODULE_TEMPSENSOR_ERROR 0 "no" 1 "yes" ;
VAL_ 715 POWERMODULE_TEMPERATURE_WARNIN 0 "no" 1 "yes" ;
VAL_ 715 POWERMODULE_OVERTEMPERATURE 0 "no" 1 "yes" ;
VAL_ 715 POWERMODULE_IXT_FAULT 0 "no" 1 "yes" ;
VAL_ 715 POWERMODULE_SW_OVERCURRENT 0 "no" 1 "yes" ;
VAL_ 715 POWERMODULE_PATTERNDATA_INCONS 0 "no" 1 "yes" ;
VAL_ 715 DCBUS_TRIPZONE_OVERVOLTAGE 0 "no" 1 "yes" ;
VAL_ 715 DCBUS_SW_OVERVOLTAGE 0 "no" 1 "yes" ;
VAL_ 715 DCBUS_SW_UNDERVOLTAGE 0 "no" 1 "yes" ;
VAL_ 715 NEIGHBOUR_FAULT 0 "no" 1 "yes" ;
VAL_ 715 MOTOR_TEMPSENSOR_ERROR 0 "no" 1 "yes" ;
VAL_ 715 MOTOR_TEMPERATURE_WARNING 0 "no" 1 "yes" ;
VAL_ 715 MOTOR_OVERTEMPERATURE 0 "no" 1 "yes" ;
VAL_ 715 MOTOR_STATOR_FREQ_TO_HIGH 0 "no" 1 "yes" ;
VAL_ 715 SUPPLYVOLTAGE_ERROR 0 "no" 1 "yes" ;
VAL_ 715 RPDO_TIMEOUT 0 "no" 1 "yes" ;
VAL_ 715 NMT_NOT_OPERATIONAL 0 "no" 1 "yes" ;
VAL_ 715 TASKOVERRUN 0 "no" 1 "yes" ;
VAL_ 715 NETSYNC_ERROR 0 "no" 1 "yes" ;
VAL_ 715 POSDEVICE_SIGNAL_TO_LOW 0 "no" 1 "yes" ;
VAL_ 715 POSDEVICE_SIGNAL_TO_HIGH 0 "no" 1 "yes" ;
VAL_ 715 RESOLVER_CALIBRATION_FAILED 0 "no" 1 "yes" ;
VAL_ 715 SYSTEM_FAULT 0 "no" 1 "yes" ;
VAL_ 715 INTERLOCK_OPEN 0 "no" 1 "yes" ;
VAL_ 715 APPC_HAS_GATE_DRIVER_DISABLED 0 "no" 1 "yes" ;
VAL_ 715 MOTOR_STALL_ERROR 0 "no" 1 "yes" ;
VAL_ 715 AMBIENT_TEMPERATURE_WARNING 0 "no" 1 "yes" ;
VAL_ 715 AMBIENT_OVERTEMPERATURE 0 "no" 1 "yes" ;
VAL_ 715 AMBIENT_TEMPSENSOR_ERROR 0 "no" 1 "yes" ;
VAL_ 715 POWERMODULE_CLAMPING_TIMEOUT 0 "no" 1 "yes" ;
VAL_ 715 DCBUS_RIPPLE_TO_HIGH 0 "no" 1 "yes" ;
VAL_ 715 MOTOR_I2XT_WARNING 0 "no" 1 "yes" ;
VAL_ 715 MOTOR_I2XT_ERROR 0 "no" 1 "yes" ;
VAL_ 715 MOTOR_FIELDWEAKENING_ERROR 0 "no" 1 "yes" ;
VAL_ 715 INVALID_PARAMETER_COMBINATION 0 "no" 1 "yes" ;
VAL_ 715 PLUG_COVER_SENSOR_SIGNAL_LOW 0 "no" 1 "yes" ;
VAL_ 715 MOTOR_CONNECTION_TEST_FAILED 0 "no" 1 "yes" ;
VAL_ 715 POWERMODULE_IXT_WARNING 0 "no" 1 "yes" ;
VAL_ 715 ISOLATION_FAULT 0 "no" 1 "yes" ;
VAL_ 716 Inverter_B_Statusword_12 0 "NotReadyToSwitchOn" 64 "SwitchOnDisabled" 80 "SwitchOnDisabled" 96 "SwitchOnDisabled" 112 "SwitchOnDisabled" 33 "ReadyToSwitchOn" 49 "ReadyToSwitchOn" 35 "SwitchedOn" 51 "SwitchedOn" 39 "OperationEnabled" 55 "OperationEnabled" 7 "QuickStopActive" 23 "QuickStopActive" 15 "FaultReactionActive" 31 "FaultReactionActive" 47 "FaultReactionActive" 63 "FaultReactionActive" 8 "Fault" 24 "Fault" 40 "Fault" 56 "Fault" ;
VAL_ 716 EVENTBUFFER_NEW_EVENT 0 "no" 1 "yes" ;
VAL_ 716 EVENTBUFFER_OVERFLOW 0 "no" 1 "yes" ;
VAL_ 716 POWERMODULE_TRIPZONE_OVERCURRE 0 "no" 1 "yes" ;
VAL_ 716 POWERMODULE_CURRENT_OFFSET_INI 0 "no" 1 "yes" ;
VAL_ 716 POWERMODULE_TEMPSENSOR_ERROR 0 "no" 1 "yes" ;
VAL_ 716 POWERMODULE_TEMPERATURE_WARNIN 0 "no" 1 "yes" ;
VAL_ 716 POWERMODULE_OVERTEMPERATURE 0 "no" 1 "yes" ;
VAL_ 716 POWERMODULE_IXT_FAULT 0 "no" 1 "yes" ;
VAL_ 716 POWERMODULE_SW_OVERCURRENT 0 "no" 1 "yes" ;
VAL_ 716 POWERMODULE_PATTERNDATA_INCONS 0 "no" 1 "yes" ;
VAL_ 716 DCBUS_TRIPZONE_OVERVOLTAGE 0 "no" 1 "yes" ;
VAL_ 716 DCBUS_SW_OVERVOLTAGE 0 "no" 1 "yes" ;
VAL_ 716 DCBUS_SW_UNDERVOLTAGE 0 "no" 1 "yes" ;
VAL_ 716 NEIGHBOUR_FAULT 0 "no" 1 "yes" ;
VAL_ 716 MOTOR_TEMPSENSOR_ERROR 0 "no" 1 "yes" ;
VAL_ 716 MOTOR_TEMPERATURE_WARNING 0 "no" 1 "yes" ;
VAL_ 716 MOTOR_OVERTEMPERATURE 0 "no" 1 "yes" ;
VAL_ 716 MOTOR_STATOR_FREQ_TO_HIGH 0 "no" 1 "yes" ;
VAL_ 716 SUPPLYVOLTAGE_ERROR 0 "no" 1 "yes" ;
VAL_ 716 RPDO_TIMEOUT 0 "no" 1 "yes" ;
VAL_ 716 NMT_NOT_OPERATIONAL 0 "no" 1 "yes" ;
VAL_ 716 TASKOVERRUN 0 "no" 1 "yes" ;
VAL_ 716 NETSYNC_ERROR 0 "no" 1 "yes" ;
VAL_ 716 POSDEVICE_SIGNAL_TO_LOW 0 "no" 1 "yes" ;
VAL_ 716 POSDEVICE_SIGNAL_TO_HIGH 0 "no" 1 "yes" ;
VAL_ 716 RESOLVER_CALIBRATION_FAILED 0 "no" 1 "yes" ;
VAL_ 716 SYSTEM_FAULT 0 "no" 1 "yes" ;
VAL_ 716 INTERLOCK_OPEN 0 "no" 1 "yes" ;
VAL_ 716 APPC_HAS_GATE_DRIVER_DISABLED 0 "no" 1 "yes" ;
VAL_ 716 MOTOR_STALL_ERROR 0 "no" 1 "yes" ;
VAL_ 716 AMBIENT_TEMPERATURE_WARNING 0 "no" 1 "yes" ;
VAL_ 716 AMBIENT_OVERTEMPERATURE 0 "no" 1 "yes" ;
VAL_ 716 AMBIENT_TEMPSENSOR_ERROR 0 "no" 1 "yes" ;
VAL_ 716 POWERMODULE_CLAMPING_TIMEOUT 0 "no" 1 "yes" ;
VAL_ 716 DCBUS_RIPPLE_TO_HIGH 0 "no" 1 "yes" ;
VAL_ 716 MOTOR_I2XT_WARNING 0 "no" 1 "yes" ;
VAL_ 716 MOTOR_I2XT_ERROR 0 "no" 1 "yes" ;
VAL_ 716 MOTOR_FIELDWEAKENING_ERROR 0 "no" 1 "yes" ;
VAL_ 716 INVALID_PARAMETER_COMBINATION 0 "no" 1 "yes" ;
VAL_ 716 PLUG_COVER_SENSOR_SIGNAL_LOW 0 "no" 1 "yes" ;
VAL_ 716 MOTOR_CONNECTION_TEST_FAILED 0 "no" 1 "yes" ;
VAL_ 716 POWERMODULE_IXT_WARNING 0 "no" 1 "yes" ;
VAL_ 716 ISOLATION_FAULT 0 "no" 1 "yes" ;
VAL_ 717 Inverter_B_Statusword_13 0 "NotReadyToSwitchOn" 64 "SwitchOnDisabled" 80 "SwitchOnDisabled" 96 "SwitchOnDisabled" 112 "SwitchOnDisabled" 33 "ReadyToSwitchOn" 49 "ReadyToSwitchOn" 35 "SwitchedOn" 51 "SwitchedOn" 39 "OperationEnabled" 55 "OperationEnabled" 7 "QuickStopActive" 23 "QuickStopActive" 15 "FaultReactionActive" 31 "FaultReactionActive" 47 "FaultReactionActive" 63 "FaultReactionActive" 8 "Fault" 24 "Fault" 40 "Fault" 56 "Fault" ;
VAL_ 717 EVENTBUFFER_NEW_EVENT 0 "no" 1 "yes" ;
VAL_ 717 EVENTBUFFER_OVERFLOW 0 "no" 1 "yes" ;
VAL_ 717 POWERMODULE_TRIPZONE_OVERCURRE 0 "no" 1 "yes" ;
VAL_ 717 POWERMODULE_CURRENT_OFFSET_INI 0 "no" 1 "yes" ;
VAL_ 717 POWERMODULE_TEMPSENSOR_ERROR 0 "no" 1 "yes" ;
VAL_ 717 POWERMODULE_TEMPERATURE_WARNIN 0 "no" 1 "yes" ;
VAL_ 717 POWERMODULE_OVERTEMPERATURE 0 "no" 1 "yes" ;
VAL_ 717 POWERMODULE_IXT_FAULT 0 "no" 1 "yes" ;
VAL_ 717 POWERMODULE_SW_OVERCURRENT 0 "no" 1 "yes" ;
VAL_ 717 POWERMODULE_PATTERNDATA_INCONS 0 "no" 1 "yes" ;
VAL_ 717 DCBUS_TRIPZONE_OVERVOLTAGE 0 "no" 1 "yes" ;
VAL_ 717 DCBUS_SW_OVERVOLTAGE 0 "no" 1 "yes" ;
VAL_ 717 DCBUS_SW_UNDERVOLTAGE 0 "no" 1 "yes" ;
VAL_ 717 NEIGHBOUR_FAULT 0 "no" 1 "yes" ;
VAL_ 717 MOTOR_TEMPSENSOR_ERROR 0 "no" 1 "yes" ;
VAL_ 717 MOTOR_TEMPERATURE_WARNING 0 "no" 1 "yes" ;
VAL_ 717 MOTOR_OVERTEMPERATURE 0 "no" 1 "yes" ;
VAL_ 717 MOTOR_STATOR_FREQ_TO_HIGH 0 "no" 1 "yes" ;
VAL_ 717 SUPPLYVOLTAGE_ERROR 0 "no" 1 "yes" ;
VAL_ 717 RPDO_TIMEOUT 0 "no" 1 "yes" ;
VAL_ 717 NMT_NOT_OPERATIONAL 0 "no" 1 "yes" ;
VAL_ 717 TASKOVERRUN 0 "no" 1 "yes" ;
VAL_ 717 NETSYNC_ERROR 0 "no" 1 "yes" ;
VAL_ 717 POSDEVICE_SIGNAL_TO_LOW 0 "no" 1 "yes" ;
VAL_ 717 POSDEVICE_SIGNAL_TO_HIGH 0 "no" 1 "yes" ;
VAL_ 717 RESOLVER_CALIBRATION_FAILED 0 "no" 1 "yes" ;
VAL_ 717 SYSTEM_FAULT 0 "no" 1 "yes" ;
VAL_ 717 INTERLOCK_OPEN 0 "no" 1 "yes" ;
VAL_ 717 APPC_HAS_GATE_DRIVER_DISABLED 0 "no" 1 "yes" ;
VAL_ 717 MOTOR_STALL_ERROR 0 "no" 1 "yes" ;
VAL_ 717 AMBIENT_TEMPERATURE_WARNING 0 "no" 1 "yes" ;
VAL_ 717 AMBIENT_OVERTEMPERATURE 0 "no" 1 "yes" ;
VAL_ 717 AMBIENT_TEMPSENSOR_ERROR 0 "no" 1 "yes" ;
VAL_ 717 POWERMODULE_CLAMPING_TIMEOUT 0 "no" 1 "yes" ;
VAL_ 717 DCBUS_RIPPLE_TO_HIGH 0 "no" 1 "yes" ;
VAL_ 717 MOTOR_I2XT_WARNING 0 "no" 1 "yes" ;
VAL_ 717 MOTOR_I2XT_ERROR 0 "no" 1 "yes" ;
VAL_ 717 MOTOR_FIELDWEAKENING_ERROR 0 "no" 1 "yes" ;
VAL_ 717 INVALID_PARAMETER_COMBINATION 0 "no" 1 "yes" ;
VAL_ 717 PLUG_COVER_SENSOR_SIGNAL_LOW 0 "no" 1 "yes" ;
VAL_ 717 MOTOR_CONNECTION_TEST_FAILED 0 "no" 1 "yes" ;
VAL_ 717 POWERMODULE_IXT_WARNING 0 "no" 1 "yes" ;
VAL_ 717 ISOLATION_FAULT 0 "no" 1 "yes" ;
VAL_ 0 commmand_specifier 1 "Start" 2 "Stop" 128 "Enter Pre-Operational" 129 "Reset Node" 130 "Reset Communication" ;
